VERSION "Generated from PQ35_46 ACAN KMatrix"

NS_ :

BS_:

BU_: XXX AFS Airbag Allrad AppGW_SK BAP_Tester BMS_Hybrid Bremse_ESP_AU714 Bremse_ESP_EPB_EBC460Vi Bremse_MK100_ESC Bremse_MK60EC Bremse_MK70MABS Bremse_TRW_EBC450M Bremse_TRW_ESP Daempfer EPB_TRW EPB_TRW_VW411CS ESP_AU316 FLA Gateway_PQ35 Getriebe_AG6 Getriebe_DL800_R8 Getriebe_DL800_ZSG_R8 Getriebe_DQ Getriebe_DQ_Hyb Getriebe_Sele Gurtmikro_PQ35 HCA LEH_Hybrid LH_EPS_APA LH_EPS_ZF_2G LH_EPS_ZF_3G LPG_Interface_Box LWR LWS Magne_Ride Motor_Diesel Motor_Hybrid Motor_Otto Motor_Slave PDC_PLA Quersperre_VAQ RKA_Plus SAK Waehlhebel Waehlhebel_Sele

BO_ 914 mGate_Komf_2: 8 XXX
 SG_ GK2_Sta_LSM : 0|1@1+ (1,0) [0|1] "" XXX
 SG_ GK2_Sta_Lichtsensor : 1|1@1+ (1,0) [0|1] "" AFS
 SG_ GK2_Sta_Licht1 : 2|1@1+ (1,0) [0|1] "" AFS,AppGW_SK,HCA
 SG_ GK2_Sta_VSG : 3|1@1+ (1,0) [0|1] "" Airbag,Motor_Otto,PDC_PLA
 SG_ GK2_Sta_Schluessel : 4|1@1+ (1,0) [0|1] "" Daempfer,PDC_PLA
 SG_ GK2_Sta_Profil : 5|1@1+ (1,0) [0|1] "" PDC_PLA
 SG_ GK2_Sta_Clima2 : 6|1@1+ (1,0) [0|1] "" Motor_Diesel,Motor_Otto
 SG_ GK2_Sta_BSG4 : 7|1@1+ (1,0) [0|1] "" Motor_Diesel,Motor_Otto
 SG_ GK2_Sta_Kessy_4 : 8|1@1+ (1,0) [0|1] "" Motor_Diesel,Motor_Otto
 SG_ BS4_Gleitende_Leuchtw_Anf : 9|1@1+ (1,0) [0|1] "" XXX
 SG_ BS4_GLW_Fernlicht_Anf : 10|1@1+ (1,0) [0|1] "" XXX
 SG_ GK2_Blk_L_Kontrolle : 11|1@1+ (1,0) [1|1] "" HCA
 SG_ GK2_Blk_R_Kontrolle : 12|1@1+ (1,0) [1|1] "" HCA
 SG_ LS1_Lichthupe : 13|1@1+ (1,0) [0|1] "" AFS,LWR
 SG_ GK2_LS_KomFehler : 14|1@1+ (1,0) [0|1] "" AFS
 SG_ GK2_LS_def : 15|1@1+ (1,0) [0|1] "" AFS
 SG_ GK2_Helligkeit : 16|3@1+ (714.286,0) [0|5000.002] "Unit_Lux" AFS
 SG_ GK2_VD_zu_ver : 19|1@1+ (1,0) [0|1] "" PDC_PLA
 SG_ GK2_VD_entriegelt : 20|1@1+ (1,0) [0|1] "" PDC_PLA
 SG_ GK2_VD_offen_ver : 21|1@1+ (1,0) [0|1] "" Airbag,Motor_Otto,PDC_PLA
 SG_ GK2_Verdeck_Anf : 22|1@1+ (1,0) [0|1] "" PDC_PLA
 SG_ GK2_VDKD_auf : 23|1@1+ (1,0) [0|1] "" PDC_PLA
 SG_ GK2_Schluessel : 24|4@1+ (1,0) [0|0] "" PDC_PLA
 SG_ GK2_Hardtop : 28|1@1+ (1,0) [0|1] "" PDC_PLA
 SG_ GK2_AFL_Schalter : 29|1@1+ (1,0) [0|1] "" AFS
 SG_ GK2_Nebelschluss : 30|1@1+ (1,0) [0|1] "" AFS,AppGW_SK
 SG_ GK2_EM_LIN_ungueltig : 31|1@1+ (1,0) [0|1] "" Motor_Diesel,Motor_Otto
 SG_ GK2_Profil : 32|4@1+ (1,0) [0|15] "" PDC_PLA
 SG_ GK2_Kl_StSt_Info : 36|2@1+ (1,0) [0|3] "" Motor_Diesel,Motor_Otto
 SG_ GK2_BSG_StSt_Info : 38|2@1+ (1,0) [0|3] "" Motor_Diesel,Motor_Otto
 SG_ GK2_BEM_P_Generator : 40|8@1+ (50,0) [0|12700] "Unit_Watt" Motor_Diesel,Motor_Otto
 SG_ GK2_BEM_Abschaltstufen : 48|3@1+ (1,0) [0|3] "" XXX
 SG_ GK2_BEM_DFM : 51|5@1+ (3.225,0.025) [0.025|100] "Unit_PerCent" Motor_Diesel,Motor_Otto
 SG_ GK2_Kessy_StSt_Info : 56|2@1+ (1,0) [0|3] "" Motor_Diesel,Motor_Otto
 SG_ GK2_BEM_StSt_Info : 58|2@1+ (1,0) [0|3] "" Motor_Diesel,Motor_Otto
 SG_ BEM_Segel_Info : 60|2@1+ (1,0) [0|3] "" Getriebe_AG6,Getriebe_DQ,Getriebe_DQ_Hyb,Motor_Diesel,Motor_Otto
 SG_ LS1_FAS_Taster : 62|1@1+ (1,0) [0|1] "" XXX
 SG_ LS1_Fehler_FAS_Taster : 63|1@1+ (1,0) [0|1] "" XXX

BO_ 915 mGate_Komf_3: 8 XXX
 SG_ GK3_Sta_Kessy_4 : 0|1@1+ (1,0) [0|1] "" XXX
 SG_ GK3_Sta_BCM_KY1 : 1|1@1+ (1,0) [0|1] "" XXX
 SG_ GK3_Sta_Clima_3 : 2|1@1+ (1,0) [0|1] "" Motor_Diesel,Motor_Otto
 SG_ GK3_Sta_TSG_FT_3 : 3|1@1+ (1,0) [0|1] "" XXX
 SG_ GK3_Sta_HD_1 : 4|1@1+ (1,0) [0|1] "" PDC_PLA
 SG_ GK3_Sta_Memory_1 : 5|1@1+ (1,0) [0|1] "" XXX
 SG_ GK3_Sta_BSG4 : 6|1@1+ (1,0) [0|1] "" Motor_Hybrid
 SG_ GK3_Sta_MFG1 : 7|1@1+ (1,0) [0|1] "" Bremse_MK100_ESC
 SG_ GK3_KY4_Meldungen : 8|4@1+ (1,0) [0|4] "" XXX
 SG_ GK3_KY4_Gong_600 : 12|1@1+ (1,0) [0|1] "" XXX
 SG_ MG1_ext_Last : 13|1@1+ (1,0) [0|1] "" Bremse_MK100_ESC
 SG_ GK3_KY4_PassAL_Menue : 14|1@1+ (1,0) [0|1] "" XXX
 SG_ GK3_KY4_PassAL_akt : 15|1@1+ (1,0) [0|1] "" XXX
 SG_ GK3_BK1_IDGeb_1_Sta : 16|3@1+ (1,0) [0|2] "" XXX
 SG_ GK3_BK1_IDGeb_2_Sta : 19|3@1+ (1,0) [0|2] "" XXX
 SG_ ME1_EasyEntry_Menu : 22|1@1+ (1,0) [0|1] "" XXX
 SG_ ME1_EasyEntry_aktiv : 23|1@1+ (1,0) [0|1] "" XXX
 SG_ GK3_BK1_IDGeb_3_Sta : 24|3@1+ (1,0) [0|2] "" XXX
 SG_ GK3_BK1_IDGeb_4_Sta : 27|3@1+ (1,0) [0|2] "" XXX
 SG_ GK3_BK1_Anlern_Info : 30|1@1+ (1,0) [0|1] "" XXX
 SG_ CL3_Defrost : 31|1@1+ (1,0) [0|1] "" XXX
 SG_ CL3_SH_Wasserpumpe : 32|1@1+ (1,0) [0|1] "" XXX
 SG_ FT3_Auto_eKiSi_Menu : 33|1@1+ (1,0) [0|1] "" XXX
 SG_ FT3_Auto_eKiSi_Aktiv : 34|1@1+ (1,0) [0|1] "" XXX
 SG_ MKE_Texte : 35|3@1+ (1,0) [0|2] "" XXX
 SG_ HSA_unplausibel : 38|1@1+ (1,0) [0|1] "" XXX
 SG_ FT_Kisi_Fehler : 39|1@1+ (1,0) [0|1] "" XXX
 SG_ BCM_Tankwunsch : 40|2@1+ (1,0) [0|3] "" Motor_Hybrid
 SG_ BCM_Hybrid_StartStopp_Taste : 42|1@1+ (1,0) [0|1] "" XXX
 SG_ KL_nachtr_Stopp_Anf : 43|1@1+ (1,0) [0|1] "" Motor_Diesel,Motor_Otto
 SG_ HD1_Endstellung_oben : 44|1@1+ (1,0) [0|1] "" PDC_PLA
 SG_ HD1_Endstellung_unten : 45|1@1+ (1,0) [0|1] "" PDC_PLA
 SG_ BCM_Bremslicht_defekt : 46|1@1+ (1,0) [0|1] "" XXX
 SG_ LIA_AFL_Schalter : 47|1@1+ (1,0) [0|1] "" XXX
 SG_ HD1_Position : 56|8@1+ (0.5,0) [0|100] "Unit_PerCent" PDC_PLA

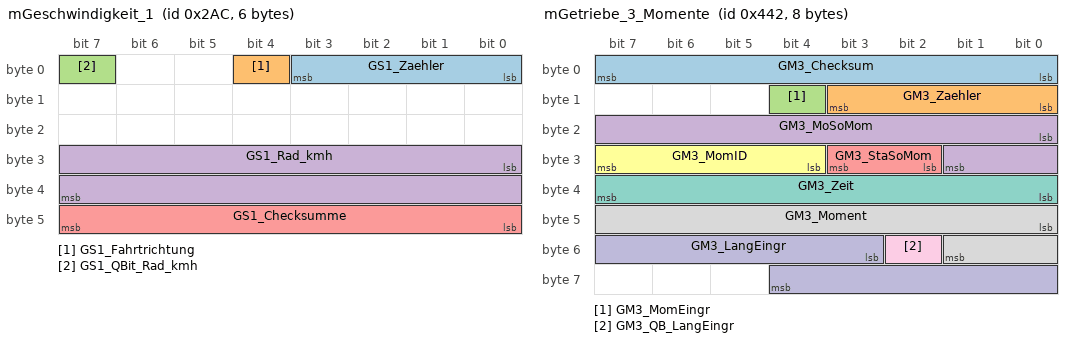
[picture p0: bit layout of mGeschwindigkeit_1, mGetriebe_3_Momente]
BO_ 684 mGeschwindigkeit_1: 6 XXX
 SG_ GS1_Zaehler : 0|4@1+ (1,0) [0|15] "" Magne_Ride
 SG_ GS1_Fahrtrichtung : 4|1@1+ (1,0) [0|1] "" XXX
 SG_ GS1_QBit_Rad_kmh : 7|1@1+ (1,0) [0|1] "" Magne_Ride
 SG_ GS1_Rad_kmh : 24|16@1+ (0.01,0) [0|654.15] "Unit_KiloMeterPerHour" Magne_Ride,SAK
 SG_ GS1_Checksumme : 40|8@1+ (1,0) [0|255] "" Magne_Ride

BO_ 1344 mGetriebe_2: 8 XXX
 SG_ GE2_LFR_Adap : 0|1@1+ (1,0) [0|1] "" Gateway_PQ35,Motor_Hybrid
 SG_ GE2_Sta_SAS : 1|1@1+ (1,0) [0|1] "" Gateway_PQ35
 SG_ GE2_LowSpeedMode_gueltig : 2|1@1+ (1,0) [0|1] "" Bremse_MK100_ESC,Bremse_MK60EC,Gateway_PQ35,Motor_Hybrid
 SG_ GE2_Sta_ZwGas : 3|1@1+ (1,0) [0|1] "" Gateway_PQ35,Motor_Hybrid
 SG_ GE2_Zaehler : 4|4@1+ (1,0) [0|15] "" Gateway_PQ35,Motor_Hybrid
 SG_ GE2_LL_Solldz : 8|8@1+ (10,0) [0|2540] "Unit_MinutInver" Gateway_PQ35,Motor_Hybrid
 SG_ GE2_Grad_begr : 16|8@1+ (10,0) [0|2540] "Unit_NewtoMeterPerSecon" Gateway_PQ35,Motor_Hybrid
 SG_ GE2_Sync_Dz : 24|8@1+ (25,0) [0|6375] "Unit_MinutInver" Gateway_PQ35,Motor_Hybrid
 SG_ GE2_invSync_Dz : 32|8@1+ (-25,6375) [0|6375] "Unit_MinutInver" Gateway_PQ35,Motor_Hybrid
 SG_ GE2_Sync_Zeit : 40|8@1+ (20,0) [0|5080] "Unit_MilliSecon" Gateway_PQ35,Motor_Hybrid
 SG_ GE2_DZM_Daempf : 48|1@1+ (1,0) [0|1] "" Gateway_PQ35
 SG_ GE2_invMSB_Sync : 49|1@1+ (1,0) [0|1] "" Gateway_PQ35
 SG_ GE2_Gong : 50|1@1+ (1,0) [0|1] "" Gateway_PQ35
 SG_ GE2_Segeln_aktiv : 51|1@1+ (1,0) [0|1] "" Gateway_PQ35,Motor_Hybrid
 SG_ GE2_Shift_Lock : 52|1@1+ (1,0) [0|1] "" Gateway_PQ35
 SG_ GE2_Senderkennung : 53|1@1+ (1,0) [0|1] "" Allrad,AppGW_SK,Gateway_PQ35
 SG_ GE2_MSB_Sync : 54|1@1+ (1,0) [0|1] "" Gateway_PQ35
 SG_ GE2_WBA_Blinken : 55|1@1+ (1,0) [0|1] "" Gateway_PQ35,Motor_Hybrid
 SG_ GE2_Variante : 56|4@1+ (1,0) [0|15] "" Allrad,AppGW_SK,Gateway_PQ35,Waehlhebel_Sele
 SG_ GE2_5Gang : 60|4@1+ (1,0) [0|8] "" Gateway_PQ35
 SG_ GE2_PRNDL : 60|4@1+ (1,0) [0|6] "" Gateway_PQ35
 SG_ GE2_4Gang : 60|4@1+ (1,0) [0|8] "" Gateway_PQ35
 SG_ GE2_ASG : 60|4@1+ (1,0) [0|12] "" Gateway_PQ35
 SG_ GE2_Selespeed : 60|4@1+ (1,0) [0|14] "" Gateway_PQ35,Waehlhebel_Sele
 SG_ GE2_res_MUX5 : 60|4@1+ (1,0) [0|15] "" Gateway_PQ35
 SG_ GE2_PRNDS : 60|4@1+ (1,0) [0|6] "" Gateway_PQ35
 SG_ GE2_PRNED : 60|4@1+ (1,0) [0|6] "" Gateway_PQ35
 SG_ GE2_Tip4Gang : 60|4@1+ (1,0) [0|5] "" Gateway_PQ35
 SG_ GE2_Tip5Gang : 60|4@1+ (1,0) [0|6] "" Gateway_PQ35
 SG_ GE2_Sollgang : 60|4@1+ (1,0) [0|10] "" AppGW_SK,Gateway_PQ35
 SG_ GE2_PRNDB : 60|4@1+ (1,0) [0|6] "" Gateway_PQ35
 SG_ GE2_Tip6Gang : 60|4@1+ (1,0) [0|7] "" Gateway_PQ35
 SG_ GE2_Tip7Gang : 60|4@1+ (1,0) [0|8] "" Gateway_PQ35
 SG_ GE2_Tip8Gang : 60|4@1+ (1,0) [0|9] "" Gateway_PQ35
 SG_ GE2_akt_Gang : 60|4@1+ (1,0) [0|14] "" AppGW_SK,Gateway_PQ35,Waehlhebel_Sele

BO_ 1090 mGetriebe_3_Momente: 8 XXX
 SG_ GM3_Checksum : 0|8@1+ (1,0) [0|255] "" Motor_Otto
 SG_ GM3_Zaehler : 8|4@1+ (1,0) [0|15] "" Motor_Otto
 SG_ GM3_MomEingr : 12|1@1+ (1,0) [0|1] "" Motor_Hybrid,Motor_Otto
 SG_ GM3_MoSoMom : 16|10@1+ (1,0) [0|1021] "Unit_NewtoMeter" Motor_Hybrid,Motor_Otto
 SG_ GM3_StaSoMom : 26|2@1+ (1,0) [0|3] "" Motor_Otto
 SG_ GM3_MomID : 28|4@1+ (1,0) [0|15] "" Motor_Otto
 SG_ GM3_Zeit : 32|8@1+ (10,0) [0|2550] "Unit_MilliSecon" Motor_Otto
 SG_ GM3_Moment : 40|10@1+ (1,0) [0|1022] "Unit_NewtoMeter" Motor_Otto
 SG_ GM3_QB_LangEingr : 50|1@1+ (1,0) [0|1] "" Motor_Otto
 SG_ GM3_LangEingr : 51|10@1+ (1,0) [0|1021] "Unit_NewtoMeter" Motor_Otto

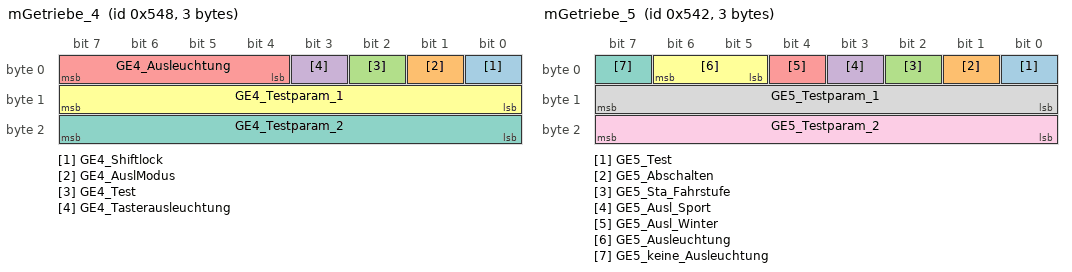
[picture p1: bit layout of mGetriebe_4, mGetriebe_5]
BO_ 1352 mGetriebe_4: 3 XXX
 SG_ GE4_Shiftlock : 0|1@1+ (1,0) [0|1] "" Waehlhebel
 SG_ GE4_AuslModus : 1|1@1+ (1,0) [0|1] "" Waehlhebel
 SG_ GE4_Test : 2|1@1+ (1,0) [0|1] "" Waehlhebel
 SG_ GE4_Tasterausleuchtung : 3|1@1+ (1,0) [0|1] "" XXX
 SG_ GE4_Ausleuchtung : 4|4@1+ (1,0) [0|15] "" Waehlhebel
 SG_ GE4_Testparam_1 : 8|8@1+ (1,0) [0|255] "" Waehlhebel
 SG_ GE4_Testparam_2 : 16|8@1+ (1,0) [0|255] "" Waehlhebel

BO_ 1346 mGetriebe_5: 3 XXX
 SG_ GE5_Test : 0|1@1+ (1,0) [0|1] "" Waehlhebel_Sele
 SG_ GE5_Abschalten : 1|1@1+ (1,0) [0|1] "" Waehlhebel_Sele
 SG_ GE5_Sta_Fahrstufe : 2|1@1+ (1,0) [0|1] "" Waehlhebel_Sele
 SG_ GE5_Ausl_Sport : 3|1@1+ (1,0) [0|1] "" Motor_Otto,Waehlhebel_Sele
 SG_ GE5_Ausl_Winter : 4|1@1+ (1,0) [0|1] "" Waehlhebel_Sele
 SG_ GE5_Ausleuchtung : 5|2@1+ (1,0) [0|3] "" Waehlhebel_Sele
 SG_ GE5_keine_Ausleuchtung : 7|1@1+ (1,0) [0|1] "" Waehlhebel_Sele
 SG_ GE5_Testparam_1 : 8|8@1+ (1,0) [0|255] "" Waehlhebel_Sele
 SG_ GE5_Testparam_2 : 16|8@1+ (1,0) [0|255] "" Waehlhebel_Sele

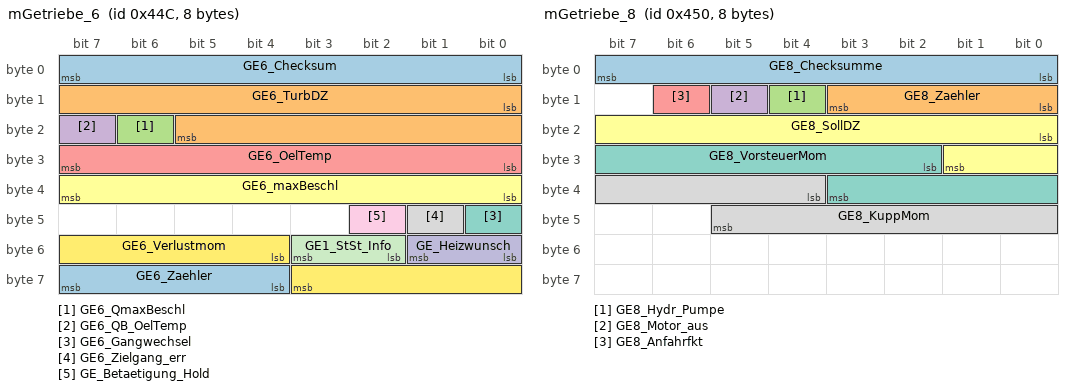
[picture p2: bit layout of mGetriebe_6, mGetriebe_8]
BO_ 1100 mGetriebe_6: 8 XXX
 SG_ GE6_Checksum : 0|8@1+ (1,0) [0|255] "" Motor_Diesel,Motor_Otto
 SG_ GE6_TurbDZ : 8|14@1+ (1,0) [0|16381] "Unit_MinutInver" Motor_Diesel,Motor_Otto
 SG_ GE6_QmaxBeschl : 22|1@1+ (1,0) [0|1] "" XXX
 SG_ GE6_QB_OelTemp : 23|1@1+ (1,0) [0|1] "" Motor_Diesel,Motor_Otto
 SG_ GE6_OelTemp : 24|8@1+ (1,-55) [-55|199] "Unit_DegreCelsi" Motor_Diesel,Motor_Otto
 SG_ GE6_maxBeschl : 32|8@1+ (0.024,-2.112) [-2.112|3.984] "Unit_MeterPerSeconSquar" XXX
 SG_ GE6_Gangwechsel : 40|1@1+ (1,0) [0|1] "" XXX
 SG_ GE6_Zielgang_err : 41|1@1+ (1,0) [0|1] "" XXX
 SG_ GE_Betaetigung_Hold : 42|1@1+ (1,0) [0|1] "" XXX
 SG_ GE_Heizwunsch : 48|2@1+ (1,0) [0|3] "" XXX
 SG_ GE1_StSt_Info : 50|2@1+ (1,0) [0|3] "" XXX
 SG_ GE6_Verlustmom : 52|8@1+ (0.39,0) [0|99.06] "Unit_PerCent" XXX
 SG_ GE6_Zaehler : 60|4@1+ (1,0) [0|15] "" Motor_Diesel,Motor_Otto

BO_ 1348 mGetriebe_7: 8 XXX
 SG_ GE7_Text_01 : 0|1@1+ (1,0) [0|1] "" Gateway_PQ35
 SG_ GE7_Text_02 : 1|1@1+ (1,0) [0|1] "" Gateway_PQ35
 SG_ GE7_Text_03 : 2|1@1+ (1,0) [0|1] "" Gateway_PQ35
 SG_ GE7_Gong : 3|1@1+ (1,0) [0|1] "" Gateway_PQ35
 SG_ GE7_Text_04 : 4|1@1+ (1,0) [0|1] "" Gateway_PQ35
 SG_ GE7_Text_05 : 5|1@1+ (1,0) [0|1] "" Gateway_PQ35
 SG_ GE7_Waehlh_ausgef : 6|1@1+ (1,0) [0|1] "" Gateway_PQ35
 SG_ GE7_Text_07 : 7|1@1+ (1,0) [0|1] "" Gateway_PQ35
 SG_ GE7_Feh_1Warn : 8|1@1+ (1,0) [0|1] "" Gateway_PQ35
 SG_ GE7_Feh_2Warn : 9|1@1+ (1,0) [0|1] "" Gateway_PQ35
 SG_ GE7_SyncWarn : 10|1@1+ (1,0) [0|1] "" Gateway_PQ35
 SG_ GE_Segeln_Menueanf : 11|1@1+ (1,0) [0|1] "" Gateway_PQ35
 SG_ GE_Segeln_Status : 12|1@1+ (1,0) [0|1] "" Gateway_PQ35
 SG_ GE7_Akustik : 13|1@1+ (1,0) [0|1] "" Gateway_PQ35
 SG_ GE7_Wegrollwarnung : 14|1@1+ (1,0) [0|1] "" Gateway_PQ35
 SG_ GE7_Temp_Warnstufe_I : 15|1@1+ (1,0) [0|1] "" Gateway_PQ35
 SG_ GE7_Text_08 : 16|1@1+ (1,0) [0|1] "" Gateway_PQ35
 SG_ GE7_Text_09 : 17|1@1+ (1,0) [0|1] "" Gateway_PQ35
 SG_ GE7_Text_10 : 18|1@1+ (1,0) [0|1] "" Gateway_PQ35
 SG_ GE7_Text_11 : 19|1@1+ (1,0) [0|1] "" Gateway_PQ35
 SG_ GE7_Text_12 : 20|1@1+ (1,0) [0|1] "" Gateway_PQ35
 SG_ GE7_Feh_3Warn : 21|1@1+ (1,0) [0|1] "" Gateway_PQ35
 SG_ GE7_Stop_Warn : 22|1@1+ (1,0) [0|1] "" Gateway_PQ35
 SG_ GE7_Feh_4Warn : 23|1@1+ (1,0) [0|1] "" Gateway_PQ35
 SG_ GE_Fahrprogramm : 24|4@1+ (1,0) [0|6] "" Gateway_PQ35
 SG_ GE_Anf_Zylinderabsch : 30|2@1+ (1,0) [0|3] "" Gateway_PQ35,Motor_Otto
 SG_ GE_Sumpftemperatur : 56|8@1+ (1,-58) [-58|196] "Unit_DegreCelsi" Gateway_PQ35,Motor_Diesel,Motor_Hybrid,Motor_Otto

BO_ 1104 mGetriebe_8: 8 XXX
 SG_ GE8_Checksumme : 0|8@1+ (1,0) [0|255] "" Motor_Otto
 SG_ GE8_Zaehler : 8|4@1+ (1,0) [0|15] "" Motor_Otto
 SG_ GE8_Hydr_Pumpe : 12|1@1+ (1,0) [0|1] "" Motor_Otto
 SG_ GE8_Motor_aus : 13|1@1+ (1,0) [0|1] "" Motor_Otto
 SG_ GE8_Anfahrfkt : 14|1@1+ (1,0) [0|1] "" Motor_Otto
 SG_ GE8_SollDZ : 16|10@1+ (10,0) [0|10230] "Unit_MinutInver" Motor_Otto
 SG_ GE8_VorsteuerMom : 26|10@1+ (1,0) [0|1023] "Unit_NewtoMeter" Motor_Otto
 SG_ GE8_KuppMom : 36|10@1+ (1,0) [0|1023] "Unit_NewtoMeter" Motor_Otto

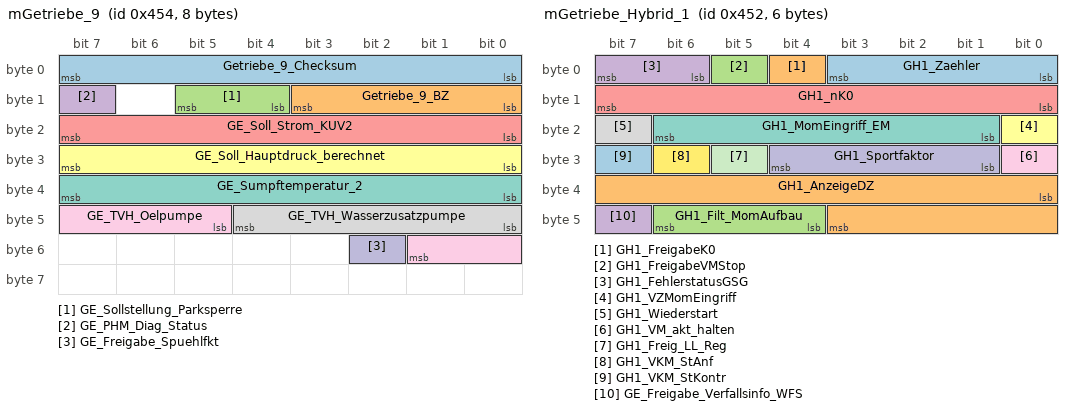
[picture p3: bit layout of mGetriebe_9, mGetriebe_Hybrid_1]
BO_ 1108 mGetriebe_9: 8 XXX
 SG_ Getriebe_9_Checksum : 0|8@1+ (1,0) [0|255] "" Getriebe_DL800_ZSG_R8
 SG_ Getriebe_9_BZ : 8|4@1+ (1,0) [0|15] "" Getriebe_DL800_ZSG_R8
 SG_ GE_Sollstellung_Parksperre : 12|2@1+ (1,0) [0|2] "" Getriebe_DL800_ZSG_R8
 SG_ GE_PHM_Diag_Status : 15|1@1+ (1,0) [0|1] "" Getriebe_DL800_ZSG_R8
 SG_ GE_Soll_Strom_KUV2 : 16|8@1+ (10,-10) [0|2530] "Unit_MilliAmper" Getriebe_DL800_ZSG_R8
 SG_ GE_Soll_Hauptdruck_berechnet : 24|8@1+ (0.1,-0.1) [0|25.3] "Unit_Bar" Getriebe_DL800_ZSG_R8
 SG_ GE_Sumpftemperatur_2 : 32|8@1+ (1,-59) [-58|195] "Unit_DegreCelsi" Getriebe_DL800_ZSG_R8
 SG_ GE_TVH_Wasserzusatzpumpe : 40|5@1+ (5,-5) [0|100] "Unit_PerCent" Getriebe_DL800_ZSG_R8
 SG_ GE_TVH_Oelpumpe : 45|5@1+ (5,-5) [0|100] "Unit_PerCent" Getriebe_DL800_ZSG_R8
 SG_ GE_Freigabe_Spuehlfkt : 50|1@1+ (1,0) [0|1] "" Getriebe_DL800_ZSG_R8

BO_ 1106 mGetriebe_Hybrid_1: 6 XXX
 SG_ GH1_Zaehler : 0|4@1+ (1,0) [0|15] "" Motor_Hybrid
 SG_ GH1_FreigabeK0 : 4|1@1+ (1,0) [0|1] "" Motor_Hybrid
 SG_ GH1_FreigabeVMStop : 5|1@1+ (1,0) [0|1] "" Motor_Hybrid
 SG_ GH1_FehlerstatusGSG : 6|2@1+ (1,0) [0|3] "" Motor_Hybrid
 SG_ GH1_nK0 : 8|8@1+ (25,0) [0|6350] "Unit_MinutInver" Motor_Hybrid
 SG_ GH1_VZMomEingriff : 16|1@1+ (1,0) [0|1] "" XXX
 SG_ GH1_MomEingriff_EM : 17|6@1+ (0.5,0) [0|31.5] "Unit_NewtoMeter" XXX
 SG_ GH1_Wiederstart : 23|1@1+ (1,0) [0|1] "" Motor_Hybrid
 SG_ GH1_VM_akt_halten : 24|1@1+ (1,0) [0|1] "" Motor_Hybrid
 SG_ GH1_Sportfaktor : 25|4@1+ (1,0) [0|0] "" Motor_Hybrid
 SG_ GH1_Freig_LL_Reg : 29|1@1+ (1,0) [0|1] "" Motor_Hybrid
 SG_ GH1_VKM_StAnf : 30|1@1+ (1,0) [0|1] "" Motor_Hybrid
 SG_ GH1_VKM_StKontr : 31|1@1+ (1,0) [0|1] "" Motor_Hybrid
 SG_ GH1_AnzeigeDZ : 32|12@1+ (3,0) [0|12282] "Unit_MinutInver" Motor_Hybrid
 SG_ GH1_Filt_MomAufbau : 44|3@1+ (1,0) [0|7] "" Motor_Hybrid
 SG_ GE_Freigabe_Verfallsinfo_WFS : 47|1@1+ (1,0) [0|1] "" XXX

BO_ 1110 mGetriebe_Zusatz_01: 8 XXX
 SG_ Getriebe_Zusatz_01_Checksum : 0|8@1+ (1,0) [0|255] "" Getriebe_DL800_R8,Motor_Otto
 SG_ Getriebe_Zusatz_01_BZ : 8|4@1+ (1,0) [0|15] "" Getriebe_DL800_R8,Motor_Otto
 SG_ GZ_OBD_Status : 12|1@1+ (1,0) [0|1] "" Motor_Otto
 SG_ GZ_PHM_Diagnose : 13|1@1+ (1,0) [0|1] "" Getriebe_DL800_R8
 SG_ GZ_Position_Parksperre : 14|2@1+ (1,0) [0|3] "" Getriebe_DL800_R8
 SG_ GZ_Kuehloeltemperatur : 16|8@1+ (1,-59) [-58|195] "Unit_DegreCelsi" Getriebe_DL800_R8
 SG_ GZ_IST_Strom_KUV2 : 24|8@1+ (10,-10) [0|2530] "Unit_MilliAmper" Getriebe_DL800_R8
 SG_ GZ_KuehlOel2_Status : 32|2@1+ (1,0) [0|2] "" Getriebe_DL800_R8
 SG_ GZ_PAV_Status : 34|2@1+ (1,0) [0|2] "" Getriebe_DL800_R8
 SG_ GZ_PEV_Status : 36|2@1+ (1,0) [0|2] "" Getriebe_DL800_R8
 SG_ GZ_PHM_Status : 38|2@1+ (1,0) [0|3] "" Getriebe_DL800_R8
 SG_ GZ_Schaltwippen_TipDown_02 : 40|2@1+ (1,0) [0|3] "" XXX
 SG_ GZ_Schaltwippen_TipUp_02 : 42|2@1+ (1,0) [0|3] "" XXX
 SG_ ZSG_Initialisierung : 55|1@1+ (1,0) [0|1] "" XXX
 SG_ GZ_Warnung : 56|3@1+ (1,0) [0|5] "" Getriebe_DL800_R8
 SG_ GZ_Oelpumpe_Status : 59|2@1+ (1,0) [0|2] "" Getriebe_DL800_R8
 SG_ GZ_Schaltwippen_TipDown : 61|1@1+ (1,0) [0|1] "" Getriebe_DL800_R8
 SG_ GZ_Schaltwippen_TipUp : 62|1@1+ (1,0) [0|1] "" Getriebe_DL800_R8
 SG_ GZ_KD_Fehler : 63|1@1+ (1,0) [0|1] "" Gateway_PQ35

BO_ 906 mGRA_Neu: 4 XXX
 SG_ GRA_Checksum : 0|8@1+ (1,0) [0|255] "" Getriebe_AG6,Motor_Diesel,Motor_Hybrid,Motor_Otto
 SG_ GRA_Hauptschalt : 8|1@1+ (1,0) [0|1] "" Getriebe_AG6,Motor_Diesel,Motor_Hybrid,Motor_Otto
 SG_ GRA_Abbrechen : 9|1@1+ (1,0) [0|1] "" Getriebe_AG6,Motor_Diesel,Motor_Hybrid,Motor_Otto
 SG_ GRA_Down_kurz : 10|1@1+ (1,0) [0|1] "" Getriebe_AG6,Getriebe_DL800_R8,Getriebe_DQ,Getriebe_DQ_Hyb,Motor_Diesel,Motor_Hybrid,Motor_Otto
 SG_ GRA_Up_kurz : 11|1@1+ (1,0) [0|1] "" Getriebe_AG6,Getriebe_DL800_R8,Getriebe_DQ,Getriebe_DQ_Hyb,Motor_Diesel,Motor_Hybrid,Motor_Otto
 SG_ GRA_Down_lang : 12|1@1+ (1,0) [0|1] "" Getriebe_AG6,Getriebe_DL800_R8
 SG_ GRA_Up_lang : 13|1@1+ (1,0) [0|1] "" Getriebe_AG6,Getriebe_DL800_R8
 SG_ GRA_Fehler_Bed : 14|1@1+ (1,0) [0|1] "" Getriebe_AG6,Motor_Diesel,Motor_Hybrid,Motor_Otto
 SG_ GRA_Kodierinfo : 15|1@1+ (1,0) [0|1] "" Getriebe_AG6,Motor_Diesel,Motor_Hybrid,Motor_Otto
 SG_ GRA_Neu_Setzen : 16|1@1+ (1,0) [0|1] "" Getriebe_AG6,Getriebe_DL800_R8,Getriebe_DQ,Getriebe_DQ_Hyb,Motor_Diesel,Motor_Hybrid,Motor_Otto
 SG_ GRA_Recall : 17|1@1+ (1,0) [0|1] "" Getriebe_AG6,Getriebe_DL800_R8,Getriebe_DQ,Getriebe_DQ_Hyb,Motor_Diesel,Motor_Hybrid,Motor_Otto
 SG_ GRA_Sender : 18|2@1+ (1,0) [0|3] "" Getriebe_AG6,Getriebe_DL800_R8,Getriebe_DQ,Getriebe_DQ_Hyb,Getriebe_Sele,Motor_Diesel,Motor_Hybrid,Motor_Otto
 SG_ GRA_Neu_Zaehler : 20|4@1+ (1,0) [0|15] "" Getriebe_AG6,Motor_Diesel,Motor_Hybrid,Motor_Otto
 SG_ GRA_Tip_Down : 24|1@1+ (1,0) [0|1] "" Getriebe_AG6,Getriebe_DL800_R8,Getriebe_DQ,Getriebe_DQ_Hyb,Getriebe_Sele,Motor_Diesel,Motor_Hybrid,Motor_Otto
 SG_ GRA_Tip_Up : 25|1@1+ (1,0) [0|1] "" Getriebe_AG6,Getriebe_DL800_R8,Getriebe_DQ,Getriebe_DQ_Hyb,Getriebe_Sele,Motor_Diesel,Motor_Hybrid,Motor_Otto
 SG_ GRA_Zeitluecke : 26|2@1+ (1,0) [0|3] "" XXX
 SG_ GRA_Limiter : 28|1@1+ (1,0) [0|1] "" Motor_Diesel,Motor_Otto
 SG_ GRA_Typ_Hauptschalt : 29|1@1+ (1,0) [0|1] "" Motor_Diesel,Motor_Hybrid,Motor_Otto
 SG_ GRA_LIM_Taste_verfuegbar : 30|1@1+ (1,0) [0|1] "" Motor_Diesel,Motor_Otto
 SG_ GRA_Fehler_Tip : 31|1@1+ (1,0) [0|1] "" Getriebe_AG6,Getriebe_DL800_R8,Getriebe_DQ,Getriebe_DQ_Hyb

BO_ 1529 mGurtmikro_1: 1 XXX
 SG_ GM_KD_Fehler : 0|1@1+ (1,0) [0|1] "" Gateway_PQ35

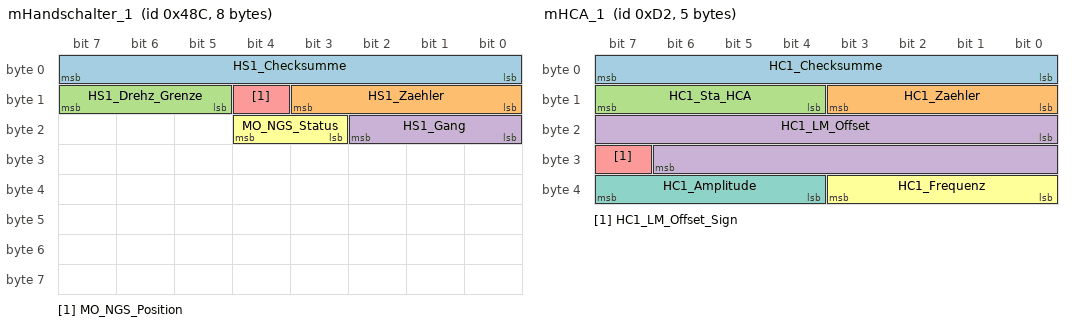
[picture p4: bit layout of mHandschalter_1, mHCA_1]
BO_ 1164 mHandschalter_1: 8 XXX
 SG_ HS1_Checksumme : 0|8@1+ (1,0) [0|255] "" Gateway_PQ35
 SG_ HS1_Zaehler : 8|4@1+ (1,0) [0|15] "" Gateway_PQ35
 SG_ HS1_Drehz_Grenze : 13|3@1+ (1,0) [0|4] "" Gateway_PQ35
 SG_ HS1_Gang : 16|3@1+ (1,0) [0|7] "" Gateway_PQ35
 SG_ MO_NGS_Position : 12|1@1+ (1,0) [0|1] "" Bremse_ESP_EPB_EBC460Vi,ESP_AU316,Gateway_PQ35
 SG_ MO_NGS_Status : 19|2@1+ (1,0) [0|3] "" Bremse_ESP_EPB_EBC460Vi,ESP_AU316,Gateway_PQ35

BO_ 210 mHCA_1: 5 XXX
 SG_ HC1_Checksumme : 0|8@1+ (1,0) [0|255] "" LH_EPS_APA,LH_EPS_ZF_2G,LH_EPS_ZF_3G
 SG_ HC1_Zaehler : 8|4@1+ (1,0) [0|15] "" LH_EPS_APA,LH_EPS_ZF_2G,LH_EPS_ZF_3G
 SG_ HC1_Sta_HCA : 12|4@1+ (1,0) [0|5] "" LH_EPS_APA,LH_EPS_ZF_2G,LH_EPS_ZF_3G
 SG_ HC1_LM_Offset : 16|15@1+ (0.0003052,0) [0|10.0004884] "Unit_NewtoMeter" LH_EPS_APA,LH_EPS_ZF_2G,LH_EPS_ZF_3G
 SG_ HC1_LM_Offset_Sign : 31|1@1+ (1,0) [0|1] "" LH_EPS_APA,LH_EPS_ZF_2G,LH_EPS_ZF_3G
 SG_ HC1_Frequenz : 32|4@1+ (4,0) [0|60] "Unit_Hertz" LH_EPS_APA,LH_EPS_ZF_2G,LH_EPS_ZF_3G
 SG_ HC1_Amplitude : 36|4@1+ (0.5,0) [0|7.5] "Unit_NewtoMeter" LH_EPS_APA,LH_EPS_ZF_2G,LH_EPS_ZF_3G

BO_ 1512 mKlima_EV_1: 8 XXX
 SG_ KL_HV_ein : 0|1@1+ (1,0) [0|1] "" XXX
 SG_ KL_Innengeblaese : 1|1@1+ (1,0) [0|1] "" XXX
 SG_ KL_PTC_Pumpe_Soll : 2|4@1+ (10,0) [0|100] "Unit_PerCent" XXX
 SG_ KL_Beschlagsgefahr : 6|1@1+ (1,0) [0|1] "" XXX
 SG_ KL_Standklima_RemoteModus : 7|3@1+ (1,0) [0|7] "" XXX
 SG_ KL_Wake_Up_ACAN : 12|1@1+ (1,0) [0|1] "" XXX
 SG_ KL_HV_Anf : 13|1@1+ (1,0) [0|1] "" XXX
 SG_ KL_Ventil_Batterie_Anf : 14|1@1+ (1,0) [0|1] "" XXX
 SG_ KL_Ventil_vor_Motor_Anf : 15|1@1+ (1,0) [0|1] "" XXX
 SG_ PTC_Strom : 16|8@1+ (0.25,0) [0|63.5] "Unit_Amper" XXX
 SG_ EKK_Strom : 24|8@1+ (0.25,0) [0|63.5] "Unit_Amper" Motor_Hybrid
 SG_ KL_Kompr_Drehzahl_Soll : 32|8@1+ (50,0) [0|8600] "Unit_MinutInver" XXX
 SG_ EKK_Status : 40|1@1+ (1,0) [0|1] "" XXX
 SG_ KL_Standklima_Status_02 : 41|3@1+ (1,0) [0|7] "" XXX
 SG_ PTC_Pumpe_Ist : 44|4@1+ (10,0) [0|100] "Unit_PerCent" XXX
 SG_ PTC_Pumpe_Status : 48|2@1+ (1,0) [0|3] "" XXX
 SG_ KL_Charisma_FahrPr : 50|3@1+ (1,0) [0|7] "" XXX
 SG_ KL_Charisma_Status : 53|2@1+ (1,0) [0|3] "" XXX
 SG_ EKK_Status_Vorstrg : 55|1@1+ (1,0) [0|1] "" XXX
 SG_ KL_Vorwarn_HVHeizer_Leistung : 56|4@1+ (1,0) [0|15] "" XXX

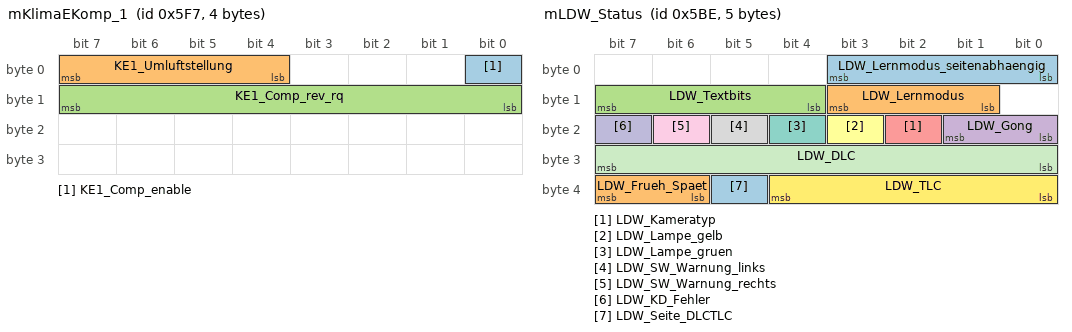
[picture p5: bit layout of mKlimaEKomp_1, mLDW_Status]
BO_ 1527 mKlimaEKomp_1: 4 XXX
 SG_ KE1_Comp_enable : 0|1@1+ (1,0) [0|1] "" XXX
 SG_ KE1_Umluftstellung : 4|4@1+ (10,0) [0|100] "Unit_PerCent" XXX
 SG_ KE1_Comp_rev_rq : 8|8@1+ (50,0) [0|8600] "Unit_MinutInver" XXX

BO_ 800 mKombi_1: 8 XXX
 SG_ KO1_SleepInd : 0|1@1+ (1,0) [0|1] "" XXX
 SG_ KO1_Sta_Tank : 1|1@1+ (1,0) [0|1] "" Motor_Diesel,Motor_Hybrid,Motor_Otto
 SG_ KO1_Oeldruck : 2|1@1+ (1,0) [0|1] "" Motor_Diesel,Motor_Hybrid,Motor_Otto
 SG_ KO1_Sta_Oeldr : 3|1@1+ (1,0) [0|1] "" AppGW_SK
 SG_ KO1_Kuehlmittel : 4|1@1+ (1,0) [0|1] "" AppGW_SK,Motor_Diesel,Motor_Otto
 SG_ KO1_Wakeup_Komfort : 5|1@1+ (1,0) [0|1] "" XXX
 SG_ KO1_Warn_Tank : 6|1@1+ (1,0) [0|1] "" AppGW_SK,Motor_Diesel,Motor_Otto
 SG_ KO1_Vorgluehen : 7|1@1+ (1,0) [0|1] "" Motor_Diesel
 SG_ KO1_Bremsinfo : 8|1@1+ (1,0) [0|1] "" XXX
 SG_ KO1_Handbremse : 9|1@1+ (1,0) [0|1] "" Airbag,Allrad,AppGW_SK,Bremse_ESP_AU714,Bremse_MK100_ESC,Bremse_MK60EC,Bremse_MK70MABS,Getriebe_AG6,Getriebe_DL800_R8,Getriebe_DQ,Getriebe_DQ_Hyb,Getriebe_Sele,LH_EPS_APA,LH_EPS_ZF_2G,LH_EPS_ZF_3G,Motor_Diesel,Motor_Hybrid,Motor_Otto,RKA_Plus
 SG_ KO1_La_Ladekon : 10|1@1+ (1,0) [0|1] "" XXX
 SG_ KO1_Stellglieder : 11|1@1+ (1,0) [0|1] "" Airbag,LH_EPS_ZF_2G,LH_EPS_ZF_3G,Motor_Diesel
 SG_ KO1_Zeitluecke : 12|3@1+ (1,0) [0|7] "" XXX
 SG_ KO1_Tankstop : 15|1@1+ (1,0) [1|1] "" XXX
 SG_ KO1_Tankinhalt : 16|7@1+ (1,0) [0|126] "Unit_Liter" AppGW_SK,Motor_Diesel,Motor_Hybrid,Motor_Otto
 SG_ KO1_OBD_Tank : 23|1@1+ (1,0) [0|1] "" Motor_Diesel,Motor_Hybrid,Motor_Otto
 SG_ KO1_Quelle_kmh : 24|1@1+ (1,0) [0|1] "" Motor_Otto
 SG_ KO1_kmh : 25|15@1+ (0.01,0) [0|326] "Unit_KiloMeterPerHour" Airbag,AppGW_SK,LH_EPS_ZF_2G,LH_EPS_ZF_3G,LWR
 SG_ KO1_Zaehler : 40|4@1+ (1,0) [0|15] "" Getriebe_AG6,HCA
 SG_ KO1_ACC_Inkons : 44|1@1+ (1,0) [0|1] "" XXX
 SG_ KO1_ACC_AnzFhl : 45|1@1+ (1,0) [0|1] "" XXX
 SG_ KO1_angez_kmh : 46|10@1+ (0.32,0) [0|325.76] "Unit_KiloMeterPerHour" Airbag,AppGW_SK,Getriebe_AG6,Getriebe_DL800_R8,Getriebe_DQ,Getriebe_DQ_Hyb,HCA,Motor_Diesel,Motor_Otto,RKA_Plus
 SG_ KO1_kmh_mph : 56|1@1+ (1,0) [0|1] "" Getriebe_AG6,Getriebe_DL800_R8,Getriebe_DQ,Getriebe_DQ_Hyb,Motor_Diesel,Motor_Otto
 SG_ KO1_ABS_Lampe : 57|1@1+ (1,0) [0|1] "" XXX
 SG_ KO1_ASRESP_Lampe : 58|1@1+ (1,0) [0|1] "" XXX
 SG_ KO1_Brems_Lampe : 59|1@1+ (1,0) [0|1] "" XXX
 SG_ KO1_Airbag_Lampe : 60|1@1+ (1,0) [0|1] "" Airbag
 SG_ KO1_Lenkh_Lampe : 61|1@1+ (1,0) [0|1] "" LH_EPS_APA,LH_EPS_ZF_2G,LH_EPS_ZF_3G
 SG_ KO1_LDW_AnzFeh : 62|1@1+ (1,0) [0|1] "" HCA
 SG_ KO1_SILA_gueltig : 63|1@1+ (1,0) [0|1] "" Airbag,LH_EPS_APA,LH_EPS_ZF_2G,LH_EPS_ZF_3G

BO_ 1470 mLDW_Status: 5 XXX
 SG_ LDW_Lernmodus_seitenabhaengig : 0|4@1+ (1,0) [0|15] "" Gateway_PQ35
 SG_ LDW_Lernmodus : 9|3@1+ (1,0) [0|4] "" Gateway_PQ35
 SG_ LDW_Textbits : 12|4@1+ (1,0) [0|5] "" Gateway_PQ35
 SG_ LDW_Gong : 16|2@1+ (1,0) [0|2] "" Gateway_PQ35
 SG_ LDW_Kameratyp : 18|1@1+ (1,0) [0|1] "" Gateway_PQ35
 SG_ LDW_Lampe_gelb : 19|1@1+ (1,0) [0|1] "" Gateway_PQ35
 SG_ LDW_Lampe_gruen : 20|1@1+ (1,0) [0|1] "" Gateway_PQ35
 SG_ LDW_SW_Warnung_links : 21|1@1+ (1,0) [0|1] "" Gateway_PQ35
 SG_ LDW_SW_Warnung_rechts : 22|1@1+ (1,0) [0|1] "" Gateway_PQ35
 SG_ LDW_KD_Fehler : 23|1@1+ (1,0) [0|1] "" Gateway_PQ35
 SG_ LDW_DLC : 24|8@1+ (0.01,-1.25) [-1.25|1.25] "Unit_Meter" Gateway_PQ35
 SG_ LDW_TLC : 32|5@1+ (0.1,0) [0|3] "Unit_Secon" Gateway_PQ35
 SG_ LDW_Seite_DLCTLC : 37|1@1+ (1,0) [0|1] "" Gateway_PQ35
 SG_ LDW_Frueh_Spaet : 38|2@1+ (1,0) [0|3] "" Gateway_PQ35

BO_ 976 mLenkhilfe_1: 6 XXX
 SG_ LH1_Lastinfo : 0|7@1+ (1,0) [0|127] "Unit_Amper" Gateway_PQ35,PDC_PLA
 SG_ LH1_Fehler_LI : 7|1@1+ (1,0) [0|1] "" Gateway_PQ35
 SG_ LH1_Sicherheitslamp : 8|1@1+ (1,0) [0|1] "" AppGW_SK,Gateway_PQ35
 SG_ LH1_Fehlerlampe : 9|1@1+ (1,0) [0|1] "" AppGW_SK,Gateway_PQ35
 SG_ LH1_Textbits : 10|3@1+ (1,0) [0|4] "" Gateway_PQ35
 SG_ LH1_Akustiksign : 13|1@1+ (1,0) [0|1] "" Gateway_PQ35
 SG_ LH1_SleepInd : 14|1@1+ (1,0) [0|1] "" Gateway_PQ35
 SG_ LH1_Fehlereintr : 15|1@1+ (1,0) [0|1] "" Gateway_PQ35
 SG_ LH1_EPS_Diagmode : 16|1@1+ (1,0) [0|1] "" Gateway_PQ35
 SG_ LH1_gue_ECU_Temp : 19|1@1+ (1,0) [0|1] "" Gateway_PQ35
 SG_ LH1_Kuehlung : 20|1@1+ (1,0) [0|1] "" Gateway_PQ35
 SG_ LH1_Mode_Hybrid : 21|1@1+ (1,0) [0|1] "" Gateway_PQ35
 SG_ LH1_NL_Untersp : 24|1@1+ (1,0) [1|1] "" Gateway_PQ35
 SG_ LH1_NL_Uebersp : 25|1@1+ (1,0) [1|1] "" Gateway_PQ35
 SG_ LH1_NL_Uebertemp : 26|1@1+ (1,0) [1|1] "" Gateway_PQ35
 SG_ LH1_NL_Sensor : 27|1@1+ (1,0) [1|1] "" Gateway_PQ35
 SG_ LH1_NL_CAN_SS : 28|1@1+ (1,0) [1|1] "" Gateway_PQ35
 SG_ LH1_NL_ECU : 29|1@1+ (1,0) [1|1] "" Gateway_PQ35
 SG_ LH1_NL_Motor : 30|1@1+ (1,0) [1|1] "" Gateway_PQ35
 SG_ LH1_NL_LeistDichte : 31|1@1+ (1,0) [1|1] "" Gateway_PQ35
 SG_ LH1_ULeistung : 32|8@1+ (0.5,0) [0|100] "Unit_PerCent" Gateway_PQ35,PDC_PLA
 SG_ LH1_ECU_Temp : 40|8@1+ (1,-70) [-70|185] "Unit_DegreCelsi" Gateway_PQ35

BO_ 398 mLPG_01: 8 XXX
 SG_ LPG_01_Reserve : 0|64@1+ (1,0) [0|0] "" Motor_Otto

BO_ 654 mLPG_02: 8 XXX
 SG_ LPG_02_Reserve : 0|64@1+ (1,0) [0|0] "" Motor_Otto

BO_ 655 mLPG_03: 8 XXX
 SG_ LPG_03_Reserve : 0|64@1+ (1,0) [0|0] "" Motor_Otto

BO_ 658 mLPG_04: 8 XXX
 SG_ LPG_04_Reserve : 0|64@1+ (1,0) [0|0] "" Motor_Otto

BO_ 916 mLWR_Zustand: 8 XXX
 SG_ LRZ_Parameter : 0|1@1+ (1,0) [0|1] "" Gateway_PQ35
 SG_ LRZ_Grundeinst : 1|1@1+ (1,0) [0|1] "" Gateway_PQ35
 SG_ LRZ_Modus : 2|1@1+ (1,0) [0|1] "" Gateway_PQ35
 SG_ LRZ_Initlauf : 3|1@1+ (1,0) [0|1] "" Gateway_PQ35
 SG_ LRZ_Sichere_Pos : 4|1@1+ (1,0) [0|1] "" Gateway_PQ35
 SG_ LRZ_LampeAFS : 5|1@1+ (1,0) [0|1] "" Gateway_PQ35
 SG_ LRZ_Fehlerlampe : 6|1@1+ (1,0) [0|1] "" Gateway_PQ35
 SG_ LRZ_Fehler : 7|1@1+ (1,0) [0|1] "" Gateway_PQ35
 SG_ LRZ_Einfedg_vo : 8|8@1+ (1,-127) [-127|126] "Unit_MilliMeter" Bremse_MK60EC,Gateway_PQ35,RKA_Plus
 SG_ LRZ_Einfedg_hi : 16|8@1+ (1,-127) [-127|126] "Unit_MilliMeter" Bremse_MK60EC,Gateway_PQ35,RKA_Plus
 SG_ LRZ_Stellung : 24|8@1+ (0.4,0) [0|100] "Unit_PerCent" Gateway_PQ35
 SG_ LRZ_LeistDim : 32|8@1+ (0.4,50) [50|150] "Unit_PerCent" Gateway_PQ35
 SG_ LRZ_ELF_links : 40|1@1+ (1,0) [0|1] "" Gateway_PQ35
 SG_ LRZ_ELF_rechts : 41|1@1+ (1,0) [0|1] "" Gateway_PQ35
 SG_ LRZ_AFSLED_Blink : 42|1@1+ (1,0) [0|1] "" Gateway_PQ35
 SG_ LRZ_AFSFehlertext : 43|1@1+ (1,0) [0|1] "" Gateway_PQ35
 SG_ LRZ_Tourist_Fkt : 44|1@1+ (1,0) [0|1] "" Gateway_PQ35
 SG_ LRZ_Tourist_aktiv : 45|1@1+ (1,0) [0|1] "" Gateway_PQ35
 SG_ LRZ_AFS_Absch : 46|1@1+ (1,0) [0|1] "" Gateway_PQ35
 SG_ LRZ_AFS_deaktiv : 47|1@1+ (1,0) [0|1] "" Gateway_PQ35
 SG_ LRZ_Abbiegelicht_Dimm_Anf : 48|1@1+ (1,0) [0|1] "" Gateway_PQ35
 SG_ LRZ_Abbiegelicht_li_Anf : 49|1@1+ (1,0) [0|1] "" Gateway_PQ35
 SG_ LRZ_Abbiegelicht_re_Anf : 50|1@1+ (1,0) [0|1] "" Gateway_PQ35
 SG_ LRZ_Fernlicht_li_defekt : 51|1@1+ (1,0) [0|1] "" Gateway_PQ35
 SG_ LRZ_Fernlicht_re_defekt : 52|1@1+ (1,0) [0|1] "" Gateway_PQ35
 SG_ LRZ_Fernlicht_Status : 53|1@1+ (1,0) [0|1] "" Gateway_PQ35
 SG_ LRZ_Verfuegbarkeit_GLW : 54|1@1+ (1,0) [0|1] "" Gateway_PQ35
 SG_ LRZ_Status_adaptive_LV : 55|1@1+ (1,0) [0|1] "" Gateway_PQ35
 SG_ GLW_Sensor_blockiert : 56|1@1+ (1,0) [0|1] "" Gateway_PQ35
 SG_ AFS_Abblendlicht_li_defekt : 58|1@1+ (1,0) [0|1] "" Gateway_PQ35
 SG_ AFS_Abblendlicht_re_defekt : 59|1@1+ (1,0) [0|1] "" Gateway_PQ35
 SG_ LRZ_Zaehler : 60|4@1+ (1,0) [0|15] "" Gateway_PQ35

BO_ 1423 mMotor_12: 8 XXX
 SG_ MO_ITM_Kuehlmittel_Temp : 0|8@1+ (0.75,-48) [-45.75|143.25] "Unit_DegreCelsi" Gateway_PQ35
 SG_ M12_E85_Sensor : 8|4@1+ (10,0) [0|100] "Unit_PerCent" Gateway_PQ35
 SG_ M12_SCR_Anz_Motorstarts : 12|4@1+ (1,0) [0|13] "" Gateway_PQ35
 SG_ M12_SCR_Reichweite : 16|15@1+ (1,0) [0|32766] "Unit_KiloMeter" Gateway_PQ35
 SG_ SCR_Tankdeckel : 31|1@1+ (1,0) [0|1] "" Gateway_PQ35
 SG_ M12_SCR_Warnstufe_1 : 32|1@1+ (1,0) [1|1] "" Gateway_PQ35
 SG_ M12_SCR_Warnstufe_2 : 33|1@1+ (1,0) [1|1] "" Gateway_PQ35
 SG_ M12_SCR_Text : 34|3@1+ (1,0) [0|7] "" Gateway_PQ35
 SG_ M12_Akustik : 37|2@1+ (1,0) [0|3] "" Gateway_PQ35
 SG_ M12_Luftfilter_Lampe : 39|1@1+ (1,0) [0|1] "" Gateway_PQ35
 SG_ M12_Kraftstofffilter_Wasser : 40|1@1+ (1,0) [0|1] "" Gateway_PQ35
 SG_ M12_SCR_Systemfehler : 41|1@1+ (1,0) [1|1] "" Gateway_PQ35
 SG_ M12_SCR_Inducement : 42|2@1+ (1,0) [0|1] "" Gateway_PQ35
 SG_ M12_CO2_Faktor : 44|12@1+ (1,0) [1|4094] "Unit_GramPerLiter" Gateway_PQ35
 SG_ M12_MKB_MUX : 56|2@1+ (1,0) [0|3] "" Gateway_PQ35,SAK
 SG_ MO_EDK_Luefter_defekt : 58|1@1+ (1,0) [0|1] "" Gateway_PQ35
 SG_ M12_MKB_01 : 59|5@1+ (1,0) [0|31] "" Gateway_PQ35
 SG_ M12_MKB_02 : 59|5@1+ (1,0) [0|31] "" Gateway_PQ35
 SG_ M12_MKB_03 : 59|5@1+ (1,0) [0|31] "" Gateway_PQ35
 SG_ M12_MKB_04 : 59|5@1+ (1,0) [0|31] "" Gateway_PQ35,SAK

BO_ 1450 mMotor_13: 8 XXX
 SG_ MO_NMAX_Schaltanzeige : 0|9@1+ (25,0) [0|12775] "Unit_MinutInver" Gateway_PQ35
 SG_ MO_Ethanol_BS_Texte : 9|3@1+ (1,0) [0|6] "" Gateway_PQ35
 SG_ MO_Heizungspumpenansteuerung : 12|4@1+ (10,0) [0|100] "Unit_PerCent" Gateway_PQ35
 SG_ MO_Nachlaufzeit_Heizungspumpe : 16|6@1+ (15,0) [0|945] "Unit_Secon" Gateway_PQ35
 SG_ MO_Absperrventil_oeffnen : 22|2@1+ (1,0) [0|3] "" Gateway_PQ35
 SG_ MO_aktives_Getriebeheizen : 24|1@1+ (1,0) [0|1] "" Gateway_PQ35
 SG_ MO_Getriebe_kuehlen : 25|1@1+ (1,0) [0|1] "" Gateway_PQ35
 SG_ MO_Zustand_HWP : 26|2@1+ (1,0) [0|3] "" Gateway_PQ35
 SG_ MO_BKV_Unterdruckwarnung : 28|1@1+ (1,0) [0|1] "" Gateway_PQ35
 SG_ MO_Zylinderabschaltung : 30|2@1+ (1,0) [0|3] "" ESP_AU316,Gateway_PQ35,Getriebe_DQ
 SG_ MO_Heizstrom_SCR : 32|6@1+ (1,0) [0|62] "Unit_Amper" Gateway_PQ35
 SG_ MO_Heizstrom_EKAT : 38|7@1+ (1,0) [0|126] "Unit_Amper" Gateway_PQ35
 SG_ MO_Tankklappenstatus : 45|3@1+ (1,0) [0|7] "" Gateway_PQ35
 SG_ MO_Tankklappensteuerung : 48|2@1+ (1,0) [0|3] "" Gateway_PQ35
 SG_ MO_Zylabsch_Texte_02 : 50|4@1+ (1,0) [0|15] "" Gateway_PQ35
 SG_ MO_EFLEX_Lampe : 54|2@1+ (1,0) [0|3] "" Gateway_PQ35
 SG_ MO_Testmode_AG : 56|1@1+ (1,0) [0|1] "" Gateway_PQ35
 SG_ MO_Ext_E_Fahrt_aktiv : 57|1@1+ (1,0) [0|1] "" Gateway_PQ35
 SG_ MO_E85_WU_Lampe : 58|1@1+ (1,0) [0|1] "" Gateway_PQ35
 SG_ MO_E85_WU_Texte : 59|1@1+ (1,0) [0|1] "" Gateway_PQ35
 SG_ MO_Zylabsch_Texte : 60|2@1+ (1,0) [0|3] "" Gateway_PQ35
 SG_ MO_E85_BS_Texte : 62|2@1+ (1,0) [0|3] "" Gateway_PQ35
 SG_ MO_StartStopp_Codiert : 29|1@1+ (1,0) [0|1] "" Bremse_ESP_EPB_EBC460Vi,ESP_AU316,Gateway_PQ35

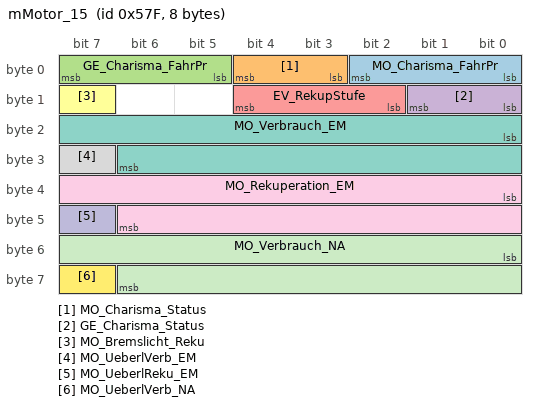
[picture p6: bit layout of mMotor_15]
BO_ 1407 mMotor_15: 8 XXX
 SG_ MO_Charisma_FahrPr : 0|3@1+ (1,0) [0|7] "" XXX
 SG_ MO_Charisma_Status : 3|2@1+ (1,0) [0|3] "" XXX
 SG_ GE_Charisma_FahrPr : 5|3@1+ (1,0) [0|7] "" XXX
 SG_ GE_Charisma_Status : 8|2@1+ (1,0) [0|3] "" XXX
 SG_ EV_RekupStufe : 10|3@1+ (1,0) [0|5] "" XXX
 SG_ MO_Bremslicht_Reku : 15|1@1+ (1,0) [0|1] "" Gateway_PQ35
 SG_ MO_Verbrauch_EM : 16|15@1+ (1,0) [0|32767] "Unit_MilliWattHour" XXX
 SG_ MO_UeberlVerb_EM : 31|1@1+ (1,0) [0|1] "" XXX
 SG_ MO_Rekuperation_EM : 32|15@1+ (1,0) [0|32767] "Unit_MilliWattHour" XXX
 SG_ MO_UeberlReku_EM : 47|1@1+ (1,0) [0|1] "" XXX
 SG_ MO_Verbrauch_NA : 48|15@1+ (1,0) [0|32767] "Unit_MilliWattHour" XXX
 SG_ MO_UeberlVerb_NA : 63|1@1+ (1,0) [0|1] "" XXX

CM_ SG_ 914 GK2_Sta_LSM "LSM-Botschaft wird nicht empfangen (200 ms) | Das integrierte Gateway (BCM) sendet dauerhaft \"0\", da es ggf. fuer die genannten Signale Originalsender ist! | | Zykluszeit der Quellbotschaft [ms]: 100 | | Veraltet Bit fuer die Signale: | | Botschaft mGate_Komf_1: | Byte 5, Bit 2 GK1_Blinker_li | Byte 5, Bit 3 GK1_Blinker_re | Byte 5, Bit 4 GK1_def_P_verr | Byte 5, Bit 5 GK1_LS1_Fernlicht | | Botschaft mGate_Komf_2: | Byte 2, Bit 5 LS1_Lichthupe | Byte 8, Bit 6 LS1_FAS_Taster | Byte 8, Bit 7 LS1_Fehler_FAS_Taster";
CM_ SG_ 914 GK2_Sta_Lichtsensor "mLichtsensor_1 - Botschaft nicht empfangen (100 msec) oder mRegen_Licht_Sensor-Botschaft nicht empfangen (200 msec) | Das integrierte Gateway (BCM) sendet dauerhaft \"0\", da es ggf. fuer die genannten Signale Originalsender ist! | | Zykluszeit der Quellbotschaft [ms]: 100 | | Veraltet Bit fuer die Signale: | | Botschaft mGate_Komf_2: | Byte 2, Bit 6 GK2_LS_KomFehler | Byte 2, Bit 7 GK2_LS_def | Byte 3, Bit 0..2 GK2_Helligkeit";
CM_ SG_ 914 GK2_Sta_Licht1 "Licht-Botschaft nicht empfangen (100 ms) | Das integrierte Gateway (BCM) sendet dauerhaft \"0\", da es ggf. fuer die genannten Signale Originalsender ist! | | Zykluszeit der Quellbotschaft [ms]: 50 | | Veraltet Bit fuer die Signale: | | Botschaft mGate_Komf_1: | Byte 1, Bit 6 LIA_Standlicht | Byte 4, Bit 4 GK1_Rueckfahr | Byte 7, Bit 0 GK1_Abblendlicht | Byte 7, Bit 1 GK1_Fernlicht | Byte 7, Bit 7 GK1_Warnblk_Status | Byte 8, Bit 2 GK1_Nebel_ein | Byte 8, Bit 3 GK1_Bremslicht | | Botschaft mGate_Komf_2: | Byte 2, Bit 3 GK2_Blk_L_Kontrolle | Byte 2, Bit 4 GK2_Blk_R_Kontrolle | Byte 4, Bit 5 GK2_AFL_Schalter | Byte 4, Bit 6 GK2_Nebelschluss";
CM_ SG_ 914 GK2_Sta_VSG "VSG - Botschaft nicht empfangen (200 msec) | Das integrierte Gateway (BCM) sendet bei manuellem Verdeck dauerhaft \"0\", da es ggf. fuer die genannten Signale Originalsender ist! | | Zykluszeit der Quellbotschaft [ms]: 100 | | Veraltet Bit fuer die Signale: | | Botschaft mGate_Komf_2: | Byte 3, Bit 3 GK2_VD_zu_ver | Byte 3, Bit 4 GK2_VD_entriegelt | Byte 3, Bit 5 GK2_VD_offen_ver | Byte 3, Bit 6 GK2_Verdeck_Anf | Byte 3, Bit 7 GK2_VDKD_auf | Byte 4, Bit 4 GK2_Hardtop";
CM_ SG_ 914 GK2_Sta_Schluessel "Botschaft fuer Fahrberechtigungsschluessel (Verweis auf Wegfahrsperre) nicht empfangen (200 msec)";
CM_ SG_ 914 GK2_Sta_Profil "Botschaft fuer Profilnummer nicht empfangen (mEinheiten, 2000 msec) | | Zykluszeit der Quellbotschaft [ms]: 1000 | | Veraltet Bit fuer die Signale: | | Botschaft mGate_Komf_2: | Byte 5, Bit 0..3 GK2_Profil";
CM_ SG_ 914 GK2_Sta_Clima2 "mClima2-Botschaft nicht empfangen (1600 ms) | | Zykluszeit der Quellbotschaft [ms]: 800 | | Veraltet Bit fuer die Signale: | | Botschaft mGate_Komf_2: | Byte 5, Bit 4..5 GK2_Kl_StSt_Info";
CM_ SG_ 914 GK2_Sta_BSG4 "mBSG4-Botschaft nicht empfangen (1000ms) | Das integrierte Gateway (BCM) sendet dauerhaft \"0\", da es ggf. fuer die genannten Signale Originalsender ist! | | Zykluszeit der Quellbotschaft [ms]: 500 | | Veraltet Bit fuer die Signale: | | Botschaft mGate_Komf_2: | Byte 2, Bit 1 BS4_Gleitende_Leuchtw_Anf | Byte 2, Bit 2 BS4_GLW_Fernlicht_Anf | Byte 5, Bit 6..7 GK2_BSG_StSt_Info";
CM_ SG_ 914 GK2_Sta_Kessy_4 "mKessy_4-Botschaft nicht empfangen (400 msec) (PQ35, PQ25) | mELV_Kessy_WFS-Botschaft nicht empfangen (200msec) (VW47x)";
CM_ SG_ 914 BS4_Gleitende_Leuchtw_Anf "Funktion \"Gleitende Leuchtweite\" im AFS-SG freischalten";
CM_ SG_ 914 BS4_GLW_Fernlicht_Anf "Harte Fernlichtanforderung von BCM an die Funktion \"gleitende Leuchtweite\" im AFS-SG";
CM_ SG_ 914 GK2_Blk_L_Kontrolle "1 = Kontrollampe Blinker links ein | 0 = Kontrollampe Blinker links aus | Ansteuerung Blinkerkontrollampe links";
CM_ SG_ 914 GK2_Blk_R_Kontrolle "1 = Kontrollampe Blinker rechts ein | 0 = Kontrollampe Blinker rechts aus | Ansteuerung Blinkerkontrollampe rechts";
CM_ SG_ 914 LS1_Lichthupe "Lichthupe ein";
CM_ SG_ 914 GK2_LS_KomFehler "Veraltetinformation. Der LIN Master setzt dieses Bit, wenn er aktuell keine Daten vom Slave erhalten hat. (z.B. Hochlauf, Nachlauf, Kommunikationsfehler) | Lin Information veraltet";
CM_ SG_ 914 GK2_LS_def "Lichtsensor ist defekt. Signal wird vom Master gesetzt, wenn keine Daten vom Lichtsensor bei aktiver Kommunikation vorliegen";
CM_ SG_ 914 GK2_Helligkeit "Signale bilden die Helligkeit, die der Lichtsensor empfaengt | Helligkeitsinformation in LUX";
CM_ SG_ 914 GK2_VD_zu_ver "1 = Zustand des Verdecks verriegelt und geschlossen";
CM_ SG_ 914 GK2_VD_entriegelt "Verrriegeltzustand des Verdeck bzw. des Verdeckkastendeckel (VDKD)";
CM_ SG_ 914 GK2_VD_offen_ver "1 = Zustand des Verdecks geoeffnet und abgelegt (In Ablage verriegelt)";
CM_ SG_ 914 GK2_Verdeck_Anf "1 = Verdeck nicht in den Zustaenden 'geschlossen verriegelt' oder 'offen verriegelt'";
CM_ SG_ 914 GK2_VDKD_auf "Signal wird gesetzt, wenn der Verdeckkastendeckel vollstaendig geoeffnet ist";
CM_ SG_ 914 GK2_Schluessel "0 = ungueltig, xxxx = Schluessel-Nr. | Schluesselinformation (s. Kombi_3)";
CM_ SG_ 914 GK2_Hardtop "1 = Hardtop ist montiert";
CM_ SG_ 914 GK2_AFL_Schalter "1 = Schalter in Stellung Assistenzfahrlicht";
CM_ SG_ 914 GK2_Nebelschluss "1 = Nebelschlusslicht eingeschaltet | Kl83b Nebelschlussleuchte ein | PQ25: Das Signal wird nur bei verbautem BCM-Licht aktiv bedient";
CM_ SG_ 914 GK2_EM_LIN_ungueltig "Energie-Lin-Signale sind ungueltig vom Slave Batteriedatenmodul oder Generator | 0 = Signale gueltig | 1 = Signale ungueltig";
CM_ SG_ 914 GK2_Profil "aktuelle Profilnummer";
CM_ SG_ 914 GK2_Kl_StSt_Info "Stopp-Freigabe/Start-Anforderung fuer den Start-Stopp-Koordinator";
CM_ SG_ 914 GK2_BSG_StSt_Info "Stopp-Freigabe/Start-Anforderung fuer den Start-Stopp-Koordinator";
CM_ SG_ 914 GK2_BEM_P_Generator "Mechanische Generatorleistung dient dem Motorsteuergeraet zur Berechnung der Motorlast; Genauigkeit ca. +/- (500W + 20% vom Messwert)";
CM_ SG_ 914 GK2_BEM_Abschaltstufen "Abschaltstufen des Ruhestrommanagements (Initialisierungswert aus EEprom) | 0 = Stufe 0 (keine Einschraenkungen) | 1 = Stufe 1 | 2 = Stufe 2 | 3 = Stufe 3";
CM_ SG_ 914 GK2_BEM_DFM "Generatorauslastungsgrad, vom Generator ueber LIN an das Gateway gesandt. Das Motorsteuergeraet regelt auf dieses Signal die PTC, das Energiemanagement im BSG/BCM kalkuliert die Bordnetzauslastung";
CM_ SG_ 914 GK2_Kessy_StSt_Info "Stopp-Freigabe/Start-Anforderung fuer den Start-Stopp-Koordinator | Wert 1: | - Schluessel nicht gefunden bei KL15=EIN | - Transponderstart | - Antennenfehler (Kessy defekt)";
CM_ SG_ 914 GK2_BEM_StSt_Info "Stopp-Freigabe/Start-Anforderung fuer den Start-Stopp-Koordinator";
CM_ SG_ 914 BEM_Segel_Info "0: keine Anforderung | (Segeln ist ohne Einschaenkung erlaubt) | 1: Mindestdrehzahl 1 | (Segeln ist mit Einschaenkung erlaubt) | 2: Mindestdrehzahl 2 | (Segeln ist mit Einschaenkung erlaubt) | 3: Segelveto | (Segeln ist nicht erlaubt)";
CM_ SG_ 914 LS1_FAS_Taster "1 = Bedientaster fuer Fahrerassistenzsysteme betaetigt";
CM_ SG_ 914 LS1_Fehler_FAS_Taster "Fehler in Bedientaster fuer Fahrerassistenzsysteme";
CM_ SG_ 915 GK3_Sta_Kessy_4 "mKessy_4-Botschaft nicht empfangen (400 msec) | | Zykluszeit der Quellbotschaft [ms]: 200 | | Veraltet Bit fuer die Signale: | | Botschaft mGate_Komf_3: | Byte 2, Bit 0..3 GK3_KY4_Meldungen | Byte 2, Bit 4 GK3_KY4_Gong_600 | Byte 2, Bit 6 GK3_KY4_PassAL_Menue | Byte 2, Bit 7 GK3_KY4_PassAL_akt";
CM_ SG_ 915 GK3_Sta_BCM_KY1 "Das integrierte Gateway (BCM) sendet dauerhaft \"0\", da es ggf. fuer die genannten Signale Originalsender ist! | | Veraltet Bit fuer die Signale: | | Botschaft mGate_Komf_3: | Byte 3, Bit 0..2 GK3_BK1_IDGeb_1_Sta | Byte 3, Bit 3..5 GK3_BK1_IDGeb_2_Sta | Byte 4, Bit 0..2 GK3_BK1_IDGeb_3_Sta | Byte 4, Bit 3..5 GK3_BK1_IDGeb_4_Sta | Byte 4, Bit 6 GK3_BK1_Anlern_Info";
CM_ SG_ 915 GK3_Sta_Clima_3 "Zykluszeit der Quellbotschaft [ms]: 200 | | Veraltet Bit fuer die Signale: | | Botschaft mGate_Komf_3: | Byte 5, Bit 0 CL3_SH_Wasserpumpe | Byte 6, Bit 3 KL_nachtr_Stopp_Anf";
CM_ SG_ 915 GK3_Sta_TSG_FT_3 "Das integrierte Gateway (BCM) sendet dauerhaft \"0\", da es ggf. fuer die genannten Signale Originalsender ist! | | Zykluszeit der Quellbotschaft [ms]: 100 | | Veraltet Bit fuer die Signale: | | Botschaft mGate_Komf_3: | Byte 5, Bit 1 FT3_Auto_eKiSi_Menu | Byte 5, Bit 2 FT3_Auto_eKiSi_Aktiv | Byte 5, Bit 7 FT_Kisi_Fehler";
CM_ SG_ 915 GK3_Sta_HD_1 "Veraltet-Bit fuer Botschaft mHeckdeckel_1 (400ms nicht empfangen) | | Zykluszeit der Quellbotschaft [ms]: 200 | | Veraltet Bit fuer die Signale: | | Botschaft mGate_Komf_3: | Byte 6, Bit 4 HD1_Endstellung_oben | Byte 6, Bit 5 HD1_Endstellung_unten | Byte 8, Bit 0..7 HD1_Position";
CM_ SG_ 915 GK3_Sta_Memory_1 "mMemory_1-Botschaft nicht empfangen (1000ms) | | Zykluszeit der Quellbotschaft [ms]: 500 | | Veraltet Bit fuer die Signale: | | Botschaft mGate_Komf_3: | Byte 3, Bit 6 ME1_EasyEntry_Menu | Byte 3, Bit 7 ME1_EasyEntry_aktiv";
CM_ SG_ 915 GK3_Sta_BSG4 "mBSG4-Botschaft nicht empfangen (1000ms) | Das integrierte Gateway (BCM) sendet dauerhaft \"0\", da es ggf. fuer die genannten Signale Originalsender ist! | | Zykluszeit der Quellbotschaft [ms]: 500 | | Veraltet Bit fuer die Signale: | | Botschaft mGate_Komf_3: | Byte 6, Bit 0..1 BCM_Tankwunsch | Byte 6, Bit 2 BCM_Hybrid_StartStopp_Taste";
CM_ SG_ 915 GK3_Sta_MFG1 "1 = Botschaft mMFG_1 nicht empfangen (>200 ms)";
CM_ SG_ 915 GK3_KY4_Meldungen "Kessy-Meldungen: | 0 = keine Meldung | 1 = Meldung: \"Schluessel nicht gefunden!\" bei Kl.15 ein | 2= Meldung: \"Schluessel im Kofferraum!\" | 3 = Meldung: \"Schluessel im Fahrzeug\" | 4 = Meldung: \"KESSY defekt\" | 5-15: tbd";
CM_ SG_ 915 GK3_KY4_Gong_600 "Gong zum Meldungstext (1=aktiv)";
CM_ SG_ 915 MG1_ext_Last "Das MFG bietet fuer Sonderfahrzeuge einen elektischen Ausgang. Wird an diesem Ausgang eine elektrische Last erkannt, so wird dieser Zustand erkannt und ausgegeben.";
CM_ SG_ 915 GK3_KY4_PassAL_Menue "1 = Menue-Eintrag \"Passiv Autolock / Autounlock\" aktivieren";
CM_ SG_ 915 GK3_KY4_PassAL_akt "1 = Funktionszustand im Kessy-SG: \"Passiv Autolock / Autounlock\"";
CM_ SG_ 915 GK3_BK1_IDGeb_1_Sta "ID Geber 1 Status Authentifizierung (0 = keine Antwort, 1 = authentifiziert, 2 = UHF Antwort, aber nicht authentifiziert, 3 - 7 tbd.)";
CM_ SG_ 915 GK3_BK1_IDGeb_2_Sta "ID Geber 2 wurde authentifiziert (0 = keine Antwort, 1 = authentifiziert, 2 = UHF Antwort, aber nicht authentifiziert, 3 - 7 tbd.)";
CM_ SG_ 915 ME1_EasyEntry_Menu "Easy-Entry-Funktion im Memorysitz verfuegbar/nicht verfuegbar";
CM_ SG_ 915 ME1_EasyEntry_aktiv "Rueckmeldung vom Sitz-Memory-SG an das Kombi-SG (MFA), dass die Easy-Entry-Funktion fuer den Memorysitz aktiviert wurde.";
CM_ SG_ 915 GK3_BK1_IDGeb_3_Sta "ID Geber 3 wurde authentifiziert (0 = keine Antwort, 1 = authentifiziert, 2 = UHF Antwort, aber nicht authentifiziert, 3 - 7 tbd.)";
CM_ SG_ 915 GK3_BK1_IDGeb_4_Sta "ID Geber 4 wurde authentifiziert (0 = keine Antwort, 1 = authentifiziert, 2 = UHF Antwort, aber nicht authentifiziert, 3 - 7 tbd.)";
CM_ SG_ 915 GK3_BK1_Anlern_Info "1 = Anlernfunkschuss empfangen, Ergebnis in Byte 1+2 der mBCM_Kessy_1-Botschaft.";
CM_ SG_ 915 CL3_Defrost "1 = ein | Status Defrost";
CM_ SG_ 915 CL3_SH_Wasserpumpe "Anforderung zur Ansteuerung der SH- Wasserpunmpe im Restwaermebetrieb; 1 = Wasserpumpe ein; 0 = aus";
CM_ SG_ 915 MKE_Texte "Systemhinweis und Sicherheitshinweis fuer Anzeige im Kombi";
CM_ SG_ 915 HSA_unplausibel "Ueberblendung der Schaltanzeige im Kombi: vom Motorsteuergeraet gesendete Informationen zur Darstellung der Schaltanzeige unplausibel";
CM_ SG_ 915 BCM_Tankwunsch "VW361/7: Tankwunsch (Fahrer betaetigt Tankdeckeltaster)";
CM_ SG_ 915 BCM_Hybrid_StartStopp_Taste "Betaetigung Taster \"Hybrid\" oder alternativ Taster \"Start/Stopp Deaktivierung\", je nach Verbau";
CM_ SG_ 915 KL_nachtr_Stopp_Anf "Dieses Signal dient dem Motor als Trigger, dass ein nachtraeglicher Motorstopp eingeleitet werden kann, wenn es die Bedingungen des StSt Koordinators dies zulassen.";
CM_ SG_ 915 HD1_Endstellung_oben "Botschaft wird nur bei verbautem Heckdeckel-SG gesendet. Der Heckdeckel befindet sich in der Endstellung bei offener Heckklappe.";
CM_ SG_ 915 HD1_Endstellung_unten "Der Heckdeckel befindet sich in der Endstellung bei geschlossener Heckklappe.";
CM_ SG_ 915 BCM_Bremslicht_defekt "Das BCM PQ25 kann ein defektes Bremslicht nicht eindeutig zuordnen. | Daher wird hier eine allgemeine Defekterkennung uebermittelt.";
CM_ SG_ 915 LIA_AFL_Schalter "1 = Schalter in Stellung Assistenzfahrlicht";
CM_ SG_ 915 HD1_Position "Dieses Byte zeigt die Oeffnung des Heckdeckels in Prozent | VW428: Sonderwert 0xC8 kennzeichnet die obere Endlage oder eine nicht normierte Heckklappe.";
CM_ SG_ 684 GS1_Zaehler "Definition nach CAN-Lastenheft | ACHTUNG: Bedienung der gesamten CAN-Botschaft nur in den Audi-Varianten der entsprechenden Bremse (TTNF, AB2, R8)";
CM_ SG_ 684 GS1_Fahrtrichtung "Fahrtrichtung";
CM_ SG_ 684 GS1_QBit_Rad_kmh "Definition nach CAN-Lastenheft | Qualifizierungsbit Geschwindigkeit";
CM_ SG_ 684 GS1_Rad_kmh "Low Byte 4, High Byte 5 | Bremse holt sich den Radumfang aus der Botschaft 'Kombi_3' | ESP 5.7: Ausgegeben wird die Geschwindigkeit des linken Vorderrades | ESP 8 Quattro: 4 Raeder | ESP 8 Front: 2 Raeder VA | Bei MSR oder ASR-Eingriffen wird fuer >=200ms die ABS-Referenzgeschwindigkeit eingespiegelt. | Konstanten: | V_INIT = FF88h entspricht 654,16 km/h | V_Uspg = FFAAh entspricht 654,50 km/h | V_Fehler = FFCCh entspricht 654,84 km/h | V_Ref_na = FF99h entspricht 654,33 km/h";
CM_ SG_ 684 GS1_Checksumme "Pruefsumme mit Endwert 0x0, Definition im CAN Lastenheft (HS-CAN V4.2a, LS-CAN V1.42)";
CM_ SG_ 1344 GE2_LFR_Adap "Da das VL30-Getriebe im Stillstand unter gewissen Randbedingungen wechselnde Kupplungsmomente einstellt (z.B. Hillholder), sollte die Leerlauffuellungsadaption im Motorsteuergeraet fuer diese Zustaende gesperrt werden | | Falls Senderkennung = 1 (MSG): Bedienung mit Initwert | LFR-Adaption Freigabeflag";
CM_ SG_ 1344 GE2_Sta_SAS "Wenn die SAS-Unterstuetzung aktiv ist, wird vom VL30-Steuergeraet sichergestellt, dass die Kupplung nicht schlagartig geoeffnet wird. | | Falls Senderkennung = 1 (MSG): Bedienung mit Initwert | Schubabschaltunterstuetzung";
CM_ SG_ 1344 GE2_LowSpeedMode_gueltig "(war 'Ecomatic') | alter Signalname: GE2_SlipStDZEingr | | Hybrid: | PQ35H/VW019: Verwendung fuer DZ-Eingriff Low-Speed-Mode (LSM)";
CM_ SG_ 1344 GE2_Sta_ZwGas "Byte 4,5 und 6 sollen ausgefuehrt werden | | Hybrid: | Falls Bit 3 aktiv, dann sollen Byte 4, 5 und 6 ausgefuehrt werden. | - falls Bit 3 und Bit 2 aktiv: DZ-Vorgabe von Getriebe im Low-Speed-Modus (s. Byte 7 Bit 3 (Motor_Hybrid_1)). | - Falls Bit 3 aktiv und Bit 2 nicht aktiv: ZG-Eingriff. | | Falls Senderkennung = 1 (MSG): Bedienung mit Initwert | Zwischengasflag";
CM_ SG_ 1344 GE2_Zaehler "Ueberwachung von Byte 4 und 5 | Zaehler laeuft synchron mit Zaehler in Getriebe 1 | Bedienung unabhaengig von Senderkennung | Botschaftszaehler (Getriebe 2)";
CM_ SG_ 1344 GE2_LL_Solldz "Wunschvorgabewert vom CVT Getriebe, 5HP19, 5HP24 und ASG an Motor | | Hybrid: | Getriebe kann auch im Low-Speed-Modus Verbrenner-LLSoll-DZ anfordern (Spiegelung Byte 6 aus Motor 2) | | Falls Senderkennung = 1 (MSG): Bedienung mit Initwert | Leerlaufsolldrehzahl (Getriebe 2)";
CM_ SG_ 1344 GE2_Grad_begr "Drehmomenten-Gradientenbegrenzung fuer Teillastanfahrten mit dem VL30-Getriebe und Standabkopplung beim 5HP19 | | Hybrid (Signal 'Gradientenbegrenzung Summenmoment'): | Soll fuer Summenmoment VM + EM gelten. Soll auch negative Gradienten (Rekuperation) gelten! | | Falls Senderkennung = 1 (MSG): Bedienung mit Initwert | Gradientenbegrenzung";
CM_ SG_ 1344 GE2_Sync_Dz "Drehzahlverhalten zu Schaltvorgang | (Bei Selespeed-Getriebe im AU714 groesserer Wertebereich 0-8128 mit Aufloesung 32/min) | | Hybrid: | ASG-Drehschnittstelle soll bei Hybrid implementiert sein. | Neu: Soll auch tauglich sein fuer DZ-reduzierende Eingriffe! | | Falls Senderkennung = 1 (MSG): Bedienung mit Initwert | Synchronisations-Wunschdrehzahl";
CM_ SG_ 1344 GE2_invSync_Dz "bitinvertiertes Byte 4 | (Bei Selespeed-Getriebe im AU714 groesserer Wertebereich 0-8128 mit Aufloesung 32/min) | | Hybrid: | ASG-Drehschnittstelle soll bei Hybrid implementiert sein. | Neu: Soll auch tauglich sein fuer DZ-reduzierende Eingriffe! | Falls Senderkennung = 1 (MSG): Bedienung mit Initwert | invertierte Synchronisations Wunschdrehz.";
CM_ SG_ 1344 GE2_Sync_Zeit "Falls Senderkennung = 1 (MSG): Bedienung mit Initwert | Synchronisationszeit";
CM_ SG_ 1344 GE2_DZM_Daempf "Beim Getriebe kann die Anzeigedaempfung des Drehzahlmessers beim Schalten geaendert werden | Falls Senderkennung = 1 (MSG): Bedienung mit Initwert | Drehzahlmesserdaempfung";
CM_ SG_ 1344 GE2_invMSB_Sync "(war: 'Starter wird angesteuert') | bitinvertiertes Byte 7, Bit 6 | Falls Senderkennung = 1 (MSG): Bedienung mit 0 | Invertiertes MSB Synchronisations Wunschdrehzahl";
CM_ SG_ 1344 GE2_Gong "Wichtiger Warnhinweis vom Getriebe: | Textanzeige Kupplungstemperaturwarnung fuer DQ-Getriebe: \"Getriebe ueberhitzt Stopp Bordbuch\" | (VW Text-ID: ID_TXT_2029.0) | Falls Senderkennung = 1 (MSG): Bedienung mit Initwert | Gong / Kupplungstemperaturwarnung";
CM_ SG_ 1344 GE2_Segeln_aktiv "(war 'Unterdrueckung von Warnungen') | Getriebe geht in den Segelbetrieb, Antriebsstrang offen | Falls Senderkennung = 1 (MSG): Bedienung mit Initwert";
CM_ SG_ 1344 GE2_Shift_Lock "Waehlhebel ist durch Shift-Lock Funktion blockiert | Falls Senderkennung = 1 (MSG): Bedienung mit Initwert | Shift-Lock-Lampe";
CM_ SG_ 1344 GE2_Senderkennung "(war 'ECO-Anzeige') | Die Botschaft Getriebe 2 wird vom Automatgetriebe gesendet, bei Handschaltern alternativ vom Motor. Das Getriebe stellt damit die Waehlbereichsanzeige dar, der Motor beim Handschalter die Hochschaltaufforderung fuer den Fahrer im Kombi. Zur Unterscheidung der Anzeigestrategie des Senders fuer das Kombi wird deswegen eine Information benoetigt, die den jeweiligen Sender kennzeichnet. | Anhand des Senders aendert sich die Bedeutung der Inhalte der Botschaft, weil funktional verschieden. | 0x0 = Getriebe, MSG im E-Fahrzeug | 0x1 = Motor bei Handschalter-Fzg. mit Hochschaltempfehlung";
CM_ SG_ 1344 GE2_MSB_Sync "(war: 'Anforderung Kriechadaptionsmodus');Bei gesetztem Bit sind zu der Synchronisationswunschdrehzahl in Byte 4 6400 /min (Selespeed 8192) zu addieren. Inverses Bit in Byte 7, Bit 1 beachten | Falls Senderkennung = 1 (MSG): Bedienung mit Initwert | MSB Synchronisations Wunschdrehzahl";
CM_ SG_ 1344 GE2_WBA_Blinken "Dieses Bit steuert die Fehlerlampe an oder wird zum Blinken der WBA-Anzeige genutzt (5HP, 6HP, PNG, ASG, VL30) | Falls Senderkennung = 1 (MSG): Bedienung mit Initwert | Fehlerlampe fuer Kupplung / WBA Blinken";
CM_ SG_ 1344 GE2_Variante "Falls Senderkennung = 0 (GSG): Ganganzeige Kombi Getriebe Variante und eingelegter Gang: | vgl. Multiplex-Information. Uebertragung 4x Getriebe-Variante (0x0 bis 0xE moeglich, 0xA Sollgang bei Tipschaltempf.), danach 4x der aktuell eingelegte Gang (0xF) | | Falls Senderkennung = 1 (MSG): Istgang | Wenn Motor die Botschaft sendet wird in diesem Signal der aktuelle Gang ausgegeben (= Istgang des Schaltgetriebes): | 0x0: kein Gang eingelegt | 0x1: 1. Gang | 0x2: 2. Gang | 0x3: 3. Gang | 0x4: 4. Gang | 0x5: 5. Gang | 0x6: 6. Gang";
CM_ SG_ 1344 GE2_5Gang "5-Gang Automat (PRND432)";
CM_ SG_ 1344 GE2_PRNDL "Automat (PRNDL) ohne Tipgasse";
CM_ SG_ 1344 GE2_4Gang "4-Gang Automat (PRND321)";
CM_ SG_ 1344 GE2_ASG "ASG-Getriebe";
CM_ SG_ 1344 GE2_Selespeed "Selespeed-Getriebe | Besonderheit Selespeed: | 0000: Es wird nur ein M angezeigt. Diese Anzeige erfolgt, wenn das Getriebe keine Gangposition bestimmen kann. Selespeed besitzt keine Normaldarstellung wie ein echter Automat. Die Fahrstufen M/S/A sind zueinander kombinierbar, im Defaultzustand steht nur ein 'M' in der Anzeige zum Kombi. | 0001: Es wird nur ein M angezeigt. Die Anzeige ist komplett invertiert. Anzeige fuer Getriebefehler und Notlauf | **: N bei eingelegter Gang ist bei Selespeed erforderlich, weil 'N' gleichzeitig zu 'M', 'A' angezeigt wird | Time Out CAN (500 msec): Display aus (keine Darstellung von Ziffern) | kein Eintrag in Tabelle gefunden oder im Display nicht darstellbar: siehe Kombi-Lastenheft (z.B. Anzeige hell) | Time Out CAN (500 msec): Display aus (keine Darstellung von Ziffern) | kein Eintrag in Tabelle gefunden oder im Display nicht darstellbar: siehe Kombi-Lastenheft (z.B. Anzeige hell)";
CM_ SG_ 1344 GE2_res_MUX5 "reserviert fuer Multiplexer Signal 5";
CM_ SG_ 1344 GE2_PRNDS "Automat (PRNDS) (4/5/6-Gang)";
CM_ SG_ 1344 GE2_PRNED "Automat (PRNED) (4/5/6-Gang)";
CM_ SG_ 1344 GE2_Tip4Gang "4 Gang Automat Tiptronic";
CM_ SG_ 1344 GE2_Tip5Gang "5 Gang Automat Tiptronic (auch im 3l Auto)";
CM_ SG_ 1344 GE2_Sollgang "Signalisiert den Sollgang, in den getippt werden soll. Abhaengig vom Signal \"GE2_akt_Gang\" und dem Sollgang kann dann das Kombi die Hochschaltempfehlung in Tip darstellen.";
CM_ SG_ 1344 GE2_PRNDB "fuer EGolf (Sender Motor)";
CM_ SG_ 1344 GE2_Tip6Gang "6 Gang Automat Tiptronic";
CM_ SG_ 1344 GE2_Tip7Gang "7 Gang Automat Tiptronic";
CM_ SG_ 1344 GE2_Tip8Gang "8 Gang Automat Tiptronic";
CM_ SG_ 1344 GE2_akt_Gang "Falls Senderkennung = 0 (GSG): aktuell eingelegter Gang/Fahrstufe bei Automatik-Getrieben | vgl. Wertetabelle | | nur Selespeed und DL800 im Audi R8: | 0xD: N ist eingelegt | nur DL800 im Audi R8: | 0xE: P ist eingelegt | | Falls Senderkennung = 1 (MSG): Motor sendet bei Handschaltern den Sollgang (Signal wird hierbei nicht von GE2_Variante gemuxt), in den der Fahrer schalten soll. Wird im Kombi als Hochschaltempfehlung hervorgehoben: | 0x0: keine Anzeige (bzw. keine Schaltempfehlung) | 0x1: 1. Gang (empfohlen) | 0x2: 2. Gang (empfohlen) | 0x3: 3. Gang (empfohlen) | 0x4: 4. Gang (empfohlen) | 0x5: 5. Gang (empfohlen) | 0x6: 6. Gang (empfohlen)";
CM_ SG_ 1090 GM3_Checksum "Pruefsumme mit Endwert 0x0, Definition im CAN Lastenheft (HS-CAN V4.2a, LS-CAN V1.42)";
CM_ SG_ 1090 GM3_Zaehler "Freilaufender Botschaftszaehler | Zaehler (Getriebe_3_Momente)";
CM_ SG_ 1090 GM3_MomEingr "Freigabe-Bit z. Zt. nur fuer Luftpfad-Eingriff gueltig: \"Eine moeglichr Anforderung Momentenreduktion fuer Hochschaltungen kann umgesetzt werden\", Naeheres im Lastenheft Luftpfad | | Hybrid: | PQ35H: parallel zu Byte 1 Bit 7 aus Getriebe 1. | Freigabe Momenteneingriffsanforderung";
CM_ SG_ 1090 GM3_MoSoMom "Hybrid: | Getriebeeingriff auf indiziertes Moment (Absolutwert). | - Reduzierendes Moment kann auch von EM erzeugt werden => Eingriff beinhaltet auch EMAnteile. | - Erhoehendes Moment kann auch von EM erzeugt werden => Eingriff beinhaltet auch EM-Anteile. | Motorsollmoment, Getriebeeingriff";
CM_ SG_ 1090 GM3_StaSoMom "Status Sollmoment";
CM_ SG_ 1090 GM3_MomID "Zur Identifizierung der Moment-Zeit-Paare";
CM_ SG_ 1090 GM3_Zeit "Zeit des Moment-Zeit-Paares";
CM_ SG_ 1090 GM3_Moment "Moment des Moment-Zeit-Paares;Anmerkung: Der Faktor zur Normierung der Momente (0,25, 0,5, 1, 2) wird zukuenftig aus der \"Motor_Momente\"-Botschaft entnommen (vorruebergehend 1)";
CM_ SG_ 1090 GM3_QB_LangEingr "Definition nach CAN Lastenheft | Qualifizierungsbit Langfristiger Eingriff";
CM_ SG_ 1090 GM3_LangEingr "Getriebeschutzmoment | Langfristiger Eingriff";
CM_ SG_ 1352 GE4_Shiftlock "Shiftlockaktivierung";
CM_ SG_ 1352 GE4_AuslModus "Bei RDW ist die Ausleuchtungsdauer begrenzt (Waehlhebel nicht in P) | Ausleuchtungsmodus fuer Waehlhebel";
CM_ SG_ 1352 GE4_Test "Controllertest mit den Testparametern 1 + 2 durchfuehren | Testfreigabeflag";
CM_ SG_ 1352 GE4_Tasterausleuchtung "Ansteuerung der Ausleuchtung des WH Tasters z.B. S-Taste";
CM_ SG_ 1352 GE4_Ausleuchtung "Mit dieser Botschaft wird die aktive Istgangausleuchtung des Waehlhebels gesteuert. | Waehlhebelausleuchtung";
CM_ SG_ 1352 GE4_Testparam_1 "Testparameter 1 zum Funktionstest des Waehlhebel-Controllers";
CM_ SG_ 1352 GE4_Testparam_2 "Testparameter 2 zum Funktionstest des Waehlhebel-Controllers";
CM_ SG_ 1346 GE5_Test "Controllertest mit den Testparametern 1+2 durchfuehren | Testfreigabeflag";
CM_ SG_ 1346 GE5_Abschalten "Mit diesem Bit kann das Getriebe den Waehlhebel im Fehlerfall deaktivieren. Der Waehlhebel geht dann in einen Standby-Modus. Alle Waehlhebelanzeigen blinken. | Waehlhebelmodul abschalten";
CM_ SG_ 1346 GE5_Sta_Fahrstufe "Kann das Getriebe keine Information ueber die aktuell eingelegte Fahrstufe an den Waehlhebel uebergeben, so wird dieses Bit gesetzt. Am Waehlhebel wird keine Fahrstufe angezeigt, solange das Bit gesetzt ist. | Fahrstufeninformation ungueltig";
CM_ SG_ 1346 GE5_Ausl_Sport "Mit dieser Bit wird Ausleuchtung der Sportfunktion am Waehlhebel gesteuert | Waehlhebelausleuchtung Sport";
CM_ SG_ 1346 GE5_Ausl_Winter "Mit dieser Botschaft wird Ausleuchtung der Winterfunktion am Waehlhebel gesteuert | Waehlhebelausleuchtung Winter";
CM_ SG_ 1346 GE5_Ausleuchtung "Mit dieser Botschaft wird die aktive Istgangausleuchtung des Waehlhebels gesteuert. | Waehlhebelausleuchtung Istgang";
CM_ SG_ 1346 GE5_keine_Ausleuchtung "Mit diesem Signal kann die Istgang-Ausleuchtung des WH abgeschaltet werden.";
CM_ SG_ 1346 GE5_Testparam_1 "Testparameter 1 zum Funktionstest des Waehlhebel-Controllers";
CM_ SG_ 1346 GE5_Testparam_2 "Testparameter 2 zum Funktionstest des Waehlhebel-Controllers";
CM_ SG_ 1100 GE6_Checksum "Pruefsumme mit Endwert 0x0, Definition im CAN Lastenheft (HS-CAN V4.2a, LS-CAN V1.42)";
CM_ SG_ 1100 GE6_TurbDZ "Zur Verbesserung des Lastschlagverhaltens beim Schaltvorgang | Turbinendrehzahl";
CM_ SG_ 1100 GE6_QmaxBeschl "Definition im CAN Lastenheft | Qualifizierungsbit max. Beschleunigung";
CM_ SG_ 1100 GE6_QB_OelTemp "Definition im CAN Lastenheft | Qualifizierungsbit Getriebeoeltemperatur";
CM_ SG_ 1100 GE6_OelTemp "Getriebeoeltemperatur";
CM_ SG_ 1100 GE6_maxBeschl "max. Beschleunigung Getriebe fuer Audi ACC-Projekte";
CM_ SG_ 1100 GE6_Gangwechsel "Das Bit wird gesetzt, wenn das Bit \"Schaltung aktiv\" gesetzt ist und der Betrag der Differenz zwischen dem Produkt aus Getriebeausgangsdrehzahl und Uebersetzung des Istgangs und der Getriebeeingangsdrehzahl einen getriebeseitig applizierbaren Schwellwert ueberschreitet. Das Bit wird zurueckgesetzt mit der positiven Flanke von \"Zielgang erreicht\", wenn keine Weiterschaltung erfolgt, sonst mit der positiven Flanke von \"Zielgang erreicht\" des letzten Gangwechsels. Sonderfall Schaltung im Stand: Das Bit \"Gangwechsel\" ist fuer diesen Fall nicht relevant. | (nicht PQ35/46)";
CM_ SG_ 1100 GE6_Zielgang_err "Das Bit wird gesetzt, wenn der Betrag der Differenz zwischen Getriebeeingangsdrehzahl und Produkt aus Getriebeausgangsdrehzahl und Uebersetzung des Zielgangs einen getriebeseitig applizierbaren Schwellwert unterschreitet. Das Bit wird zurueckgesetzt, wenn das Bit \"Schaltung aktiv\" gesetzt wird (Beginn der naechsten Schaltung). Sonderfall Mehrfachschaltung: Im Falle einer Mehrfachschaltung erfolgt das Ruecksetzen des Bits \"Zielgang erreicht\" entweder zeitgesteuert oder ueber die Bedingung fuer die positive Flanke des Bits Gangwechsel\". Sonderfall Schaltung im Stand: Das Bit \"Zielgang erreicht\" muss in diesem Fall spaetestens mit dem Zuruecksetzen des Bits \"Schaltung aktiv\" gesetzt sein. | (nicht PQ35/46)";
CM_ SG_ 1100 GE_Betaetigung_Hold "Anforderung des Getriebes zum Aktivieren der Holdfunktion, bei aktiver Anfahrunterstuetzung";
CM_ SG_ 1100 GE_Heizwunsch "(nur AU716)";
CM_ SG_ 1100 GE1_StSt_Info "Stopp-Freigabe/Start-Anforderung fuer den Start-Stopp-Koordinator | (Verriegelt ueber Systemstatus Start/Stopp wegen ESP8 bei AUDI und ggf. alter Motoren: Getriebe darf nur einen Wert ungleich 0 senden, wenn mMotor_10 empfangen wurde und der \"Systemstatus Start Stopp\" ungleich 0 ist.) | [falls Position in mGetriebe_1: | Bit 5 war: \"Leerlaufsolldrehzahl-Anhebung\" (z.B. Erhoehung des Pumpendrucks beim CVT-Getriebe) | Bit 6 war: \"Kodierung im MSG\" (Getriebe-Kodierung im Motor-Steuergeraet ist in Ordnung)] | [falls Position in mGetriebe_6: nur im AU716!]";
CM_ SG_ 1100 GE6_Verlustmom "gesamtes Verlustmoment von Zentralgetriebe incl. Vorderachsdifferential (und Zentraldifferential / Verteilergetriebe bei quattro) Nutzung im ACC, GRA und Triebstrangkoordinator im Motor (nur AU716 und D3, nicht fuer andere Projekte verwenden!) | Getriebeverlustmoment ACC/GRA";
CM_ SG_ 1100 GE6_Zaehler "Freilaufender Botschaftszaehler | Zaehler (Getriebe_6)";
CM_ SG_ 1348 GE7_Text_01 "Bit schaltet Textmeldung im Kombi als Fahrerhinweis: | | Selespeed: Wenn die Kupplungsschutzfunktion des Getriebes aktiv ist, wird ueber diesen Text der Fahrer informiert. | | SQ100: \"Zum Aussteigen bitte Motor abstellen oder N waehlen und Handbremse anziehen\"";
CM_ SG_ 1348 GE7_Text_02 "Bit schaltet Textmeldung im Kombi als Fahrerhinweis: | \"Handbremse nicht betaetigt\" | Wenn sich das Getriebe nach KL15-Aus nicht im wegrollsicheren Zustand befindet, wird der Fahrer aufgefordert die Handbremse zu ziehen";
CM_ SG_ 1348 GE7_Text_03 "Bit schaltet Textmeldung im Kombi als Fahrerhinweis: | \"Gang nicht eingelegt\" | Wenn sich das Getriebe nach KL15-Aus nicht im wegrollsicheren Zustand befindet, wird der Fahrer aufgefordert durch Tippen des Waehlhebels einen Gang einzulegen";
CM_ SG_ 1348 GE7_Gong "Getriebe kann den Fahrer in bestimmten Situationen durch einen Gong zusaetzlich warnen";
CM_ SG_ 1348 GE7_Text_04 "Bit schaltet Textmeldung im Kombi als Fahrerhinweis: | | Selespeed: \"Zum Starten des Motors Bremse betaetigen\" | Das Bit wird gesetzt, wenn der Fahrer den Motor zu starten versucht ohne die Bremse zu betaetigen, wird vom Getriebe ueber eine diskrete Leitung der Motorstart verhindert. Der Text fordert den Fahrer auf die Bremse zu betaetigen.";
CM_ SG_ 1348 GE7_Text_05 "Bit schaltet Textmeldung im Kombi als Fahrerhinweis: | \"Zum Einlegen einer Fahrstufe im Stand Fussbremse betaetigen\"";
CM_ SG_ 1348 GE7_Waehlh_ausgef "Ist der Waehlhebel nicht mehr in der Lage eine gueltige Position an das Getriebesteuergeraet zu ermitteln, so wird dieses Bit gesetzt und im Kombiinstrument erscheint die Prioritaet 2 Warnmeldung \"Waehlhebel defekt, kein R-Gang\".";
CM_ SG_ 1348 GE7_Text_07 "Bit schaltet Prio 2 Warnung im Display des Kombis: | \"Rueckwaertsgang nicht schaltbar\"";
CM_ SG_ 1348 GE7_Feh_1Warn "Text Prio2-Meldung \"Getriebefehler: Weiterfahrt moeglich\" + gelbes Getriebefehlersymbol";
CM_ SG_ 1348 GE7_Feh_2Warn "Selespeed: Text Prio2-Meldung \"Getriebefehler: Weiterfahrt nur eingeschraenkt moeglich\" + gelbes Getriebefehlersymbol | SQ100: Getriebewarnlampe \"rot\"";
CM_ SG_ 1348 GE7_SyncWarn "tbd | Synchronisation Meldungen bei Kl.-15 aus";
CM_ SG_ 1348 GE_Segeln_Menueanf "Aktivierung/Deaktivierung Kombi-Menue Segeln Personalisierung";
CM_ SG_ 1348 GE_Segeln_Status "Bestaetigung Personalisierung Segeln";
CM_ SG_ 1348 GE7_Akustik "SQ100: 3 x Summer 2000 (Getriebe ueberhitzt Vorwarnstufe)";
CM_ SG_ 1348 GE7_Wegrollwarnung "DL800: Text Prio 2 - Meldung: | \"Wegrollgefahr P nicht moeglich.\" | Warnung, dass die Parksperre.";
CM_ SG_ 1348 GE7_Temp_Warnstufe_I "DL800: Text Prio 2 - Meldung: | \"Getriebe zu heiss! Bitte Fahrweise anpassen.\"";
CM_ SG_ 1348 GE7_Text_08 "DL800: Hinweistext: | \"Fahrzeug rollfaehig. Getriebe nicht in P.\" | Hinweis, dass die Parksprerre nicht eingelegt ist.";
CM_ SG_ 1348 GE7_Text_09 "DL800: Hinweistext: | \"Zum Verbleib in N, bitte Bremse betaetigen und Motor starten\" | Hinweis auf Zeitueberschreituung und dass die Parksprerre automatisch eingelegt wird.";
CM_ SG_ 1348 GE7_Text_10 "DL800: Hinweistext: | \"Zum Einlegen von R, N, A bitte Fussbremse betaetigen und Motor starten.\"";
CM_ SG_ 1348 GE7_Text_11 "DL800: Hinweistext: | \"Zum Einlegen eine Fahrstufe bitte Fussbremse betaetigen.\" | Shift-Lock Information";
CM_ SG_ 1348 GE7_Text_12 "DL800: Hinweistext: | \"Wiederanmeldeprozedur. Bitte Bremse betaetigen und Fahrstufe erneut einlegen\"";
CM_ SG_ 1348 GE7_Feh_3Warn "DL 800: Text Prio 2 - Meldung: | \"Weiterfahrt nur eingeschraenkt moeglich. Kein Rueckwaertsgang.\"";
CM_ SG_ 1348 GE7_Stop_Warn "DL800: Text Prio 1 - Meldung: | \"Systemstoerung. Fahrzeug anhalten.\"";
CM_ SG_ 1348 GE7_Feh_4Warn "Text Prio 2 - Meldung: | \"Getriebefehler, Weiterfahrt nur in D moeglich, P bei Motor aus.\"";
CM_ SG_ 1348 GE_Fahrprogramm "Signalisiert das Fahrprogramm im Bezug auf die Fahrstufe des Getriebes.";
CM_ SG_ 1348 GE_Anf_Zylinderabsch "GE_Anforderung_Zylinderabschaltung | Getriebe-Koordination Zylinderumschaltung TMB / VMB (Teilmotorbetrieb / Vollmotorbetrieb)";
CM_ SG_ 1348 GE_Sumpftemperatur "Getriebesumpftemperatur wird ueber den Temperatursensor auf der Getriebeplatine ermittelt. Die absolute Sumpftemperatur wird vom Motor empfangen, um entsprechende Kuehlleistung fuer das Getriebe einzustellen.";
CM_ SG_ 1104 GE8_Checksumme "Pruefsumme mit Endwert 0x0, Definition im CAN Lastenheft (HS-CAN V4.2a, LS-CAN V1.42)";
CM_ SG_ 1104 GE8_Zaehler "Freilaufender Botschaftszaehler";
CM_ SG_ 1104 GE8_Hydr_Pumpe "Momentenvorsteuerung der Leerlaufregelung muss erhoehtes Verlustmoment aussteuern | Hydraulikpumpe angesteuert";
CM_ SG_ 1104 GE8_Motor_aus "Motor soll beim Umschalten des Bits ausgeschaltet werden (Getriebeschutz)";
CM_ SG_ 1104 GE8_Anfahrfkt "Zwischen Motor und Getriebe gibt es fuer die Phase des Anfahrens eine besondere Funktion, bei der das Getriebe dem Motor eine Solldrehzahl und ein dazu passendes Vorsteuermoment vorgibt. Das Bit \"Anfahrfunktion aktiv\" aktiviert die Funktion im Motor.";
CM_ SG_ 1104 GE8_SollDZ "Zwischen Motor und Getriebe gibt es fuer die Phase des Anfahrens eine besondere Funktion, bei der das Getriebe dem Motor eine Solldrehzahl (Solldrehzahl fuer Anfahrfunktion) und ein dazu passendes Vorsteuermoment vorgibt.";
CM_ SG_ 1104 GE8_VorsteuerMom "Zwischen Motor und Getriebe gibt es fuer die Phase des Anfahrens eine besondere Funktion, bei der das Getriebe dem Motor eine Solldrehzahl (Solldrehzahl fuer Anfahrfunktion) und ein dazu passendes Vorsteuermoment (Vorsteuermoment fuer Anfahrfunktion) vorgibt.";
CM_ SG_ 1104 GE8_KuppMom "Zwischen Motor und Getriebe gibt es fuer die Phase des Anfahrens eine besondere Funktion, bei der das Getriebe dem Motor eine Solldrehzahl (Solldrehzahl fuer Anfahrfunktion) und ein dazu passendes Vorsteuermoment vorgibt. Im Fall, dass der Fahrer bei aktiver Anfahrfunktion ploetzlich vom Gas geht, wird ein Ueberschwingen der Motordrehzahl wegen der sich ploetzlich oeffnenden Kupplung (Lastsprung) durch die Beruecksichtigung des uebertragenen Kupplungsmomentes verhindert.";
CM_ SG_ 1108 Getriebe_9_Checksum "Pruefsumme mit Endwert 0x0, Definition im CAN Lastenheft (HS-CAN V4.2a, LS-CAN V1.42)";
CM_ SG_ 1108 Getriebe_9_BZ "4bit-Botschaftszaehler, wird in jeder Sendebotschaft inkrementiert";
CM_ SG_ 1108 GE_Sollstellung_Parksperre "Ueber dieses Signal fordert das GSG die Sollstellung der Parksperre an";
CM_ SG_ 1108 GE_PHM_Diag_Status "Mit diesem Signal kann das GSG die Diagnose des PHM im Zusatzsteuergeraet freigeben oder verhindern/abbrechen.";
CM_ SG_ 1108 GE_Soll_Strom_KUV2 "Mit diesem Signal fordert das Getriebesteuergeraet einen Kuehloelstrom fuer die zweite Kupplung vom Zusatzsteuergeraet an.";
CM_ SG_ 1108 GE_Soll_Hauptdruck_berechnet "Mit diesem Signal uebertraegt das Getriebesteuergeraet den berechneten theoretischen Sollwert fuer den Hauptdruck im Hydrauliksystem";
CM_ SG_ 1108 GE_Sumpftemperatur_2 "Ueber dieses Signal uebertraegt das GSG die aktuelle Temperatur des Hydraulikoels im Getriebesumpf";
CM_ SG_ 1108 GE_TVH_Wasserzusatzpumpe "Dieses Signal zeigt das prozentuale Tastverhaeltnis fuer die Ansteuerung der Kuehlwasserzusatzpumpe fuer die Getriebekuehlung mit einem PWM-Signal.";
CM_ SG_ 1108 GE_Freigabe_Spuehlfkt "HSG signalisiert die Freigabe der Spuehlfunktionalitaet an das ZSG.";
CM_ SG_ 1106 GH1_Zaehler "Freilaufender Botschaftszaehler";
CM_ SG_ 1106 GH1_FreigabeK0 "Uebergang von 0 nach 1 (bzw. 1 nach 0) ist Teil des Wiederstart- (Stop-) Handshakes";
CM_ SG_ 1106 GH1_FreigabeVMStop "Signalisiert Bereitschaft GSG, dass VM gestoppt werden darf (Soft Stop) oder dass EM gestoppt werden darf (Uebergang EM-Fahren => EM-Fahrbereitschaft)";
CM_ SG_ 1106 GH1_FehlerstatusGSG "Hybrid-spezifische Fehlerstati | PQ35: Fehlerstatus 1 signalisiert, dass der Druck zum Oeffnen der K0 nicht ausreicht (nach Kl15 ein) | PL71: Fehlerstatus 1 signalisiert eine unzureichende Druckversorgung durch die EOP. | Fehlerstatus 2: Verhinderung ungewollten Vortriebs";
CM_ SG_ 1106 GH1_nK0 "Nur PQ35 Hybrid: | GSG teilt MSG mit, auf welcher DZ die EM nach schnellem Schliessen der K0 und nach DZAngleichung durch das GSG landen wird. | Wenn Bit7 Byte3 nicht aktiv: EM-Drehzahl wird gespiegelt | Wenn Bit7 Byte3 aktiv: DZ, auf der Motor nach Schliessen K0 und nach DZAngleichung drehen wird | Nicht benutzt fuer PL71 Hybrid";
CM_ SG_ 1106 GH1_VZMomEingriff "PQ35 Hybrid: Vorzeichen fuer Getriebeeingriff auf EM (Byte 3, Bit 6..1)";
CM_ SG_ 1106 GH1_MomEingriff_EM "Nur PQ35 Hybrid: Direkter Eingriff des GSG auf EM. | Ist der Betrag des Absolutwertes des Eingriffsmomentes in Nm. Verwendet zur Daempfung des Triebstranges nach Impulsstart, wenn VM-Momente noch ungenau sind. | E-Gas-Sicherheit: begrenzt auf 30Nm, zusaetzlich muss Zeitintegral Null sein | (nicht benutzt fuer PL71 Hybrid)";
CM_ SG_ 1106 GH1_Wiederstart "Getriebe zeigt an, ob Wiederstart aktiv ist";
CM_ SG_ 1106 GH1_VM_akt_halten "Im elektrischen Fahren/Tip: Uebergang von 0 auf 1 zeigt VM-Startanforderung des GSG an. | Ansonsten: Empfehlung GSG an MSG, dass VM aktiv gehalten werden soll. Verwendbar zB bei den Funktionen 'fast off (Gang halten)' oder bei 'Rueckschaltung bei Bremsen'";
CM_ SG_ 1106 GH1_Sportfaktor "Sportlichkeitsfaktor Getriebe, zur Verwendung in der Hybrid-Fahrstrategie | 0 = nicht sportlich | 1..15 = sportlich";
CM_ SG_ 1106 GH1_Freig_LL_Reg "GSG gibt hier die Aktivierung einer DZ-Regelung von VM und/oder EM frei. | (Verhinderung Selbstbeschleuniger)";
CM_ SG_ 1106 GH1_VKM_StAnf "Ausloesen des VM-Wiederstart im elektromot. Betrieb | Nur zur abgestimmten Verwendung zwischen Hybridcontroller (MSG) und Getriebe (GSG)";
CM_ SG_ 1106 GH1_VKM_StKontr "Freigabe der Wiederstartkontrolle | Nur zur abgestimmten Verwendung zwischen Hybridcontroller (MSG) und Getriebe (GSG)";
CM_ SG_ 1106 GH1_AnzeigeDZ "Anzeigedrehzahl in Hybridprojekten vom Getriebe zum Motor";
CM_ SG_ 1106 GH1_Filt_MomAufbau "Faktor, der im MSG zur Berechnung der Filterkonstanten fuer den Fahrerwunschmomentenaufbau im Impulsstart verwendet wird.";
CM_ SG_ 1106 GE_Freigabe_Verfallsinfo_WFS "WFS";
CM_ SG_ 1110 Getriebe_Zusatz_01_Checksum "Pruefsumme mit Endwert 0x0, Definition im CAN Lastenheft (HS-CAN V4.2a, LS-CAN V1.42)";
CM_ SG_ 1110 Getriebe_Zusatz_01_BZ "4bit-Botschaftszaehler, wird in jeder Sendebotschaft inkrementiert";
CM_ SG_ 1110 GZ_OBD_Status "Dieses Bit steuert die MIL-Lampe an (Motorsteuergeraet reicht diese Info an Kombi weiter).";
CM_ SG_ 1110 GZ_PHM_Diagnose "Anzeige einer aktiven PHM Diagnose, um Fehldiagnosen im Hauptsteuergeraet zu vermeiden.";
CM_ SG_ 1110 GZ_Position_Parksperre "Ueber dieses Signal uebertraegt das Zusatzsteuergeraet die aktuelle Position der Parksperre";
CM_ SG_ 1110 GZ_Kuehloeltemperatur "Ueber dieses Signal uebertraegt das Zusatzsteuergeraet die aktuelle Kuehloeltemperatur der zweiten Kupplung an das Getriebesteuergeraet";
CM_ SG_ 1110 GZ_IST_Strom_KUV2 "Ueber dieses Signal uebertraegt das Zusatzsteuergeraet den gemessenen el. Ventilstrom des Kuehloelventils der 2. Kupplung (KUV2) an das GSG";
CM_ SG_ 1110 GZ_KuehlOel2_Status "Ueber dieses Signal signalisiert das Zusatzsteuergeraet den Fehlerstatus Kuehloelventils2";
CM_ SG_ 1110 GZ_PAV_Status "Ueber dieses Signal signalisiert das Zusatzsteuergeraet einen Fehlerzustand des Parksperreauslegeventils (PAV)";
CM_ SG_ 1110 GZ_PEV_Status "Ueber dieses Signal signalisiert das Zusatzsteuergeraet einen Fehlerstatus des Parksperreneinlegeventils (PEV)";
CM_ SG_ 1110 GZ_PHM_Status "Signalisierung eines Fehlerzustand der Parksperre inkl. Parksperrenhaltemagneten, sowie der Bestromung des Parksperrenhaltemagneten";
CM_ SG_ 1110 GZ_Schaltwippen_TipDown_02 "Ueber dieses Signal signalisiert das Zusatzsteuergeraet den Zustand Schaltwippe TipDown \"betaetigt\"";
CM_ SG_ 1110 GZ_Schaltwippen_TipUp_02 "Ueber dieses Signal signalisiert das Zusatzsteuergeraet den Zustand Schaltwippe TipUP \"betaetigt\"";
CM_ SG_ 1110 ZSG_Initialisierung "Das Bit zeigt dem Empfaenger an, dass das Zusatzsteuergeraet in der Initialisierung ist (z.B. Reset). Das Signal steht fuer maximal 500ms ab Sendebeginn auf 1, danach dauerhaft auf 0.";
CM_ SG_ 1110 GZ_Warnung "Prioritaetswarnungen vom DL800ZSG zum DL800HSG | Nach einer entsprechenden Priorisierung der Textmeldungen werden, die Texte vom HSG zum Kombi gesendet | 0=keine Anzeige | 1=Weiterfahrt moeglich (+ gelbes Getriebefehlersymbol) | 2=Weiterfahrt nur eingeschraenkt moeglich (+ gelbes Getriebefehlersymbol) | 3=nur DL-Getriebe: Weiterfahrt nur eingeschraenkt moeglich. Kein R-Gang | 4=Getriebefehler (gelbes Getriebesymbol) Weiterfahrt nur in D moeglich P bei Motor AUS | 5=Wegrollgefahr! (gelbes Getriebesymbol) P nicht moeglich Bitte Parkbremse betaetigen";
CM_ SG_ 1110 GZ_Oelpumpe_Status "Ueber dieses Signal signalisiert das Zusatzsteuergeraet einen Fehlerzustand der Getriebeoelpumpe\"";
CM_ SG_ 1110 GZ_Schaltwippen_TipDown "Ueber dieses Signal signalisiert das Zusatzsteuergeraet den Zustand Schaltwippe TipDown \"betaetigt\"";
CM_ SG_ 1110 GZ_Schaltwippen_TipUp "Ueber dieses Signal signalisiert das Zusatzsteuergeraet den Zustand Schaltwippe TipUP \"betaetigt\"";
CM_ SG_ 1110 GZ_KD_Fehler "Bei gesetztem Bit ist mindestens ein Kundendienstfehler eingetragen";
CM_ SG_ 906 GRA_Checksum "Pruefsumme mit Endwert 0x0, Definition im CAN Lastenheft (HS-CAN V4.2a, LS-CAN V1.42)";
CM_ SG_ 906 GRA_Hauptschalt "1 = GRA-Hauptschaslter eingeschaltet, gerastetes Aus/Ein, 1 Tastsignal ein | Bei Sender Codierung '01 u. 10' sind Tipsignale entprellt' | 4 Positionen LSM (Sender-Codierung 11) uebertraegt Tastsignal (Byte 4 Bit 5 gesetzt)";
CM_ SG_ 906 GRA_Abbrechen "1 = GRA/ADR-Tipschalter betaetigt (Aus mit Speichern), Bei Sender Codierung '01 u. 10' sind Tipsignale entprellt' | GRA_ADR_Tippschalter _aus betaetigt, Abbrechen";
CM_ SG_ 906 GRA_Down_kurz "1 = Tippschalter betaetigt, Bei Sendercodierung '00' und '11' wird hier 'Setzen/Verzoegern' uebertragen | Bei Sender Codierung '01 u. 10' sind Tipsignale entprellt. | GRA_ADR_Tipschalter_Verzoegern betaetigt, KurzTip-down";
CM_ SG_ 906 GRA_Up_kurz "1 = Tippschalter betaetigt, Bei Sendercodierung '00' und '11' wird hier 'Wiederaufnahme/Beschleunigen' uebertragen | Bei Sender Codierung '01 u. 10' sind Tipsignale entprellt. | GRA_ADR_Tipschalter_Beschleunigen betaetigt, KurzTip-up";
CM_ SG_ 906 GRA_Down_lang "1 = Verzoegern | Betaetigung des Tipschalters 'Verzoegern' fuer t> 0.5 sec. Bedeutet 'Verzoegern' | GRA_ADR_verzoegern, LangTip-down";
CM_ SG_ 906 GRA_Up_lang "1 = Beschleunigen | Betaetigung des Tipschalters 'Beschleunigen' fuer t> 0.5 sec. Bedeutet 'Beschleunigen' | GRA_ADR_beschleunigen, LangTip-up";
CM_ SG_ 906 GRA_Fehler_Bed "1 = Fehler im Bedienteil";
CM_ SG_ 906 GRA_Kodierinfo "0 = GRA, 1 = ACC | Kodierinfo SMLS";
CM_ SG_ 906 GRA_Neu_Setzen "1 = Tipschalter betaetigt; Bei Sendercodierung '00' und '11' wird hier immer '0' uebertragen | Bei Sender Codierung '01' und '10' sind Tipsignale entprellt. | GRA_ADR_Tipschalter_Setzen";
CM_ SG_ 906 GRA_Recall "1 = Tipschalter betaetigt | Bei Sendercodierung '00' und '11' wird hier immer '0' uebertragen, Bei Sender Codierung '01' und '10' sind Tipsignale entprellt. | GRA_ADR_Tipschalter _Wiederaufnahme";
CM_ SG_ 906 GRA_Sender "00: Sender = Bordnetz-SG/BCM (4 Tasten / Rohwerte) | 01: Sender = Lenksaeulenmodul mit 6 GRA Bedienelementen | 10: Sender = Multifunktionslenkrad Generation 2 | 11: Sender = Lenksaeulenmodul mit 4 GRA Bedienelementen | GRA_ADR_Sendercodierung";
CM_ SG_ 906 GRA_Neu_Zaehler "Botschaftszaehler zur Erkennung fehlender GRA-Botschaften";
CM_ SG_ 906 GRA_Tip_Down "0 = Taste Down unbetaetigt, 1 = Taste Down betaetigt | Tiptronic Bedienung Down, Tiptronik-Tip-Down";
CM_ SG_ 906 GRA_Tip_Up "0 = Taste Up unbetaetigt, 1 = Taste Up betaetigt | Tiptronic Bedienung Up, Tiptronik-Tip-Up";
CM_ SG_ 906 GRA_Zeitluecke "Wird nur gesendet bei Sendercodierung '01' | 00: Taste nicht betaetigt | 01: Distanzwunsch kleiner | 10: Distanzwunsch groesser | 11: nicht definiert. | ADR Distanzwunsch, Zeitlueckenverstellung";
CM_ SG_ 906 GRA_Limiter "1 = Limitertaste wird betaetigt";
CM_ SG_ 906 GRA_Typ_Hauptschalt "0 = Hauptschalter gerastet ein | 1 = Hauptschalter getastet, d.h. nur Flankenuebermittlung, Zustandserkennung im Motor-SG | Typ GRA Haupt-schalter/-taster";
CM_ SG_ 906 GRA_LIM_Taste_verfuegbar "Das Signal zeigt an, ob eine Limiter-Umschalttaste am jeweiligen GRA/ACC-Bedienelement vorhanden ist.";
CM_ SG_ 906 GRA_Fehler_Tip "1 = Fehler im Tiptronic Bedienteil";
CM_ SG_ 1529 GM_KD_Fehler "Mind. ein Kundendienstfehler ist eingetragen";
CM_ SG_ 1164 HS1_Checksumme "Pruefsumme mit Endwert 0x0, Definition im CAN Lastenheft (HS-CAN V4.2a, LS-CAN V1.42)";
CM_ SG_ 1164 HS1_Zaehler "Freilaufender Botschaftszaehler gem. CAN Lastenheft";
CM_ SG_ 1164 HS1_Drehz_Grenze "Erkennung der Motordrehzahlgrenzen im ACC fuer die ACC-Funktion in Kombination mit Handschaltgetrieben fuer die Schaltaufforderung beim Erreichen der Komfortgrenzen bzw. die ACC-Abschaltung beim Erreichen der Abschaltgrenzen | ACC Motordrehzahlgrenze";
CM_ SG_ 1164 HS1_Gang "Erkennung der Ganginformation im ACC fuer die ACC-Funktion in Kombination mit Handschaltgetrieben | Ganginformation";
CM_ SG_ 1164 MO_NGS_Position "Messwert des Neutralgangsensors | (nur Handschalter)";
CM_ SG_ 1164 MO_NGS_Status "Status des Signals MO_NGS_Position. Das MSG prueft die Plausibilitaet nur hinsichtlich sicher geoeffnetem Triebstrang.";
CM_ SG_ 210 HC1_Checksumme "Pruefsumme mit Endwert 0x0, Definition im CAN Lastenheft (HS-CAN V4.2a, LS-CAN V1.42)";
CM_ SG_ 210 HC1_Zaehler "Definition im CAN-Lastenheft | Freilaufender Botschaftszaehler";
CM_ SG_ 210 HC1_Sta_HCA "0: HCA deaktiviert | 1: HCA Anforderung nicht ausfuehrbar (Lenkung Fehlerstatus) | 2: Kommunikation zum Lenkhilfe-SG gestoert | 3: HCA funktionsbereit | 4: reserviert | 5: externer Momenteneingriff angefordert";
CM_ SG_ 210 HC1_LM_Offset "Reale Aufloesung 0,01 Nm | Anforderung Lenkmomenten-Offset";
CM_ SG_ 210 HC1_LM_Offset_Sign "Vorzeichen Anforderung Lenkmomenten-Offset";
CM_ SG_ 210 HC1_Frequenz "Frequenz der Lenkradvibration";
CM_ SG_ 210 HC1_Amplitude "Amplitude der Lenkradvibration";
CM_ SG_ 1512 KL_HV_ein "Gibt an, ob eine Hochvolt-Klimakomponente (HV-PTC, EKK) eingeschaltet ist.";
CM_ SG_ 1512 KL_Innengeblaese "Gibt an, ob das Innengeblaese eingeschaltet ist.";
CM_ SG_ 1512 KL_PTC_Pumpe_Soll "Drehzahlvorgabe PTC Pumpe";
CM_ SG_ 1512 KL_Beschlagsgefahr "volle Leistungsfreigabe HV Heizer und HV EKK bei Scheibenbeschlag";
CM_ SG_ 1512 KL_Standklima_RemoteModus "Modus (Lueften, Kuehlen, Heizen) der Standklimatisierung (Innenraum) zur Remote Anzeige";
CM_ SG_ 1512 KL_Wake_Up_ACAN "0 = kein Wake-Up (z.B. KL15-Normalbetrieb) | 1 = Anforderung zum Wecken des Antriebs-CAN | Die RCP_Klima lernt anhand von MO7_Mot_weckfaehig, ob es das Bit setzen muss.";
CM_ SG_ 1512 KL_HV_Anf "Klimaanlage fordert die Aktivierung des Hochvoltbordnetz fuer Standklimatiserung an.";
CM_ SG_ 1512 KL_Ventil_Batterie_Anf "Das Klima-SG sendet eine Anforderung fuer den Soll-Schaltzustand des 3/2 Wegeventils fuer die HV-Batterie an die MED";
CM_ SG_ 1512 KL_Ventil_vor_Motor_Anf "Das Klima-SG sendet eine Anforderung fuer den Soll-Schaltzustand des 3/2 Wegeventils vor dem Motor an die MED";
CM_ SG_ 1512 PTC_Strom "Strom HV-PTC fuer Reichweitenberechnung";
CM_ SG_ 1512 EKK_Strom "EKK Stromaufnahme | (Nur VW360/7 ohne LIN-EKK: 0 - 25,4 A mit Faktor 0,1)";
CM_ SG_ 1512 KL_Kompr_Drehzahl_Soll "Kompressordrehzahl";
CM_ SG_ 1512 EKK_Status "Signalisiert, ob der EKK zur Batteriekuehlung oder (Stand-)klimatisierung aktiviert wurde.";
CM_ SG_ 1512 KL_Standklima_Status_02 "Status der Standklimatisierung (Innenraum).";
CM_ SG_ 1512 PTC_Pumpe_Ist "VW360/7: Info an das MSG ueber Ansteuerung PTC Wasserpumpe | VW120/7: Info an das Klimabedeinteil ueber Ansteuerung PTC Wasserpumpe (CWA50).";
CM_ SG_ 1512 PTC_Pumpe_Status "Zustandsrueckmeldung PTC Wasserpumpe";
CM_ SG_ 1512 KL_Charisma_FahrPr "Aktuelles Fahrprogramm des Charisma-Teilnehmers";
CM_ SG_ 1512 KL_Charisma_Status "Charisma Systemstatus des Charisma-Teilnehmers";
CM_ SG_ 1512 EKK_Status_Vorstrg "VW360/7: 1 = Kompressor ein, Zustand incl. 140ms Vorsteuerung, Info an das MSG: Kompressor EIN";
CM_ SG_ 1527 KE1_Comp_enable "Enable to start for compressor | After 1 second when High-voltage becomes available, turn on '1'";
CM_ SG_ 1527 KE1_Umluftstellung "Reserviert fuer Umluftstellung 0-100%";
CM_ SG_ 1527 KE1_Comp_rev_rq "Requested compressor revolution | 0, 800-8600 rpm | below 800 rpm = compressor stop | 800 - 8600 rpm = operation | over 8600 rpm = compressor stop";
CM_ SG_ 800 KO1_SleepInd "SIB zwischen Kombi und Gateway (nur auf dem Kombi-CAN, wird aber auch auf A-CAN gespiegelt) | (z.Zt. nur Audi D3/C6, Audi AB2 und PQ46): Bit haelt im PQ35/46 den CAN-Infotainment wach. Anmerkung: Bit wird bei 'Klemme 15 aus' auf 1 gesetzt, ausser es liegt eine spezielle Funktionsanforderung vor (z.B: WFS-Anlernen oder Warnblinken) | NMHigh-Teilnehmer der PQ35/46 muessen das Signal nach Kl.-15 aus weiterhin bedienen oder dauerhaft auf 1 = 'Sleep bereit' setzen! | Sleep-Indication-Bit Kombi-CAN";
CM_ SG_ 800 KO1_Sta_Tank "nach 2 Sekunden liegt spaetestens die Tankinfo vor | Fehlerstatus Tank";
CM_ SG_ 800 KO1_Oeldruck "Oeldruckschalter";
CM_ SG_ 800 KO1_Sta_Oeldr "Oeldruckwarnung koennte auch vom Empfaenger des Oeldruckschalters generiert werden | Dynamische Oeldruckwarnung";
CM_ SG_ 800 KO1_Kuehlmittel "Kuehlmittelmangel";
CM_ SG_ 800 KO1_Wakeup_Komfort "Das Audi PQ35-/ VW PQ46 Kombi kann durch Setzen dieses Bits bei aktivem Kombi-CAN den Komfort-CAN aufwecken oder wachhalten | Anmerkung: alle Funktionen, die einen aktiven Komfort-CAN benoetigen (z.B. Warnblinken) muessen dieses Bit auf 1 setzen.";
CM_ SG_ 800 KO1_Warn_Tank "Fahrer wird gewarnt (z. Zt. 7 Liter)";
CM_ SG_ 800 KO1_Vorgluehen "Rueckmeldeinformation fuer das Motorsteuergeraet | Vorgluehlampe (Kombi 1)";
CM_ SG_ 800 KO1_Bremsinfo "Bit 0 Bremsfluessigkeitswarnung | Bit 1 Handbremsschalter (nicht bei Audi) | A0-Klasse hat z. Zt. einen gemeinsamen Eingang fuer Bremsfluessigkeitsstand und Handbremse, d.h. es ist keine Unterscheidung moeglich";
CM_ SG_ 800 KO1_Handbremse "Umgesetzt bei VW, Audi B6, B7 | Nicht bei Audi-Fahrzeugen mit EPB (Audi D3, C6) | Sonderfall PQ46: Hardware-Eingang von EPB zur Ansteuerung der BKL-Lampe, auch im Betriebsfall BKL-Blinken! | Sonderfall BY61x: Gespiegelt aus EPB-Botschaft CAN-Antrieb.";
CM_ SG_ 800 KO1_La_Ladekon "Kombi hat seine Ladekontroll-Lampe eingeschaltet (Empfaenger: z.Zt. Batman), nicht PQ35/46, nicht Audi D3/C6";
CM_ SG_ 800 KO1_Stellglieder "Im Stellgliedtest werden auch Lampen angesteuert (Achtung: Rueckmeldebits koennen gesetzt sein)";
CM_ SG_ 800 KO1_Zeitluecke "nur in ADR/ACC-Fahrzeugen: | ACC Zusatzanzeige: 0 = aus / ungleich 0 = ein | angezeigte ADR-Zeitluecke wird auf 3 Bits begrenzt | ACC Zusatzanzeige / Angezeigte Zeitluecke";
CM_ SG_ 800 KO1_Tankstop "Kombi hat Tankstop erkannt (Vorsicht: Wartezeit nach Klemme 15 ein beruecksichtigen) | Flag wird nach 5 Sekunden bei fahrendem Fahrzeug geloescht";
CM_ SG_ 800 KO1_Tankinhalt "Restmenge 2 bzw. 2,5l nicht aufloesbar | 7FH ist Fehler. Bei Klemme 15 aus werden hier die zuletzt bei Kl. 15 ein ermittelten Werte gesendet.";
CM_ SG_ 800 KO1_OBD_Tank "OBD-Schwelle (z. Zt. 15 %, applizierbar) | Tankwarnung";
CM_ SG_ 800 KO1_Quelle_kmh "Die Fahrzeuggeschwindigkeit wird aus einem Tachogeber (eigener Hallgeber, eigener Reed-Kontakt, Fahrtenschreiber) oder aus der Referenzgeschwindigkeit vom ABS berechnet (nicht Audi D3/C6) | Signalquelle Geschwindigkeit";
CM_ SG_ 800 KO1_kmh "Fahrzeuggeschwindigkeit als Rohsignal vom Tachogeber (ab ca. 25 km/h eine Geberradumdrehung, d.h. z. Zt. Mittelwert aus 4 Perioden der wahren Geschwindigkeit) oder vom ABS-Steuergeraet (Raddrehzahl x Radumfang) | die Aufloesung entspricht der ABS-Geschwindigkeit in Bremse 1, (nicht Audi D3/C6) | bei Geschwindigkeiten > 326 wird 0xFF im High-Byte ausgegeben (mind. die 8 hoechstwertigen Bits sind auf \"1\" gesetzt) | Geschwindigkeit (Kombi 1)";
CM_ SG_ 800 KO1_Zaehler "Plausibilisierung erfolgt im ACC-/ADR- System: im PQ46 nur bei ACC unterstuetzt | Botschaftszaehler";
CM_ SG_ 800 KO1_ACC_Inkons "Rueckmeldung zum ACC-/ADR- System bzgl. CAN- Lastenheft | ACC Botschaft(en) nicht konsistent";
CM_ SG_ 800 KO1_ACC_AnzFhl "Bit wird bei einem ACC/ADR relevanten Fehler (Anzeige/Gong) gesetzt. | ACC Anzeige Fehler";
CM_ SG_ 800 KO1_angez_kmh "Am Tacho angezeigte Geschwindigkeit (incl. Voreilung) | (0xFF im High-Byte (Byte 7 von mKombi_1) = Fehler)";
CM_ SG_ 800 KO1_kmh_mph "Dem Fahrer wird die Geschwindigkeit in km/h oder in Miles/hour angezeigt (ueber Personalisierung verstellbar) (bei Audi konstanter Wert) | Einheit der angezeigten Geschwindigkeit";
CM_ SG_ 800 KO1_ABS_Lampe "ABS-Sicherheits-Lampe wurde eingeschaltet";
CM_ SG_ 800 KO1_ASRESP_Lampe "ASR-/ESP-Sicherheits-Lampe wurde eingeschaltet";
CM_ SG_ 800 KO1_Brems_Lampe "Sicherheits-Lampe Bremskontrolle wurde eingeschaltet | Besonderheit (VW PQ35/46): Lampe wird auch zur Handbremskontrolle (Audi: auch von EPB) und Bremsfluessigkeitswarnung (auch bei Audi) verwendet und vom Kombi aufgeprueft";
CM_ SG_ 800 KO1_Airbag_Lampe "Airbag Sicherheits-Lampe wurde eingeschaltet";
CM_ SG_ 800 KO1_Lenkh_Lampe "Lenkhilfe-Sicherheits-Lampe wurde eingeschaltet";
CM_ SG_ 800 KO1_LDW_AnzFeh "Kombiinstrument hat Fehler erkannt | LDW-Anzeigefehler";
CM_ SG_ 800 KO1_SILA_gueltig "Rueckmeldeinformation (Bit 1-5) ist gueltig | Anmerkung: Rueckmeldeinformationen werden bedient; Lampen sind bei 'Klemme 15 aus' ausgeschaltet";
CM_ SG_ 1470 LDW_Lernmodus_seitenabhaengig "Signal dient zur Ansteuerung von Funktionsanzeigen im Mitteldisplay des Kombiinstruments fuer die seitenabhaengige Liniendetektion";
CM_ SG_ 1470 LDW_Lernmodus "Ansteuerung von LDW-Funktionsanzeigen im Mitteldisplay Kombiinstrument analog B8/Q5 (im AU716, C6)";
CM_ SG_ 1470 LDW_Gong "Gong";
CM_ SG_ 1470 LDW_Kameratyp "Signal zur Unterscheidung der Kameratypen und damit Moeglichkeit der Anzeige der integrierten Assistenzansicht im Kombi bei Hella-MFK ab 22/11.";
CM_ SG_ 1470 LDW_Lampe_gelb "Lampenansteuerung gelb im Kombiinstrument";
CM_ SG_ 1470 LDW_Lampe_gruen "Lampenansteuerung gruen im Kombiinstrument";
CM_ SG_ 1470 LDW_SW_Warnung_links "Die Kamera erkennt einen kurz bevorstehenden moeglichen Spurwechsel auf der linken Seite. Das Signal dient dazu, Side Assist in den Warnmodus umzuschalten, obwohl der Fahrer nicht blinkt.";
CM_ SG_ 1470 LDW_SW_Warnung_rechts "Die Kamera erkennt einen kurz bevorstehenden moeglichen Spurwechsel auf der rechten Seite. Das Signal dient dazu, Side Assist in den Warnmodus umzuschalten, obwohl der Fahrer nicht blinkt.";
CM_ SG_ 1470 LDW_KD_Fehler "Bei gesetztem Bit ist mindestens ein Kundendienstfehler eingetragen";
CM_ SG_ 1470 LDW_DLC "distance to line, Abstand vom Fahrzeug zur Fahrbahnmarkierung | Der Wert gibt die Breite der Restspur zur Linie wieder (Abstand vom Fahrzeugaeusserem zur Linie) (Wert POSITIV wenn Fahrzeug in der Spur - Wert NEGATIV wenn Fahrzeug ueber der Linie)";
CM_ SG_ 1470 LDW_TLC "time to line, Zeit bis das Fahrzeug die Fahrbahnmarkierung ueberquert";
CM_ SG_ 1470 LDW_Seite_DLCTLC "Zuordnung auf welche Seite sich LDW_DLC bzw. LDW_TLC beziehen";
CM_ SG_ 1470 LDW_Frueh_Spaet "Im MMI eingestellter, aktiver Lenkeingriffszeitpunkt: | 0: frueh, frueh aktiv | 1: frueh, spaet aktiv | 2: spaet, spaet aktiv | 3: Fehler";
CM_ SG_ 976 LH1_Lastinfo "reale Aufloesung z. Zt. 5 Ampere | Lastinformation";
CM_ SG_ 976 LH1_Fehler_LI "n.i.O. steht fuer Fehlerwert oder Lastinformation noch nicht verfuegbar | Fehlerstatus Lastinformation";
CM_ SG_ 976 LH1_Sicherheitslamp "steuert direkt die Sicherheitswarnlampe Lenkhilfe (rot) an (bei EHPS VW25x gelbe LED)";
CM_ SG_ 976 LH1_Fehlerlampe "steuert direkt die Fehlerlampe Lenkhilfe (gelb); kein Aufpruefen bei Neustart, keine Rueckleseinformation in Kombi-Botschaft";
CM_ SG_ 976 LH1_Textbits "Diese Textbits werden verwendet, um im Kombi Texte oder Bilder fuer die Lenkhilfe darzustellen | | Hybrid: | Text 1 (ID_TXT_1026.1): Ausfall Lenkunterstuetzung | Text 2 (ID_TXT_1026.2): Fehler Lenkunterstuetzung | Text 3 (ID_TXT_1026.3): Kurzzeitige Stoerung Lenkunterstuetzung";
CM_ SG_ 976 LH1_Akustiksign "Ansteuerung eines Akustiksignals (Summer) im Kombi (optional vorgehalten)";
CM_ SG_ 976 LH1_SleepInd "Die Sleep-Bereitschaft wird nach Klemme 15 aus durch Setzen dieses Bits signalisiert | NMHigh-Teilnehmer der PQ35/46 muessen das Signal nach Kl.-15 aus weiterhin bedienen oder dauerhaft auf 1 = 'Sleep bereit' setzen! | Sleep-Indication (Lenkhilfe 1)";
CM_ SG_ 976 LH1_Fehlereintr "Bei gesetztem Bit ist mindestens ein Kundendienstfehler eingetragen | Fehlerspeichereintrag (Lenkhilfe 1)";
CM_ SG_ 976 LH1_EPS_Diagmode "Anzeige, ob sich die Lenkhilfe in einem Diagnose Mode befindet. | EPS Diagnosemode";
CM_ SG_ 976 LH1_gue_ECU_Temp "(war: 'Bordnetzwelligkeit gueltig') | Gueltigkeit der Signale ECU-Temperatur";
CM_ SG_ 976 LH1_Kuehlung "nach Ueberschreiten einer oberen Grenztemperatur fordert die EPS die Zuschaltung einer externen Kuehlung, z. B. durch den Kuehlerluefter | Anforderung Kuehlung";
CM_ SG_ 976 LH1_Mode_Hybrid "Reserviert fuer Hybrid-Modus (kodierbar) | Mode Hybrid-Antrieb";
CM_ SG_ 976 LH1_NL_Untersp "Bit-Feld zeigt an, dass sich die Lenkhilfe in einem Notlaufprogramm befindet und durch welche Ursache dieses aktiviert wurde: | 0: ist nicht Ausloeser eines Notlaufes | 1: ist Ausloeser eines Notlaufes | Das Betriebsverhalten der Lenkhilfe wird an das bestehende Defizit angepasst. | 1 -> Versorgungsspannung Lenkhilfe hat Schwelle Unterspannung unterschritten | Notlauf Unterspannung";
CM_ SG_ 976 LH1_NL_Uebersp "Bit-Feld zeigt an, dass sich die Lenkhilfe in einem Notlaufprogramm befindet und durch welche Ursache dieses aktiviert wurde: | 0: ist nicht Ausloeser eines Notlaufes | 1: ist Ausloeser eines Notlaufes | Das Betriebsverhalten der Lenkhilfe wird an das bestehende Defizit angepasst. | 1 -> Versorgungsspannung Lenkhilfe hat Schwelle Ueberspannung ueberschritten | Notlauf Ueberspannung";
CM_ SG_ 976 LH1_NL_Uebertemp "Bit-Feld zeigt an, dass sich die Lenkhilfe in einem Notlaufprogramm befindet und durch welche Ursache dieses aktiviert wurde: | 0: ist nicht Ausloeser eines Notlaufes | 1: ist Ausloeser eines Notlaufes | Das Betriebsverhalten der Lenkhilfe wird an das bestehende Defizit angepasst. | 1 -> Interner Temperatursensor hat Ueberschreitung der zulaessigen Hoechsttemperatur erkannt | Notlauf Uebertemperatur";
CM_ SG_ 976 LH1_NL_Sensor "Bit-Feld zeigt an, dass sich die Lenkhilfe in einem Notlaufprogramm befindet und durch welche Ursache dieses aktiviert wurde: | 0: ist nicht Ausloeser eines Notlaufes | 1: ist Ausloeser eines Notlaufes | Das Betriebsverhalten der Lenkhilfe wird an das bestehende Defizit angepasst. | 1 -> Interne Sensorik (z.B. Momentensensor) liefert keine gueltigen oder eingeschraenkt gueltige Signale | Notlauf Sensorik";
CM_ SG_ 976 LH1_NL_CAN_SS "Bit-Feld zeigt an, dass sich die Lenkhilfe in einem Notlaufprogramm befindet und durch welche Ursache dieses aktiviert wurde: | 0: ist nicht Ausloeser eines Notlaufes | 1: ist Ausloeser eines Notlaufes | Das Betriebsverhalten der Lenkhilfe wird an das bestehende Defizit angepasst. | 1 -> Die notwendigen Daten aus der CAN-Schnittstelle werden nicht empfangen oder sind fehlerhaft/ungueltig. | Notlauf CAN-Schnittstelle";
CM_ SG_ 976 LH1_NL_ECU "Bit-Feld zeigt an, dass sich die Lenkhilfe in einem Notlaufprogramm befindet und durch welche Ursache dieses aktiviert wurde: | 0: ist nicht Ausloeser eines Notlaufes | 1: ist Ausloeser eines Notlaufes | Das Betriebsverhalten der Lenkhilfe wird an das bestehende Defizit angepasst. | 1 -> Steuergeraeteinterner Defekt | Notlauf ECU intern";
CM_ SG_ 976 LH1_NL_Motor "Bit-Feld zeigt an, dass sich die Lenkhilfe in einem Notlaufprogramm befindet und durch welche Ursache dieses aktiviert wurde: | 0: ist nicht Ausloeser eines Notlaufes | 1: ist Ausloeser eines Notlaufes | Das Betriebsverhalten der Lenkhilfe wird an das bestehende Defizit angepasst. | 1 -> Defekt am Lenkhilfe-Servo-Motor | Notlauf Motor";
CM_ SG_ 976 LH1_NL_LeistDichte "Bit-Feld zeigt an, dass sich die Lenkhilfe in einem Notlaufprogramm befindet und durch welche Ursache dieses aktiviert wurde: | 0: ist nicht Ausloeser eines Notlaufes | 1: ist Ausloeser eines Notlaufes | Das Betriebsverhalten der Lenkhilfe wird an das bestehende Defizit angepasst. | 1 -> Leistungsdichtebegrenzung bei Missbrauch | Notlauf Leistungsdichte";
CM_ SG_ 976 LH1_ULeistung "Die Unterstuetzungsleistung gibt prozentual an, in welchem Verhaeltnis die tatsaechlich abgegebene Leistung zur Nominalleistung steht, d.h.: | 0% : keine Servounterstuetzung | 100%: maximale Servounterstuetzung (Nominalleistung) | 0% < Unterstuetzungsleistung < 100%: Leistungsreduzierung | aufgrund eines Notlaufprogrammes;Hier muss mindestens ein Bit im Bit-Feld Notlauf gesetzt sein";
CM_ SG_ 976 LH1_ECU_Temp "(war: 'Bordnetzwelligkeit') | Temperatur innerhalb der ECU";
CM_ SG_ 916 LRZ_Parameter "Parametrisierung waehlt die Fahrzeugvariante und die AFS-Variante aus | LWR und AFS Parametrisierung";
CM_ SG_ 916 LRZ_Grundeinst "Grundeinstellung des Abblendlichtes am Lichteinstellkasten im Service oder Bandende mit Tester erfolgt! (auch fuer das dynamische Kurvenlicht) | LWR und AFS Grundeinstellung";
CM_ SG_ 916 LRZ_Modus "schnelle oder langsame Regelart der LWR | LWR-Modus";
CM_ SG_ 916 LRZ_Initlauf "Initialisierungslauf der Schrittmotoren, erfolgt defaultmaessig beim Motorstart | LWR Initialisierungslauf";
CM_ SG_ 916 LRZ_Sichere_Pos "LWR Sicherheitsposition beider Scheinwerfers";
CM_ SG_ 916 LRZ_LampeAFS "Status der AFS Fehlerlampe: aktuell anliegender Fehlerzustand des dynamischen oder statischen Kurvenlichts";
CM_ SG_ 916 LRZ_Fehlerlampe "Status der Fehlerlampe: aktuell anliegender Fehlerzustand";
CM_ SG_ 916 LRZ_Fehler "Bei gesetztem Bit ist mindestens ein Kundendienstfehler eingetragen (auch sporadische bzw. passive Fehler). | LWR und AFS Fehlerspeichereintrag";
CM_ SG_ 916 LRZ_Einfedg_vo "aktueller Hoehensensorwert vorne (bei PQ35/46 links) | (oder bei Luftfederung aus der Niveau 2-Botschaft gespiegelt) | Einfederung Karosse vorn";
CM_ SG_ 916 LRZ_Einfedg_hi "aktueller Hoehensensorwert hinten (bei PQ35/46 links) | (oder bei Luftfederung aus der Niveau 2-Botschaft gespiegelt) | Einfederung Karosse hinten";
CM_ SG_ 916 LRZ_Stellung "Position des Aktuators in Prozent des maximalen Stellweges; vor dem Initialisierungslauf (z.Zt. Motorstart) wird der Initwert ausgegeben: | 0% : tiefste Stellung (auf Block) des Schrittmotors | 100% : maximaler Verstellweg des Schrittmotors (nicht die Grenze des Scheinwerfers) | Stellung der Schrittmotoren";
CM_ SG_ 916 LRZ_LeistDim "100% entsprechen 35 Watt | Die Last schaltet nur das ILM | Sollwert Leistungsdimmung EVG (links und rechts)";
CM_ SG_ 916 LRZ_ELF_links "Bei aktivierter Ersatzlichtfunktion wird das Abblendlicht ausgeschaltet und eine Ersatzlichtquelle eingeschaltet | Ersatzlichtfunktion links";
CM_ SG_ 916 LRZ_ELF_rechts "Bei aktivierter Ersatzlichtfunktion wird das Abblendlicht ausgeschaltet und eine Ersatzlichtquelle eingeschaltet | Ersatzlichtfunktion rechts";
CM_ SG_ 916 LRZ_AFSLED_Blink "Lampe soll im Warnfall mit 1Hz blinken, wenn das Bit gesetzt ist (z. Zt. nur bei VW) | AFS-LED Blinkmode";
CM_ SG_ 916 LRZ_AFSFehlertext "Fehlertext wird im Kombi angezeigt (z. Zt. nur bei VW) | AFS-Fehlertext";
CM_ SG_ 916 LRZ_Tourist_Fkt "Touristenfunktion wird vom AFS Steuergeraet unterstuetzt. | 0: Touristenfkt. nicht unterstuetzt | 1: Touristenfunktion unterstuetzt";
CM_ SG_ 916 LRZ_Tourist_aktiv "Touristenfunktion \"ein\" heisst Absenken der HGD und Schwenken deaktivieren wurde von AFS- Steuergeraet umgesetzt. | 0: Touristenfunktion deaktiviert | 1: Touristenfunktion aktiviert | Touristenfunktion ein /aus";
CM_ SG_ 916 LRZ_AFS_Absch "AFS Deaktivierung wird vom AFS Steuergeraet unterstuetzt. | Funktion auch waehrend der Fahrt bedienbar. | 0: keine AFS Deaktivierung ueber Kombi moeglich | 1: AFS unterstuetzt Deaktivierung ueber Kombi";
CM_ SG_ 916 LRZ_AFS_deaktiv "AFS deaktiviert heisst kein Schwenken und Standard-LWR also Anhebung in besonderen Geschwindigkeitsbereichen. | 0: AFS aktiviert | 1: AFS deaktiviert | AFS ein / aus";
CM_ SG_ 916 LRZ_Abbiegelicht_Dimm_Anf "Beschreibt ob das Abbiegelicht gedimmt oder hart einschalten werden soll. Dimmkurve ist im Empfaenger hinterlegt.";
CM_ SG_ 916 LRZ_Abbiegelicht_li_Anf "Anforderung das Abbiegelicht links einzuschalten";
CM_ SG_ 916 LRZ_Abbiegelicht_re_Anf "Anforderung das Abbiegelicht rechts einzuschalten";
CM_ SG_ 916 LRZ_Fernlicht_li_defekt "Beschreibt ob das Fernlicht des linken Scheinwerfers defekt ist";
CM_ SG_ 916 LRZ_Fernlicht_re_defekt "Beschreibt ob das Fernlicht des rechten Scheinwerfers defekt ist";
CM_ SG_ 916 LRZ_Fernlicht_Status "Beschreibt ob das Fernlicht aktiv oder inaktiv ist";
CM_ SG_ 916 LRZ_Verfuegbarkeit_GLW "Beschreibt die Verfuegbarkeit der Gleitenden Leuchtweite / Fernlichtassistenz - Verfuegbarkeit bedeutet, dass die Funktion Gleitende Leuchtweite moeglich ist";
CM_ SG_ 916 LRZ_Status_adaptive_LV "Gibt den Status der adaptiven Lichtverteilung an";
CM_ SG_ 916 GLW_Sensor_blockiert "Das Signal zeigt an, dass die Kamera zur Zeit keine Sicht hat. | Verhalten wie Fernlichtassistent. | Weiterleitung des Signals vom BCM an das KOMBI";
CM_ SG_ 916 AFS_Abblendlicht_li_defekt "Anzeige Abblendlicht links defekt";
CM_ SG_ 916 AFS_Abblendlicht_re_defekt "Anzeige Abblendlicht rechts defekt";
CM_ SG_ 916 LRZ_Zaehler "Botschaftszaehler der LWR-Zustandsbotschaft wird zyklisch beim Absenden jeder Botschaft um 1 inkrementiert";
CM_ SG_ 1423 MO_ITM_Kuehlmittel_Temp "Kuehlmitteltemperatur: Ersatzkuehlmitteltemperatur fuer Motoren mit ITM (Thermomanagement)";
CM_ SG_ 1423 M12_E85_Sensor "Information ueber den E85 Gehalt (%-mass.) im Ottokraftstoff";
CM_ SG_ 1423 M12_SCR_Anz_Motorstarts "Anzahl noch moeglicher Motorstarts, wenn Reichweite = 0 ist | 0..13 = Anzeige \"x moegliche Restarts\" | 14 = Eingeschraenkte Fahrfunktion (z. Zt. Audi) | 15 = keine Einschraenkung (Anzeige Reichweite)";
CM_ SG_ 1423 M12_SCR_Reichweite "Gesamtreichweite in km der aktuellen SCR-Tankfuellung";
CM_ SG_ 1423 SCR_Tankdeckel "Anzeige im Kombi: Tankdeckel offen";
CM_ SG_ 1423 M12_SCR_Warnstufe_1 "Ansteuerung der SCR Fuellstandswarnlampe (Stufe 1) (gelbe Lampe) | SCR_Warnstufe_1 (Prio 2)";
CM_ SG_ 1423 M12_SCR_Warnstufe_2 "Ansteuerung der SCR Fuellstandswarnlampe (Stufe 2) (Blinkbit fuer gelbe Lampe oder rote Lampe) | SCR_Warnstufe_2 (Prio 1)";
CM_ SG_ 1423 M12_SCR_Text "Warntext (z. B. in Kombination mit SCR Warnstufe und SCR-Systemfehler) | 0 = kein Text | 1 = Warntext 1 (Prio 2) | 2 = Warntext 2 (Prio 1) | 3 = Hinweistext bzgl. Fuellstand | 4 = reserviert | 5 = Warntext \"SCR-Systemfehler Stufe 1\" | 6 = Warntext \"SCR-Systemfehler Stufe 2\" | 7 = Hinweistext \"SCR-Systemfehler\"";
CM_ SG_ 1423 M12_Akustik "0 = keine Akustik | 1 = Akustik 1 (1xSummer 2000 bei VW) | 2 = Akustik 2 (3xSummer2000 bei VW) | 3 = Akustik bei Hinweis (Gong 1000 bei VW)";
CM_ SG_ 1423 M12_Luftfilter_Lampe "Lampe Luftfilter verschmutzt";
CM_ SG_ 1423 M12_Kraftstofffilter_Wasser "Fuer Schlechtkraftstofflaender wird das Wasserabscheidevolumen im Dieselkraftstofffilter mit einem Wassersensor ueberwacht. Ist das Volumen erschoepft, erfolgt im Kombi eine entsprechende Anzeige.";
CM_ SG_ 1423 M12_SCR_Systemfehler "Ansteuerung Anzeige fuer SCR-Systemfehler";
CM_ SG_ 1423 M12_SCR_Inducement "Reserviert fuer Information an das Kombi, welches Anzeigekonzept das Kombiinstrument passend zur Auslegung des Motor-Inducement-Konzeptes bedienen soll.";
CM_ SG_ 1423 M12_CO2_Faktor "dynamischer Umrechnungsfaktor von l in CO2";
CM_ SG_ 1423 M12_MKB_MUX "Die vier Motorkennbuchstaben werden gemultiplext in MO_MKB uebertragen. Das Signal MO_MKB_MUX stellt das Steuersignal fuer diesen Multiplexer dar.";
CM_ SG_ 1423 MO_EDK_Luefter_defekt "Warnung im Kombi, dass der EDK-Luefter (Engine-Dust-Kit) defekt ist. (Wird nur im Amarok verwendet.)";
CM_ SG_ 1423 M12_MKB_01 "Motorkennbuchstabe 1";
CM_ SG_ 1423 M12_MKB_02 "Motorkennbuchstabe 2";
CM_ SG_ 1423 M12_MKB_03 "Motorkennbuchstabe 3";
CM_ SG_ 1423 M12_MKB_04 "Motorkennbuchstabe 4";
CM_ SG_ 1450 MO_NMAX_Schaltanzeige "Maximaldrehzahl fuer Schaltanzeige (nur AU714 PA)";
CM_ SG_ 1450 MO_Ethanol_BS_Texte "Ethanol Brennstoff-Texte im Kombi | | 0 = kein Text | 1 = E85 Warm_Up | 2 = FlexFuel Warnung 3.Stufe (Too cold for ethanol) | 3 = Warmfahrempfehlung MQB / FlexFuel Warnung 1.Stufe (Refuel with gasoline) | 4 = FlexFuel Warnung 2. Stufe (Refuel with gasoline) | 5 = FlexFuel Warnung 4. Stufe (additional) (Next refuel use gasoline) | 6 = E25 Warm_Up | 7 = free";
CM_ SG_ 1450 MO_Heizungspumpenansteuerung "Anforderung Heizungspumpenansteuerung";
CM_ SG_ 1450 MO_Nachlaufzeit_Heizungspumpe "Nachlaufzeit fuer Heizungspumpe fuer Turboladerschutz";
CM_ SG_ 1450 MO_Absperrventil_oeffnen "Signal an Klima-SG das Absperrrventil anzusteuern.";
CM_ SG_ 1450 MO_aktives_Getriebeheizen "Information fuer Getriebe, ob ein Ventil fuer Getriebheizen angesteuert werden muss";
CM_ SG_ 1450 MO_Getriebe_kuehlen "Anforderung Getriebekuehlventilansteuerung";
CM_ SG_ 1450 MO_Zustand_HWP "Rueckmeldung des Ansteuerzustand der Hauptwasserpumpe an das Klima-SG . | Der Zustand \"HWP foerdert\" wird uebermittelt, wenn die Schaufeln der Hauptwasserpumpe frei drehen koennen und die Motordrehzahl und damit die Wasserpumpendrehzahl groesser als Null ist. Bei einer Wasserpumpe mit Magnetkupplung ist die Kupplung im Eingriff. Bei einer Wasserpumpe mit Topf ist der Topf zurueckgezogen und gibt die Schaufeln frei. | Der Zustand \"HWP foerdert nicht\" wird gesendet, wenn die Motordrehzahl und damit die Wasserpumpendrehzahl gleich Null ist (Verbrennungsmotor steht) oder wenn die Wasserpumpe nicht aktiv ist. Bei einer Pumpe mit Magnetkupplung ist in die Kupplung geoeffnet, bei einer getopften Wasserpumpe befindet sich der Topf ueber den Schaufeln.";
CM_ SG_ 1450 MO_BKV_Unterdruckwarnung "Ueber die Unterdruckwarnung signalisiert das MSG dem ESP, dass kein ausreichender Unterdruck fuer den BKV zur Verfuegung gestellt werden kann.";
CM_ SG_ 1450 MO_Zylinderabschaltung "Status Zylinderabschaltung Motor";
CM_ SG_ 1450 MO_Heizstrom_SCR "Aktuelle Gesamtstromaufnahme der Tank-, Foerdermodul- und Leitungsheizung des SCR-Systems";
CM_ SG_ 1450 MO_Heizstrom_EKAT "Aktuelle Gesamtstromaufnahme des E-Katalysators";
CM_ SG_ 1450 MO_Tankklappenstatus "Statusmeldung der Tankentriegelung";
CM_ SG_ 1450 MO_Tankklappensteuerung "Ansteuerung der Tankklappenentriegelung durch das BCM";
CM_ SG_ 1450 MO_Zylabsch_Texte_02 "ZAS-Anzeige fuer den Fahrer im Kombi | 0: kein ZAS (generell keinerlei ZAS-Anzeigen) (Init fuer nicht ZAS-Motor) | 1: ZAS im Vollmotorbetrieb (Init fuer ZAS-Motor) | 2: ZAS im Abschaltbetrieb: 1 Zyl aktiv | 3: ZAS im Abschaltbetrieb: 2 Zyl aktiv | 4: ZAS im Abschaltbetrieb: 3 Zyl aktiv | 5: ZAS im Abschaltbetrieb: 4 Zyl aktiv | 6: ZAS im Abschaltbetrieb: 5 Zyl aktiv | 7: ZAS im Abschaltbetrieb: 6 Zyl aktiv | 8: ZAS im Abschaltbetrieb: 8 Zyl aktiv | 9: ZAS im Abschaltbetrieb: 12 Zyl aktiv | 13: Uebergangsbetrieb | 14: keine ZAS Anzeige (ggf. im Stopp/Schub-Betrieb) | 15: ZAS Stoerungs-Anzeige";
CM_ SG_ 1450 MO_EFLEX_Lampe "Um ein Starten mit E100 zu ermoeglichen, wird Kraftstoff ggf. vorgeheizt. Das Signal dient der Anzeige des Heizungsstatus. | | Heizung aus -> Lampe aus | Heizung ein -> Lampe ein | Heizung ein und Startversuch -> Lampe blinkend | Heizung nicht moeglich -> Lampe blinkend & Akustik | | Nur VW120/2 (Lateinamerika)";
CM_ SG_ 1450 MO_Testmode_AG "Status Pruefstandbetrieb des MSGs";
CM_ SG_ 1450 MO_Ext_E_Fahrt_aktiv "AU716 und VW361/7: Funktionsrueckmeldung zum erw. E-Fahr-Betrieb ueber Lampe/LED im E-Mode-Taster";
CM_ SG_ 1450 MO_E85_WU_Lampe "E85 Warm Up Lampe im Kombi, nur Flexfuel (nur BY62x)";
CM_ SG_ 1450 MO_E85_WU_Texte "E85 Warm UP Text im Kombi, nur Flexfuel (nur BY62x und VW-FlexFuel-Konzepte)";
CM_ SG_ 1450 MO_Zylabsch_Texte "Texte Zylinderabschaltung (im BY62x)";
CM_ SG_ 1450 MO_E85_BS_Texte "E85 Brennstoff Texte im Kombi, nur Flexfuel (nur BY62x)";
CM_ SG_ 1450 MO_StartStopp_Codiert "Funktion StartStopp im aktuellen Klemmenzyklus verbaut | Nur Audi Q7 MP! | Wird in Fahrzeugprojekten der PQ25/35/46 zunaechst nicht unterstuetzt und ist ggf. gesondert einzufordern!";
CM_ SG_ 1407 MO_Charisma_FahrPr "Aktuelles Fahrprogramm des Charisma-Teilnehmers";
CM_ SG_ 1407 MO_Charisma_Status "Charisma Systemstatus des Charisma-Teilnehmers";
CM_ SG_ 1407 GE_Charisma_FahrPr "Aktuelles Fahrprogramm des Charisma-Teilnehmers";
CM_ SG_ 1407 GE_Charisma_Status "Charisma Systemstatus des Charisma-Teilnehmers";
CM_ SG_ 1407 EV_RekupStufe "Im Kombi anzuzeigende Rekuperationsstufe | (im VW120/7 werden die Werte 4 und 5 vom Kombi nicht ausgewertet)";
CM_ SG_ 1407 MO_Bremslicht_Reku "Bremslicht (ggf. bei Rekuperation durch E-Motor) wird angesteuert";
CM_ SG_ 1407 MO_Verbrauch_EM "Energieverbrauch E-Antrieb | | Interner Verbrauchszaehler, der vom Kombi zyklisch ausgelesen wird, um die Energiemenge zur Verbrauchsberechnung aufzusummieren; aus diesem Zaehlerstand werden Momentan-, Durchschnittsverbrauch und Reichweite berechnet; das Ueberlauf-Bit ist zu beruecksichtigen";
CM_ SG_ 1407 MO_UeberlVerb_EM "Der interne Verbrauchszaehler E-Antrieb ist mindestens einmal uebergelaufen.";
CM_ SG_ 1407 MO_Rekuperation_EM "Rekuperation E-Antrieb | | Interner Rekuperationsszaehler, der vom Kombi zyklisch ausgelesen wird, um die Energiemenge zur Rekuperationsberechnung aufzusummieren; aus diesem Zaehlerstand werden Momentan-, Durchschnittsverbrauch und Reichweite berechnet; das Ueberlauf-Bit ist zu beruecksichtigen";
CM_ SG_ 1407 MO_UeberlReku_EM "Der interne Rekuperationszaehler E-Antrieb ist mindestens einmal uebergelaufen.";
CM_ SG_ 1407 MO_Verbrauch_NA "Energieverbrauch Nebenaggregate (DCDC, EKK, Hochvolt-PTC) | | Interner Verbrauchszaehler, der vom Kombi zyklisch ausgelesen wird, um die Energiemenge zur Verbrauchsberechnung aufzusummieren; aus diesem Zaehlerstand werden Momentan-, Durchschnittsverbrauch und Reichweite berechnet; das Ueberlauf-Bit ist zu beruecksichtigen";
CM_ SG_ 1407 MO_UeberlVerb_NA "Der interne Verbrauchszaehler Nebenaggregate ist mindestens einmal uebergelaufen.";
BA_DEF_ BO_ "GenMsgCycleTime" INT 0 65535;
BA_DEF_ BO_ "GenMsgSendType" STRING ;
BA_DEF_ SG_ "GenSigSendType" STRING ;
BA_DEF_DEF_ "GenMsgCycleTime" 0;
BA_DEF_DEF_ "GenMsgSendType" "";
BA_DEF_DEF_ "GenSigSendType" "";
BA_ "GenMsgCycleTime" BO_ 914 100;
BA_ "GenMsgSendType" BO_ 914 "Cyclic";
BA_ "GenSigSendType" SG_ 914 GK2_Sta_LSM "Cyclic";
BA_ "GenSigSendType" SG_ 914 GK2_Sta_Lichtsensor "Cyclic";
BA_ "GenSigSendType" SG_ 914 GK2_Sta_Licht1 "Cyclic";
BA_ "GenSigSendType" SG_ 914 GK2_Sta_VSG "Cyclic";
BA_ "GenSigSendType" SG_ 914 GK2_Sta_Schluessel "Cyclic";
BA_ "GenSigSendType" SG_ 914 GK2_Sta_Profil "Cyclic";
BA_ "GenSigSendType" SG_ 914 GK2_Sta_Clima2 "Cyclic";
BA_ "GenSigSendType" SG_ 914 GK2_Sta_BSG4 "Cyclic";
BA_ "GenSigSendType" SG_ 914 GK2_Sta_Kessy_4 "Cyclic";
BA_ "GenSigSendType" SG_ 914 BS4_Gleitende_Leuchtw_Anf "OnChange";
BA_ "GenSigSendType" SG_ 914 BS4_GLW_Fernlicht_Anf "OnChange";
BA_ "GenSigSendType" SG_ 914 GK2_Blk_L_Kontrolle "Cyclic";
BA_ "GenSigSendType" SG_ 914 GK2_Blk_R_Kontrolle "Cyclic";
BA_ "GenSigSendType" SG_ 914 LS1_Lichthupe "OnChange";
BA_ "GenSigSendType" SG_ 914 GK2_LS_KomFehler "Cyclic";
BA_ "GenSigSendType" SG_ 914 GK2_LS_def "Cyclic";
BA_ "GenSigSendType" SG_ 914 GK2_Helligkeit "Cyclic";
BA_ "GenSigSendType" SG_ 914 GK2_VD_zu_ver "Cyclic";
BA_ "GenSigSendType" SG_ 914 GK2_VD_entriegelt "Cyclic";
BA_ "GenSigSendType" SG_ 914 GK2_VD_offen_ver "Cyclic";
BA_ "GenSigSendType" SG_ 914 GK2_Verdeck_Anf "Cyclic";
BA_ "GenSigSendType" SG_ 914 GK2_VDKD_auf "Cyclic";
BA_ "GenSigSendType" SG_ 914 GK2_Schluessel "OnChange";
BA_ "GenSigSendType" SG_ 914 GK2_Hardtop "Cyclic";
BA_ "GenSigSendType" SG_ 914 GK2_AFL_Schalter "Cyclic";
BA_ "GenSigSendType" SG_ 914 GK2_Nebelschluss "Cyclic";
BA_ "GenSigSendType" SG_ 914 GK2_EM_LIN_ungueltig "Cyclic";
BA_ "GenSigSendType" SG_ 914 GK2_Profil "Cyclic";
BA_ "GenSigSendType" SG_ 914 GK2_Kl_StSt_Info "Cyclic";
BA_ "GenSigSendType" SG_ 914 GK2_BSG_StSt_Info "Cyclic";
BA_ "GenSigSendType" SG_ 914 GK2_BEM_P_Generator "Cyclic";
BA_ "GenSigSendType" SG_ 914 GK2_BEM_Abschaltstufen "Cyclic";
BA_ "GenSigSendType" SG_ 914 GK2_BEM_DFM "Cyclic";
BA_ "GenSigSendType" SG_ 914 GK2_Kessy_StSt_Info "Cyclic";
BA_ "GenSigSendType" SG_ 914 GK2_BEM_StSt_Info "Cyclic";
BA_ "GenSigSendType" SG_ 914 BEM_Segel_Info "Cyclic";
BA_ "GenSigSendType" SG_ 914 LS1_FAS_Taster "OnChange";
BA_ "GenSigSendType" SG_ 914 LS1_Fehler_FAS_Taster "OnChange";
BA_ "GenMsgCycleTime" BO_ 915 200;
BA_ "GenMsgSendType" BO_ 915 "Cyclic";
BA_ "GenSigSendType" SG_ 915 GK3_Sta_Kessy_4 "Cyclic";
BA_ "GenSigSendType" SG_ 915 GK3_Sta_BCM_KY1 "Cyclic";
BA_ "GenSigSendType" SG_ 915 GK3_Sta_Clima_3 "Cyclic";
BA_ "GenSigSendType" SG_ 915 GK3_Sta_TSG_FT_3 "Cyclic";
BA_ "GenSigSendType" SG_ 915 GK3_Sta_HD_1 "Cyclic";
BA_ "GenSigSendType" SG_ 915 GK3_Sta_Memory_1 "Cyclic";
BA_ "GenSigSendType" SG_ 915 GK3_Sta_BSG4 "Cyclic";
BA_ "GenSigSendType" SG_ 915 GK3_Sta_MFG1 "Cyclic";
BA_ "GenSigSendType" SG_ 915 GK3_KY4_Meldungen "OnChange";
BA_ "GenSigSendType" SG_ 915 GK3_KY4_Gong_600 "OnChange";
BA_ "GenSigSendType" SG_ 915 MG1_ext_Last "OnChange";
BA_ "GenSigSendType" SG_ 915 GK3_KY4_PassAL_Menue "OnChange";
BA_ "GenSigSendType" SG_ 915 GK3_KY4_PassAL_akt "OnChange";
BA_ "GenSigSendType" SG_ 915 GK3_BK1_IDGeb_1_Sta "OnChange";
BA_ "GenSigSendType" SG_ 915 GK3_BK1_IDGeb_2_Sta "OnChange";
BA_ "GenSigSendType" SG_ 915 ME1_EasyEntry_Menu "Cyclic";
BA_ "GenSigSendType" SG_ 915 ME1_EasyEntry_aktiv "OnChange";
BA_ "GenSigSendType" SG_ 915 GK3_BK1_IDGeb_3_Sta "OnChange";
BA_ "GenSigSendType" SG_ 915 GK3_BK1_IDGeb_4_Sta "OnChange";
BA_ "GenSigSendType" SG_ 915 GK3_BK1_Anlern_Info "OnChange";
BA_ "GenSigSendType" SG_ 915 CL3_Defrost "OnChange";
BA_ "GenSigSendType" SG_ 915 CL3_SH_Wasserpumpe "OnChange";
BA_ "GenSigSendType" SG_ 915 FT3_Auto_eKiSi_Menu "Cyclic";
BA_ "GenSigSendType" SG_ 915 FT3_Auto_eKiSi_Aktiv "OnChange";
BA_ "GenSigSendType" SG_ 915 MKE_Texte "Cyclic";
BA_ "GenSigSendType" SG_ 915 HSA_unplausibel "OnChange";
BA_ "GenSigSendType" SG_ 915 FT_Kisi_Fehler "Cyclic";
BA_ "GenSigSendType" SG_ 915 BCM_Tankwunsch "Cyclic";
BA_ "GenSigSendType" SG_ 915 BCM_Hybrid_StartStopp_Taste "OnChange";
BA_ "GenSigSendType" SG_ 915 KL_nachtr_Stopp_Anf "OnChange";
BA_ "GenSigSendType" SG_ 915 HD1_Endstellung_oben "OnChange";
BA_ "GenSigSendType" SG_ 915 HD1_Endstellung_unten "OnChange";
BA_ "GenSigSendType" SG_ 915 BCM_Bremslicht_defekt "Cyclic";
BA_ "GenSigSendType" SG_ 915 LIA_AFL_Schalter "OnChange";
BA_ "GenSigSendType" SG_ 915 HD1_Position "OnChange";
BA_ "GenMsgCycleTime" BO_ 684 20;
BA_ "GenMsgSendType" BO_ 684 "Cyclic";
BA_ "GenSigSendType" SG_ 684 GS1_Zaehler "Cyclic";
BA_ "GenSigSendType" SG_ 684 GS1_Fahrtrichtung "Cyclic";
BA_ "GenSigSendType" SG_ 684 GS1_QBit_Rad_kmh "Cyclic";
BA_ "GenSigSendType" SG_ 684 GS1_Rad_kmh "Cyclic";
BA_ "GenSigSendType" SG_ 684 GS1_Checksumme "Cyclic";
BA_ "GenMsgCycleTime" BO_ 1344 10;
BA_ "GenMsgSendType" BO_ 1344 "Cyclic";
BA_ "GenSigSendType" SG_ 1344 GE2_LFR_Adap "Cyclic";
BA_ "GenSigSendType" SG_ 1344 GE2_Sta_SAS "Cyclic";
BA_ "GenSigSendType" SG_ 1344 GE2_LowSpeedMode_gueltig "Cyclic";
BA_ "GenSigSendType" SG_ 1344 GE2_Sta_ZwGas "Cyclic";
BA_ "GenSigSendType" SG_ 1344 GE2_Zaehler "Cyclic";
BA_ "GenSigSendType" SG_ 1344 GE2_LL_Solldz "Cyclic";
BA_ "GenSigSendType" SG_ 1344 GE2_Grad_begr "Cyclic";
BA_ "GenSigSendType" SG_ 1344 GE2_Sync_Dz "Cyclic";
BA_ "GenSigSendType" SG_ 1344 GE2_invSync_Dz "Cyclic";
BA_ "GenSigSendType" SG_ 1344 GE2_Sync_Zeit "Cyclic";
BA_ "GenSigSendType" SG_ 1344 GE2_DZM_Daempf "Cyclic";
BA_ "GenSigSendType" SG_ 1344 GE2_invMSB_Sync "Cyclic";
BA_ "GenSigSendType" SG_ 1344 GE2_Gong "Cyclic";
BA_ "GenSigSendType" SG_ 1344 GE2_Segeln_aktiv "Cyclic";
BA_ "GenSigSendType" SG_ 1344 GE2_Shift_Lock "Cyclic";
BA_ "GenSigSendType" SG_ 1344 GE2_Senderkennung "Cyclic";
BA_ "GenSigSendType" SG_ 1344 GE2_MSB_Sync "Cyclic";
BA_ "GenSigSendType" SG_ 1344 GE2_WBA_Blinken "Cyclic";
BA_ "GenSigSendType" SG_ 1344 GE2_Variante "Cyclic";
BA_ "GenSigSendType" SG_ 1344 GE2_5Gang "NoSigSendType";
BA_ "GenSigSendType" SG_ 1344 GE2_PRNDL "NoSigSendType";
BA_ "GenSigSendType" SG_ 1344 GE2_4Gang "NoSigSendType";
BA_ "GenSigSendType" SG_ 1344 GE2_ASG "NoSigSendType";
BA_ "GenSigSendType" SG_ 1344 GE2_Selespeed "NoSigSendType";
BA_ "GenSigSendType" SG_ 1344 GE2_res_MUX5 "NoSigSendType";
BA_ "GenSigSendType" SG_ 1344 GE2_PRNDS "NoSigSendType";
BA_ "GenSigSendType" SG_ 1344 GE2_PRNED "NoSigSendType";
BA_ "GenSigSendType" SG_ 1344 GE2_Tip4Gang "NoSigSendType";
BA_ "GenSigSendType" SG_ 1344 GE2_Tip5Gang "NoSigSendType";
BA_ "GenSigSendType" SG_ 1344 GE2_Sollgang "NoSigSendType";
BA_ "GenSigSendType" SG_ 1344 GE2_PRNDB "NoSigSendType";
BA_ "GenSigSendType" SG_ 1344 GE2_Tip6Gang "NoSigSendType";
BA_ "GenSigSendType" SG_ 1344 GE2_Tip7Gang "NoSigSendType";
BA_ "GenSigSendType" SG_ 1344 GE2_Tip8Gang "NoSigSendType";
BA_ "GenSigSendType" SG_ 1344 GE2_akt_Gang "NoSigSendType";
BA_ "GenMsgCycleTime" BO_ 1090 10;
BA_ "GenMsgSendType" BO_ 1090 "Cyclic";
BA_ "GenSigSendType" SG_ 1090 GM3_Checksum "Cyclic";
BA_ "GenSigSendType" SG_ 1090 GM3_Zaehler "Cyclic";
BA_ "GenSigSendType" SG_ 1090 GM3_MomEingr "Cyclic";
BA_ "GenSigSendType" SG_ 1090 GM3_MoSoMom "Cyclic";
BA_ "GenSigSendType" SG_ 1090 GM3_StaSoMom "Cyclic";
BA_ "GenSigSendType" SG_ 1090 GM3_MomID "Cyclic";
BA_ "GenSigSendType" SG_ 1090 GM3_Zeit "Cyclic";
BA_ "GenSigSendType" SG_ 1090 GM3_Moment "Cyclic";
BA_ "GenSigSendType" SG_ 1090 GM3_QB_LangEingr "Cyclic";
BA_ "GenSigSendType" SG_ 1090 GM3_LangEingr "Cyclic";
BA_ "GenMsgCycleTime" BO_ 1352 20;
BA_ "GenMsgSendType" BO_ 1352 "Cyclic";
BA_ "GenSigSendType" SG_ 1352 GE4_Shiftlock "Cyclic";
BA_ "GenSigSendType" SG_ 1352 GE4_AuslModus "Cyclic";
BA_ "GenSigSendType" SG_ 1352 GE4_Test "Cyclic";
BA_ "GenSigSendType" SG_ 1352 GE4_Tasterausleuchtung "Cyclic";
BA_ "GenSigSendType" SG_ 1352 GE4_Ausleuchtung "Cyclic";
BA_ "GenSigSendType" SG_ 1352 GE4_Testparam_1 "Cyclic";
BA_ "GenSigSendType" SG_ 1352 GE4_Testparam_2 "Cyclic";
BA_ "GenMsgCycleTime" BO_ 1346 10;
BA_ "GenMsgSendType" BO_ 1346 "Cyclic";
BA_ "GenSigSendType" SG_ 1346 GE5_Test "Cyclic";
BA_ "GenSigSendType" SG_ 1346 GE5_Abschalten "Cyclic";
BA_ "GenSigSendType" SG_ 1346 GE5_Sta_Fahrstufe "Cyclic";
BA_ "GenSigSendType" SG_ 1346 GE5_Ausl_Sport "Cyclic";
BA_ "GenSigSendType" SG_ 1346 GE5_Ausl_Winter "Cyclic";
BA_ "GenSigSendType" SG_ 1346 GE5_Ausleuchtung "Cyclic";
BA_ "GenSigSendType" SG_ 1346 GE5_keine_Ausleuchtung "Cyclic";
BA_ "GenSigSendType" SG_ 1346 GE5_Testparam_1 "Cyclic";
BA_ "GenSigSendType" SG_ 1346 GE5_Testparam_2 "Cyclic";
BA_ "GenMsgCycleTime" BO_ 1100 20;
BA_ "GenMsgSendType" BO_ 1100 "Cyclic";
BA_ "GenSigSendType" SG_ 1100 GE6_Checksum "Cyclic";
BA_ "GenSigSendType" SG_ 1100 GE6_TurbDZ "Cyclic";
BA_ "GenSigSendType" SG_ 1100 GE6_QmaxBeschl "Cyclic";
BA_ "GenSigSendType" SG_ 1100 GE6_QB_OelTemp "Cyclic";
BA_ "GenSigSendType" SG_ 1100 GE6_OelTemp "Cyclic";
BA_ "GenSigSendType" SG_ 1100 GE6_maxBeschl "Cyclic";
BA_ "GenSigSendType" SG_ 1100 GE6_Gangwechsel "Cyclic";
BA_ "GenSigSendType" SG_ 1100 GE6_Zielgang_err "Cyclic";
BA_ "GenSigSendType" SG_ 1100 GE_Betaetigung_Hold "Cyclic";
BA_ "GenSigSendType" SG_ 1100 GE_Heizwunsch "Cyclic";
BA_ "GenSigSendType" SG_ 1100 GE1_StSt_Info "Cyclic";
BA_ "GenSigSendType" SG_ 1100 GE6_Verlustmom "Cyclic";
BA_ "GenSigSendType" SG_ 1100 GE6_Zaehler "Cyclic";
BA_ "GenMsgCycleTime" BO_ 1348 100;
BA_ "GenMsgSendType" BO_ 1348 "Cyclic";
BA_ "GenSigSendType" SG_ 1348 GE7_Text_01 "Cyclic";
BA_ "GenSigSendType" SG_ 1348 GE7_Text_02 "Cyclic";
BA_ "GenSigSendType" SG_ 1348 GE7_Text_03 "Cyclic";
BA_ "GenSigSendType" SG_ 1348 GE7_Gong "Cyclic";
BA_ "GenSigSendType" SG_ 1348 GE7_Text_04 "Cyclic";
BA_ "GenSigSendType" SG_ 1348 GE7_Text_05 "Cyclic";
BA_ "GenSigSendType" SG_ 1348 GE7_Waehlh_ausgef "Cyclic";
BA_ "GenSigSendType" SG_ 1348 GE7_Text_07 "Cyclic";
BA_ "GenSigSendType" SG_ 1348 GE7_Feh_1Warn "Cyclic";
BA_ "GenSigSendType" SG_ 1348 GE7_Feh_2Warn "Cyclic";
BA_ "GenSigSendType" SG_ 1348 GE7_SyncWarn "Cyclic";
BA_ "GenSigSendType" SG_ 1348 GE_Segeln_Menueanf "Cyclic";
BA_ "GenSigSendType" SG_ 1348 GE_Segeln_Status "Cyclic";
BA_ "GenSigSendType" SG_ 1348 GE7_Akustik "Cyclic";
BA_ "GenSigSendType" SG_ 1348 GE7_Wegrollwarnung "Cyclic";
BA_ "GenSigSendType" SG_ 1348 GE7_Temp_Warnstufe_I "Cyclic";
BA_ "GenSigSendType" SG_ 1348 GE7_Text_08 "Cyclic";
BA_ "GenSigSendType" SG_ 1348 GE7_Text_09 "Cyclic";
BA_ "GenSigSendType" SG_ 1348 GE7_Text_10 "Cyclic";
BA_ "GenSigSendType" SG_ 1348 GE7_Text_11 "Cyclic";
BA_ "GenSigSendType" SG_ 1348 GE7_Text_12 "Cyclic";
BA_ "GenSigSendType" SG_ 1348 GE7_Feh_3Warn "Cyclic";
BA_ "GenSigSendType" SG_ 1348 GE7_Stop_Warn "Cyclic";
BA_ "GenSigSendType" SG_ 1348 GE7_Feh_4Warn "Cyclic";
BA_ "GenSigSendType" SG_ 1348 GE_Fahrprogramm "OnChange";
BA_ "GenSigSendType" SG_ 1348 GE_Anf_Zylinderabsch "OnChange";
BA_ "GenSigSendType" SG_ 1348 GE_Sumpftemperatur "Cyclic";
BA_ "GenMsgCycleTime" BO_ 1104 10;
BA_ "GenMsgSendType" BO_ 1104 "Cyclic";
BA_ "GenSigSendType" SG_ 1104 GE8_Checksumme "Cyclic";
BA_ "GenSigSendType" SG_ 1104 GE8_Zaehler "Cyclic";
BA_ "GenSigSendType" SG_ 1104 GE8_Hydr_Pumpe "Cyclic";
BA_ "GenSigSendType" SG_ 1104 GE8_Motor_aus "Cyclic";
BA_ "GenSigSendType" SG_ 1104 GE8_Anfahrfkt "Cyclic";
BA_ "GenSigSendType" SG_ 1104 GE8_SollDZ "Cyclic";
BA_ "GenSigSendType" SG_ 1104 GE8_VorsteuerMom "Cyclic";
BA_ "GenSigSendType" SG_ 1104 GE8_KuppMom "Cyclic";
BA_ "GenMsgCycleTime" BO_ 1108 20;
BA_ "GenMsgSendType" BO_ 1108 "Cyclic";
BA_ "GenSigSendType" SG_ 1108 Getriebe_9_Checksum "Cyclic";
BA_ "GenSigSendType" SG_ 1108 Getriebe_9_BZ "Cyclic";
BA_ "GenSigSendType" SG_ 1108 GE_Sollstellung_Parksperre "Cyclic";
BA_ "GenSigSendType" SG_ 1108 GE_PHM_Diag_Status "Cyclic";
BA_ "GenSigSendType" SG_ 1108 GE_Soll_Strom_KUV2 "Cyclic";
BA_ "GenSigSendType" SG_ 1108 GE_Soll_Hauptdruck_berechnet "Cyclic";
BA_ "GenSigSendType" SG_ 1108 GE_Sumpftemperatur_2 "Cyclic";
BA_ "GenSigSendType" SG_ 1108 GE_TVH_Wasserzusatzpumpe "Cyclic";
BA_ "GenSigSendType" SG_ 1108 GE_TVH_Oelpumpe "Cyclic";
BA_ "GenSigSendType" SG_ 1108 GE_Freigabe_Spuehlfkt "Cyclic";
BA_ "GenMsgCycleTime" BO_ 1106 20;
BA_ "GenMsgSendType" BO_ 1106 "Cyclic";
BA_ "GenSigSendType" SG_ 1106 GH1_Zaehler "Cyclic";
BA_ "GenSigSendType" SG_ 1106 GH1_FreigabeK0 "Cyclic";
BA_ "GenSigSendType" SG_ 1106 GH1_FreigabeVMStop "Cyclic";
BA_ "GenSigSendType" SG_ 1106 GH1_FehlerstatusGSG "Cyclic";
BA_ "GenSigSendType" SG_ 1106 GH1_nK0 "Cyclic";
BA_ "GenSigSendType" SG_ 1106 GH1_VZMomEingriff "Cyclic";
BA_ "GenSigSendType" SG_ 1106 GH1_MomEingriff_EM "Cyclic";
BA_ "GenSigSendType" SG_ 1106 GH1_Wiederstart "Cyclic";
BA_ "GenSigSendType" SG_ 1106 GH1_VM_akt_halten "Cyclic";
BA_ "GenSigSendType" SG_ 1106 GH1_Sportfaktor "Cyclic";
BA_ "GenSigSendType" SG_ 1106 GH1_Freig_LL_Reg "Cyclic";
BA_ "GenSigSendType" SG_ 1106 GH1_VKM_StAnf "Cyclic";
BA_ "GenSigSendType" SG_ 1106 GH1_VKM_StKontr "Cyclic";
BA_ "GenSigSendType" SG_ 1106 GH1_AnzeigeDZ "Cyclic";
BA_ "GenSigSendType" SG_ 1106 GH1_Filt_MomAufbau "Cyclic";
BA_ "GenSigSendType" SG_ 1106 GE_Freigabe_Verfallsinfo_WFS "Cyclic";
BA_ "GenMsgCycleTime" BO_ 1110 20;
BA_ "GenMsgSendType" BO_ 1110 "Cyclic";
BA_ "GenSigSendType" SG_ 1110 Getriebe_Zusatz_01_Checksum "Cyclic";
BA_ "GenSigSendType" SG_ 1110 Getriebe_Zusatz_01_BZ "Cyclic";
BA_ "GenSigSendType" SG_ 1110 GZ_OBD_Status "Cyclic";
BA_ "GenSigSendType" SG_ 1110 GZ_PHM_Diagnose "Cyclic";
BA_ "GenSigSendType" SG_ 1110 GZ_Position_Parksperre "Cyclic";
BA_ "GenSigSendType" SG_ 1110 GZ_Kuehloeltemperatur "Cyclic";
BA_ "GenSigSendType" SG_ 1110 GZ_IST_Strom_KUV2 "Cyclic";
BA_ "GenSigSendType" SG_ 1110 GZ_KuehlOel2_Status "Cyclic";
BA_ "GenSigSendType" SG_ 1110 GZ_PAV_Status "Cyclic";
BA_ "GenSigSendType" SG_ 1110 GZ_PEV_Status "Cyclic";
BA_ "GenSigSendType" SG_ 1110 GZ_PHM_Status "Cyclic";
BA_ "GenSigSendType" SG_ 1110 GZ_Schaltwippen_TipDown_02 "Cyclic";
BA_ "GenSigSendType" SG_ 1110 GZ_Schaltwippen_TipUp_02 "Cyclic";
BA_ "GenSigSendType" SG_ 1110 ZSG_Initialisierung "Cyclic";
BA_ "GenSigSendType" SG_ 1110 GZ_Warnung "Cyclic";
BA_ "GenSigSendType" SG_ 1110 GZ_Oelpumpe_Status "Cyclic";
BA_ "GenSigSendType" SG_ 1110 GZ_Schaltwippen_TipDown "OnChange";
BA_ "GenSigSendType" SG_ 1110 GZ_Schaltwippen_TipUp "OnChange";
BA_ "GenSigSendType" SG_ 1110 GZ_KD_Fehler "Cyclic";
BA_ "GenMsgCycleTime" BO_ 906 30;
BA_ "GenMsgSendType" BO_ 906 "Cyclic";
BA_ "GenSigSendType" SG_ 906 GRA_Checksum "Cyclic";
BA_ "GenSigSendType" SG_ 906 GRA_Hauptschalt "Cyclic";
BA_ "GenSigSendType" SG_ 906 GRA_Abbrechen "Cyclic";
BA_ "GenSigSendType" SG_ 906 GRA_Down_kurz "Cyclic";
BA_ "GenSigSendType" SG_ 906 GRA_Up_kurz "Cyclic";
BA_ "GenSigSendType" SG_ 906 GRA_Down_lang "Cyclic";
BA_ "GenSigSendType" SG_ 906 GRA_Up_lang "Cyclic";
BA_ "GenSigSendType" SG_ 906 GRA_Fehler_Bed "Cyclic";
BA_ "GenSigSendType" SG_ 906 GRA_Kodierinfo "Cyclic";
BA_ "GenSigSendType" SG_ 906 GRA_Neu_Setzen "Cyclic";
BA_ "GenSigSendType" SG_ 906 GRA_Recall "Cyclic";
BA_ "GenSigSendType" SG_ 906 GRA_Sender "Cyclic";
BA_ "GenSigSendType" SG_ 906 GRA_Neu_Zaehler "Cyclic";
BA_ "GenSigSendType" SG_ 906 GRA_Tip_Down "Cyclic";
BA_ "GenSigSendType" SG_ 906 GRA_Tip_Up "Cyclic";
BA_ "GenSigSendType" SG_ 906 GRA_Zeitluecke "Cyclic";
BA_ "GenSigSendType" SG_ 906 GRA_Limiter "Cyclic";
BA_ "GenSigSendType" SG_ 906 GRA_Typ_Hauptschalt "Cyclic";
BA_ "GenSigSendType" SG_ 906 GRA_LIM_Taste_verfuegbar "Cyclic";
BA_ "GenSigSendType" SG_ 906 GRA_Fehler_Tip "Cyclic";
BA_ "GenMsgCycleTime" BO_ 1529 1000;
BA_ "GenMsgSendType" BO_ 1529 "Cyclic";
BA_ "GenSigSendType" SG_ 1529 GM_KD_Fehler "Cyclic";
BA_ "GenMsgCycleTime" BO_ 1164 40;
BA_ "GenMsgSendType" BO_ 1164 "Cyclic";
BA_ "GenSigSendType" SG_ 1164 HS1_Checksumme "Cyclic";
BA_ "GenSigSendType" SG_ 1164 HS1_Zaehler "Cyclic";
BA_ "GenSigSendType" SG_ 1164 HS1_Drehz_Grenze "Cyclic";
BA_ "GenSigSendType" SG_ 1164 HS1_Gang "Cyclic";
BA_ "GenSigSendType" SG_ 1164 MO_NGS_Position "Cyclic";
BA_ "GenSigSendType" SG_ 1164 MO_NGS_Status "Cyclic";
BA_ "GenMsgCycleTime" BO_ 210 20;
BA_ "GenMsgSendType" BO_ 210 "Cyclic";
BA_ "GenSigSendType" SG_ 210 HC1_Checksumme "Cyclic";
BA_ "GenSigSendType" SG_ 210 HC1_Zaehler "Cyclic";
BA_ "GenSigSendType" SG_ 210 HC1_Sta_HCA "Cyclic";
BA_ "GenSigSendType" SG_ 210 HC1_LM_Offset "Cyclic";
BA_ "GenSigSendType" SG_ 210 HC1_LM_Offset_Sign "Cyclic";
BA_ "GenSigSendType" SG_ 210 HC1_Frequenz "Cyclic";
BA_ "GenSigSendType" SG_ 210 HC1_Amplitude "Cyclic";
BA_ "GenMsgCycleTime" BO_ 1512 500;
BA_ "GenMsgSendType" BO_ 1512 "Cyclic";
BA_ "GenSigSendType" SG_ 1512 KL_HV_ein "Cyclic";
BA_ "GenSigSendType" SG_ 1512 KL_Innengeblaese "Cyclic";
BA_ "GenSigSendType" SG_ 1512 KL_PTC_Pumpe_Soll "Cyclic";
BA_ "GenSigSendType" SG_ 1512 KL_Beschlagsgefahr "Cyclic";
BA_ "GenSigSendType" SG_ 1512 KL_Standklima_RemoteModus "OnChange";
BA_ "GenSigSendType" SG_ 1512 KL_Wake_Up_ACAN "OnChange";
BA_ "GenSigSendType" SG_ 1512 KL_HV_Anf "Cyclic";
BA_ "GenSigSendType" SG_ 1512 KL_Ventil_Batterie_Anf "Cyclic";
BA_ "GenSigSendType" SG_ 1512 KL_Ventil_vor_Motor_Anf "Cyclic";
BA_ "GenSigSendType" SG_ 1512 PTC_Strom "Cyclic";
BA_ "GenSigSendType" SG_ 1512 EKK_Strom "Cyclic";
BA_ "GenSigSendType" SG_ 1512 KL_Kompr_Drehzahl_Soll "Cyclic";
BA_ "GenSigSendType" SG_ 1512 EKK_Status "Cyclic";
BA_ "GenSigSendType" SG_ 1512 KL_Standklima_Status_02 "OnChange";
BA_ "GenSigSendType" SG_ 1512 PTC_Pumpe_Ist "Cyclic";
BA_ "GenSigSendType" SG_ 1512 PTC_Pumpe_Status "Cyclic";
BA_ "GenSigSendType" SG_ 1512 KL_Charisma_FahrPr "OnChange";
BA_ "GenSigSendType" SG_ 1512 KL_Charisma_Status "OnChange";
BA_ "GenSigSendType" SG_ 1512 EKK_Status_Vorstrg "OnChange";
BA_ "GenSigSendType" SG_ 1512 KL_Vorwarn_HVHeizer_Leistung "OnChange";
BA_ "GenMsgCycleTime" BO_ 1527 500;
BA_ "GenMsgSendType" BO_ 1527 "Cyclic";
BA_ "GenSigSendType" SG_ 1527 KE1_Comp_enable "Cyclic";
BA_ "GenSigSendType" SG_ 1527 KE1_Umluftstellung "Cyclic";
BA_ "GenSigSendType" SG_ 1527 KE1_Comp_rev_rq "Cyclic";
BA_ "GenMsgCycleTime" BO_ 800 25;
BA_ "GenMsgSendType" BO_ 800 "Cyclic";
BA_ "GenSigSendType" SG_ 800 KO1_SleepInd "Cyclic";
BA_ "GenSigSendType" SG_ 800 KO1_Sta_Tank "Cyclic";
BA_ "GenSigSendType" SG_ 800 KO1_Oeldruck "Cyclic";
BA_ "GenSigSendType" SG_ 800 KO1_Sta_Oeldr "Cyclic";
BA_ "GenSigSendType" SG_ 800 KO1_Kuehlmittel "Cyclic";
BA_ "GenSigSendType" SG_ 800 KO1_Wakeup_Komfort "Cyclic";
BA_ "GenSigSendType" SG_ 800 KO1_Warn_Tank "Cyclic";
BA_ "GenSigSendType" SG_ 800 KO1_Vorgluehen "Cyclic";
BA_ "GenSigSendType" SG_ 800 KO1_Bremsinfo "Cyclic";
BA_ "GenSigSendType" SG_ 800 KO1_Handbremse "Cyclic";
BA_ "GenSigSendType" SG_ 800 KO1_La_Ladekon "Cyclic";
BA_ "GenSigSendType" SG_ 800 KO1_Stellglieder "Cyclic";
BA_ "GenSigSendType" SG_ 800 KO1_Zeitluecke "Cyclic";
BA_ "GenSigSendType" SG_ 800 KO1_Tankstop "Cyclic";
BA_ "GenSigSendType" SG_ 800 KO1_Tankinhalt "Cyclic";
BA_ "GenSigSendType" SG_ 800 KO1_OBD_Tank "Cyclic";
BA_ "GenSigSendType" SG_ 800 KO1_Quelle_kmh "Cyclic";
BA_ "GenSigSendType" SG_ 800 KO1_kmh "Cyclic";
BA_ "GenSigSendType" SG_ 800 KO1_Zaehler "Cyclic";
BA_ "GenSigSendType" SG_ 800 KO1_ACC_Inkons "Cyclic";
BA_ "GenSigSendType" SG_ 800 KO1_ACC_AnzFhl "Cyclic";
BA_ "GenSigSendType" SG_ 800 KO1_angez_kmh "Cyclic";
BA_ "GenSigSendType" SG_ 800 KO1_kmh_mph "Cyclic";
BA_ "GenSigSendType" SG_ 800 KO1_ABS_Lampe "Cyclic";
BA_ "GenSigSendType" SG_ 800 KO1_ASRESP_Lampe "Cyclic";
BA_ "GenSigSendType" SG_ 800 KO1_Brems_Lampe "Cyclic";
BA_ "GenSigSendType" SG_ 800 KO1_Airbag_Lampe "Cyclic";
BA_ "GenSigSendType" SG_ 800 KO1_Lenkh_Lampe "Cyclic";
BA_ "GenSigSendType" SG_ 800 KO1_LDW_AnzFeh "Cyclic";
BA_ "GenSigSendType" SG_ 800 KO1_SILA_gueltig "Cyclic";
BA_ "GenMsgCycleTime" BO_ 1470 50;
BA_ "GenMsgSendType" BO_ 1470 "Cyclic";
BA_ "GenSigSendType" SG_ 1470 LDW_Lernmodus_seitenabhaengig "Cyclic";
BA_ "GenSigSendType" SG_ 1470 LDW_Lernmodus "Cyclic";
BA_ "GenSigSendType" SG_ 1470 LDW_Textbits "Cyclic";
BA_ "GenSigSendType" SG_ 1470 LDW_Gong "Cyclic";
BA_ "GenSigSendType" SG_ 1470 LDW_Kameratyp "Cyclic";
BA_ "GenSigSendType" SG_ 1470 LDW_Lampe_gelb "Cyclic";
BA_ "GenSigSendType" SG_ 1470 LDW_Lampe_gruen "Cyclic";
BA_ "GenSigSendType" SG_ 1470 LDW_SW_Warnung_links "Cyclic";
BA_ "GenSigSendType" SG_ 1470 LDW_SW_Warnung_rechts "Cyclic";
BA_ "GenSigSendType" SG_ 1470 LDW_KD_Fehler "Cyclic";
BA_ "GenSigSendType" SG_ 1470 LDW_DLC "Cyclic";
BA_ "GenSigSendType" SG_ 1470 LDW_TLC "Cyclic";
BA_ "GenSigSendType" SG_ 1470 LDW_Seite_DLCTLC "Cyclic";
BA_ "GenSigSendType" SG_ 1470 LDW_Frueh_Spaet "Cyclic";
BA_ "GenMsgCycleTime" BO_ 976 20;
BA_ "GenMsgSendType" BO_ 976 "Cyclic";
BA_ "GenSigSendType" SG_ 976 LH1_Lastinfo "Cyclic";
BA_ "GenSigSendType" SG_ 976 LH1_Fehler_LI "Cyclic";
BA_ "GenSigSendType" SG_ 976 LH1_Sicherheitslamp "Cyclic";
BA_ "GenSigSendType" SG_ 976 LH1_Fehlerlampe "Cyclic";
BA_ "GenSigSendType" SG_ 976 LH1_Textbits "Cyclic";
BA_ "GenSigSendType" SG_ 976 LH1_Akustiksign "Cyclic";
BA_ "GenSigSendType" SG_ 976 LH1_SleepInd "Cyclic";
BA_ "GenSigSendType" SG_ 976 LH1_Fehlereintr "Cyclic";
BA_ "GenSigSendType" SG_ 976 LH1_EPS_Diagmode "Cyclic";
BA_ "GenSigSendType" SG_ 976 LH1_gue_ECU_Temp "Cyclic";
BA_ "GenSigSendType" SG_ 976 LH1_Kuehlung "Cyclic";
BA_ "GenSigSendType" SG_ 976 LH1_Mode_Hybrid "Cyclic";
BA_ "GenSigSendType" SG_ 976 LH1_NL_Untersp "Cyclic";
BA_ "GenSigSendType" SG_ 976 LH1_NL_Uebersp "Cyclic";
BA_ "GenSigSendType" SG_ 976 LH1_NL_Uebertemp "Cyclic";
BA_ "GenSigSendType" SG_ 976 LH1_NL_Sensor "Cyclic";
BA_ "GenSigSendType" SG_ 976 LH1_NL_CAN_SS "Cyclic";
BA_ "GenSigSendType" SG_ 976 LH1_NL_ECU "Cyclic";
BA_ "GenSigSendType" SG_ 976 LH1_NL_Motor "Cyclic";
BA_ "GenSigSendType" SG_ 976 LH1_NL_LeistDichte "Cyclic";
BA_ "GenSigSendType" SG_ 976 LH1_ULeistung "Cyclic";
BA_ "GenSigSendType" SG_ 976 LH1_ECU_Temp "Cyclic";
BA_ "GenMsgCycleTime" BO_ 398 10;
BA_ "GenMsgSendType" BO_ 398 "Cyclic";
BA_ "GenSigSendType" SG_ 398 LPG_01_Reserve "Cyclic";
BA_ "GenMsgCycleTime" BO_ 654 50;
BA_ "GenMsgSendType" BO_ 654 "Cyclic";
BA_ "GenSigSendType" SG_ 654 LPG_02_Reserve "Cyclic";
BA_ "GenMsgCycleTime" BO_ 655 50;
BA_ "GenMsgSendType" BO_ 655 "Cyclic";
BA_ "GenSigSendType" SG_ 655 LPG_03_Reserve "Cyclic";
BA_ "GenMsgCycleTime" BO_ 658 50;
BA_ "GenMsgSendType" BO_ 658 "Cyclic";
BA_ "GenSigSendType" SG_ 658 LPG_04_Reserve "Cyclic";
BA_ "GenMsgCycleTime" BO_ 916 100;
BA_ "GenMsgSendType" BO_ 916 "Cyclic";
BA_ "GenSigSendType" SG_ 916 LRZ_Parameter "Cyclic";
BA_ "GenSigSendType" SG_ 916 LRZ_Grundeinst "Cyclic";
BA_ "GenSigSendType" SG_ 916 LRZ_Modus "Cyclic";
BA_ "GenSigSendType" SG_ 916 LRZ_Initlauf "Cyclic";
BA_ "GenSigSendType" SG_ 916 LRZ_Sichere_Pos "Cyclic";
BA_ "GenSigSendType" SG_ 916 LRZ_LampeAFS "Cyclic";
BA_ "GenSigSendType" SG_ 916 LRZ_Fehlerlampe "Cyclic";
BA_ "GenSigSendType" SG_ 916 LRZ_Fehler "Cyclic";
BA_ "GenSigSendType" SG_ 916 LRZ_Einfedg_vo "Cyclic";
BA_ "GenSigSendType" SG_ 916 LRZ_Einfedg_hi "Cyclic";
BA_ "GenSigSendType" SG_ 916 LRZ_Stellung "Cyclic";
BA_ "GenSigSendType" SG_ 916 LRZ_LeistDim "Cyclic";
BA_ "GenSigSendType" SG_ 916 LRZ_ELF_links "Cyclic";
BA_ "GenSigSendType" SG_ 916 LRZ_ELF_rechts "Cyclic";
BA_ "GenSigSendType" SG_ 916 LRZ_AFSLED_Blink "Cyclic";
BA_ "GenSigSendType" SG_ 916 LRZ_AFSFehlertext "Cyclic";
BA_ "GenSigSendType" SG_ 916 LRZ_Tourist_Fkt "Cyclic";
BA_ "GenSigSendType" SG_ 916 LRZ_Tourist_aktiv "Cyclic";
BA_ "GenSigSendType" SG_ 916 LRZ_AFS_Absch "Cyclic";
BA_ "GenSigSendType" SG_ 916 LRZ_AFS_deaktiv "Cyclic";
BA_ "GenSigSendType" SG_ 916 LRZ_Abbiegelicht_Dimm_Anf "Cyclic";
BA_ "GenSigSendType" SG_ 916 LRZ_Abbiegelicht_li_Anf "Cyclic";
BA_ "GenSigSendType" SG_ 916 LRZ_Abbiegelicht_re_Anf "Cyclic";
BA_ "GenSigSendType" SG_ 916 LRZ_Fernlicht_li_defekt "Cyclic";
BA_ "GenSigSendType" SG_ 916 LRZ_Fernlicht_re_defekt "Cyclic";
BA_ "GenSigSendType" SG_ 916 LRZ_Fernlicht_Status "OnChange";
BA_ "GenSigSendType" SG_ 916 LRZ_Verfuegbarkeit_GLW "Cyclic";
BA_ "GenSigSendType" SG_ 916 LRZ_Status_adaptive_LV "Cyclic";
BA_ "GenSigSendType" SG_ 916 GLW_Sensor_blockiert "Cyclic";
BA_ "GenSigSendType" SG_ 916 AFS_Abblendlicht_li_defekt "Cyclic";
BA_ "GenSigSendType" SG_ 916 AFS_Abblendlicht_re_defekt "Cyclic";
BA_ "GenSigSendType" SG_ 916 LRZ_Zaehler "Cyclic";
BA_ "GenMsgCycleTime" BO_ 1423 500;
BA_ "GenMsgSendType" BO_ 1423 "Cyclic";
BA_ "GenSigSendType" SG_ 1423 MO_ITM_Kuehlmittel_Temp "Cyclic";
BA_ "GenSigSendType" SG_ 1423 M12_E85_Sensor "Cyclic";
BA_ "GenSigSendType" SG_ 1423 M12_SCR_Anz_Motorstarts "Cyclic";
BA_ "GenSigSendType" SG_ 1423 M12_SCR_Reichweite "OnChange";
BA_ "GenSigSendType" SG_ 1423 SCR_Tankdeckel "Cyclic";
BA_ "GenSigSendType" SG_ 1423 M12_SCR_Warnstufe_1 "Cyclic";
BA_ "GenSigSendType" SG_ 1423 M12_SCR_Warnstufe_2 "Cyclic";
BA_ "GenSigSendType" SG_ 1423 M12_SCR_Text "Cyclic";
BA_ "GenSigSendType" SG_ 1423 M12_Akustik "Cyclic";
BA_ "GenSigSendType" SG_ 1423 M12_Luftfilter_Lampe "Cyclic";
BA_ "GenSigSendType" SG_ 1423 M12_Kraftstofffilter_Wasser "Cyclic";
BA_ "GenSigSendType" SG_ 1423 M12_SCR_Systemfehler "Cyclic";
BA_ "GenSigSendType" SG_ 1423 M12_SCR_Inducement "Cyclic";
BA_ "GenSigSendType" SG_ 1423 M12_CO2_Faktor "Cyclic";
BA_ "GenSigSendType" SG_ 1423 M12_MKB_MUX "Cyclic";
BA_ "GenSigSendType" SG_ 1423 MO_EDK_Luefter_defekt "Cyclic";
BA_ "GenSigSendType" SG_ 1423 M12_MKB_01 "NoSigSendType";
BA_ "GenSigSendType" SG_ 1423 M12_MKB_02 "NoSigSendType";
BA_ "GenSigSendType" SG_ 1423 M12_MKB_03 "NoSigSendType";
BA_ "GenSigSendType" SG_ 1423 M12_MKB_04 "NoSigSendType";
BA_ "GenMsgCycleTime" BO_ 1450 500;
BA_ "GenMsgSendType" BO_ 1450 "Cyclic";
BA_ "GenSigSendType" SG_ 1450 MO_NMAX_Schaltanzeige "OnChange";
BA_ "GenSigSendType" SG_ 1450 MO_Ethanol_BS_Texte "Cyclic";
BA_ "GenSigSendType" SG_ 1450 MO_Heizungspumpenansteuerung "Cyclic";
BA_ "GenSigSendType" SG_ 1450 MO_Nachlaufzeit_Heizungspumpe "Cyclic";
BA_ "GenSigSendType" SG_ 1450 MO_Absperrventil_oeffnen "Cyclic";
BA_ "GenSigSendType" SG_ 1450 MO_aktives_Getriebeheizen "Cyclic";
BA_ "GenSigSendType" SG_ 1450 MO_Getriebe_kuehlen "Cyclic";
BA_ "GenSigSendType" SG_ 1450 MO_Zustand_HWP "Cyclic";
BA_ "GenSigSendType" SG_ 1450 MO_BKV_Unterdruckwarnung "Cyclic";
BA_ "GenSigSendType" SG_ 1450 MO_Zylinderabschaltung "OnChange";
BA_ "GenSigSendType" SG_ 1450 MO_Heizstrom_SCR "Cyclic";
BA_ "GenSigSendType" SG_ 1450 MO_Heizstrom_EKAT "Cyclic";
BA_ "GenSigSendType" SG_ 1450 MO_Tankklappenstatus "Cyclic";
BA_ "GenSigSendType" SG_ 1450 MO_Tankklappensteuerung "Cyclic";
BA_ "GenSigSendType" SG_ 1450 MO_Zylabsch_Texte_02 "OnChange";
BA_ "GenSigSendType" SG_ 1450 MO_EFLEX_Lampe "Cyclic";
BA_ "GenSigSendType" SG_ 1450 MO_Testmode_AG "Cyclic";
BA_ "GenSigSendType" SG_ 1450 MO_Ext_E_Fahrt_aktiv "OnChange";
BA_ "GenSigSendType" SG_ 1450 MO_E85_WU_Lampe "OnChange";
BA_ "GenSigSendType" SG_ 1450 MO_E85_WU_Texte "Cyclic";
BA_ "GenSigSendType" SG_ 1450 MO_Zylabsch_Texte "Cyclic";
BA_ "GenSigSendType" SG_ 1450 MO_E85_BS_Texte "Cyclic";
BA_ "GenSigSendType" SG_ 1450 MO_StartStopp_Codiert "Cyclic";
BA_ "GenMsgCycleTime" BO_ 1407 50;
BA_ "GenMsgSendType" BO_ 1407 "Cyclic";
BA_ "GenSigSendType" SG_ 1407 MO_Charisma_FahrPr "Cyclic";
BA_ "GenSigSendType" SG_ 1407 MO_Charisma_Status "Cyclic";
BA_ "GenSigSendType" SG_ 1407 GE_Charisma_FahrPr "Cyclic";
BA_ "GenSigSendType" SG_ 1407 GE_Charisma_Status "Cyclic";
BA_ "GenSigSendType" SG_ 1407 EV_RekupStufe "Cyclic";
BA_ "GenSigSendType" SG_ 1407 MO_Bremslicht_Reku "Cyclic";
BA_ "GenSigSendType" SG_ 1407 MO_Verbrauch_EM "Cyclic";
BA_ "GenSigSendType" SG_ 1407 MO_UeberlVerb_EM "Cyclic";
BA_ "GenSigSendType" SG_ 1407 MO_Rekuperation_EM "Cyclic";
BA_ "GenSigSendType" SG_ 1407 MO_UeberlReku_EM "Cyclic";
BA_ "GenSigSendType" SG_ 1407 MO_Verbrauch_NA "Cyclic";
BA_ "GenSigSendType" SG_ 1407 MO_UeberlVerb_NA "Cyclic";
VAL_ 914 GK2_Sta_LSM 1 "veraltet" 0 "aktuell_empfangen" ;
VAL_ 914 GK2_Sta_Lichtsensor 1 "veraltet" 0 "aktuell_empfangen" ;
VAL_ 914 GK2_Sta_Licht1 1 "veraltet" 0 "aktuell_empfangen" ;
VAL_ 914 GK2_Sta_VSG 1 "veraltet" 0 "aktuell_empfangen" ;
VAL_ 914 GK2_Sta_Schluessel 1 "veraltet" 0 "aktuell_empfangen" ;
VAL_ 914 GK2_Sta_Profil 1 "veraltet" 0 "aktuell_empfangen" ;
VAL_ 914 GK2_Sta_Clima2 1 "veraltet" 0 "aktuell_empfangen" ;
VAL_ 914 GK2_Sta_BSG4 1 "veraltet" 0 "aktuell_empfangen" ;
VAL_ 914 GK2_Sta_Kessy_4 1 "veraltet" 0 "aktuell_empfangen" ;
VAL_ 914 BS4_Gleitende_Leuchtw_Anf 1 "Ein" 0 "Aus" ;
VAL_ 914 BS4_GLW_Fernlicht_Anf 1 "Ein" 0 "Aus" ;
VAL_ 914 GK2_Blk_L_Kontrolle 1 "Kontrolllampe_Blk_L_ein" ;
VAL_ 914 GK2_Blk_R_Kontrolle 1 "Kontrolllampe_Blk_R_ein" ;
VAL_ 914 GK2_LS_KomFehler 1 "Werte_veraltet" 0 "Werte_aktuell" ;
VAL_ 914 GK2_LS_def 1 "Lichtsensor_defekt" 0 "Lichtsensor_i_O" ;
VAL_ 914 GK2_VD_zu_ver 1 "Verdeck_geschl_verr" 0 "Verdeck_nicht_geschl_verr" ;
VAL_ 914 GK2_VD_entriegelt 1 "Verdeck_bzw_VDKD_auf" 0 "Verdeck_und_VDKD_zu" ;
VAL_ 914 GK2_VD_offen_ver 1 "Verdeck_offen_verr" 0 "Verdeck_nicht_offen_verr" ;
VAL_ 914 GK2_Verdeck_Anf 1 "Anforderung_Verdeckbetrieb" 0 "keine_Verdeckanforderung" ;
VAL_ 914 GK2_VDKD_auf 1 "VDKD_vollstaendig_auf" 0 "VDKD_nicht_vollst_auf" ;
VAL_ 914 GK2_Schluessel 0 "ungueltig" ;
VAL_ 914 GK2_Hardtop 1 "Hardtop_montiert" 0 "Hardtop_nicht_montiert" ;
VAL_ 914 GK2_AFL_Schalter 1 "AFL_Schalter_ein" 0 "aus" ;
VAL_ 914 GK2_Nebelschluss 1 "Kl83b_ein" 0 "aus" ;
VAL_ 914 GK2_EM_LIN_ungueltig 1 "Signale_ungueltig" 0 "Signale_gueltig" ;
VAL_ 914 GK2_Kl_StSt_Info 3 "Systemfehler" 2 "Motoranlauf_zwingend_notwendig_(Startanforderung)" 1 "Motoranlauf_nicht_zwingend_notwendig_(Stoppverbot,keine_Startanforderung)" 0 "Motorlauf_nicht_notwendig_(Stoppfreigabe)" ;
VAL_ 914 GK2_BSG_StSt_Info 3 "Systemfehler" 2 "Motoranlauf_zwingend_notwendig_(Startanforderung)" 1 "Motoranlauf_nicht_zwingend_notwendig_(Stoppverbot,keine_Startanforderung)" 0 "Motorlauf_nicht_notwendig_(Stoppfreigabe)" ;
VAL_ 914 GK2_BEM_P_Generator 255 "Fehler" ;
VAL_ 914 GK2_BEM_Abschaltstufen 3 "Stufe3" 2 "Stufe2" 1 "Stufe1" 0 "Stufe0" ;
VAL_ 914 GK2_Kessy_StSt_Info 3 "Systemfehler" 2 "Motoranlauf_zwingend_notwendig_(Startanforderung)" 1 "Motoranlauf_nicht_zwingend_notwendig_(Stoppverbot,keine_Startanforderung)" 0 "Motorlauf_nicht_notwendig_(Stoppfreigabe)" ;
VAL_ 914 GK2_BEM_StSt_Info 3 "Systemfehler" 2 "Motoranlauf_zwingend_notwendig_(Startanforderung)" 1 "Motoranlauf_nicht_zwingend_notwendig_(Stoppverbot,keine_Startanforderung)" 0 "Motorlauf_nicht_notwendig_(Stoppfreigabe)" ;
VAL_ 914 BEM_Segel_Info 3 "Segelveto" 2 "Mindestdrehzahl_2" 1 "Mindestdrehzahl_1" 0 "keine_Anforderung" ;
VAL_ 914 LS1_FAS_Taster 1 "Betaetigt" 0 "Unbetaetigt" ;
VAL_ 914 LS1_Fehler_FAS_Taster 1 "Fehler" 0 "kein_Fehler" ;
VAL_ 915 GK3_Sta_Kessy_4 1 "veraltet" 0 "aktuell_empfangen" ;
VAL_ 915 GK3_Sta_BCM_KY1 1 "veraltet" 0 "aktuell_empfangen" ;
VAL_ 915 GK3_Sta_Clima_3 1 "veraltet" 0 "aktuell_empfangen" ;
VAL_ 915 GK3_Sta_TSG_FT_3 1 "veraltet" 0 "aktuell_empfangen" ;
VAL_ 915 GK3_Sta_HD_1 1 "veraltet" 0 "aktuell_empfangen" ;
VAL_ 915 GK3_Sta_Memory_1 1 "veraltet" 0 "aktuell_empfangen" ;
VAL_ 915 GK3_Sta_BSG4 1 "veraltet" 0 "aktuell_empfangen" ;
VAL_ 915 GK3_Sta_MFG1 1 "veraltet" 0 "aktuell_empfangen" ;
VAL_ 915 GK3_KY4_Meldungen 4 "Kessy_defekt" 3 "Schluessel_im_Fahrzeug" 2 "Schluessel_im_Kofferraum" 1 "Schluessel_nicht_gefunden" 0 "keine_Meldung" ;
VAL_ 915 GK3_KY4_Gong_600 1 "aktiv" 0 "inaktiv" ;
VAL_ 915 MG1_ext_Last 1 "elektrische_Last_erkannt" 0 "keine_elektrische_Last_erkannt" ;
VAL_ 915 GK3_KY4_PassAL_Menue 1 "aktiv" 0 "inaktiv" ;
VAL_ 915 GK3_KY4_PassAL_akt 1 "aktiv" 0 "inaktiv" ;
VAL_ 915 GK3_BK1_IDGeb_1_Sta 2 "UHV_Antwort_n_auth" 1 "authentifiziert" 0 "keine_Antwort" ;
VAL_ 915 GK3_BK1_IDGeb_2_Sta 2 "UHV_Antwort_n_auth" 1 "authentifiziert" 0 "keine_Antwort" ;
VAL_ 915 ME1_EasyEntry_Menu 1 "verfuegbar" 0 "nicht_verfuegbar" ;
VAL_ 915 ME1_EasyEntry_aktiv 1 "aktiv" 0 "inaktiv" ;
VAL_ 915 GK3_BK1_IDGeb_3_Sta 2 "UHV_Antwort_n_auth" 1 "authentifiziert" 0 "keine_Antwort" ;
VAL_ 915 GK3_BK1_IDGeb_4_Sta 2 "UHV_Antwort_n_auth" 1 "authentifiziert" 0 "keine_Antwort" ;
VAL_ 915 GK3_BK1_Anlern_Info 1 "aktiv" 0 "inaktiv" ;
VAL_ 915 FT3_Auto_eKiSi_Menu 1 "aktiv" 0 "inaktiv" ;
VAL_ 915 FT3_Auto_eKiSi_Aktiv 1 "aktiv" 0 "inaktiv" ;
VAL_ 915 MKE_Texte 2 "Warnstufe_2" 1 "Warnstufe_1" 0 "keine_Anzeige" ;
VAL_ 915 HSA_unplausibel 1 "nicht_plausibel" 0 "plausibel" ;
VAL_ 915 FT_Kisi_Fehler 1 "Kindersicherung_nicht_mehr_gegeben" 0 "Kindersicherung_gegeben" ;
VAL_ 915 BCM_Tankwunsch 3 "reserviert" 2 "Betankung_erwuenscht" 1 "keine_Betankung_erwuenscht" 0 "Fehler_oder_keine_Drucktankfunktionalitaet" ;
VAL_ 915 BCM_Hybrid_StartStopp_Taste 1 "betaetigt" 0 "nicht_betaetigt" ;
VAL_ 915 KL_nachtr_Stopp_Anf 1 "angefordert" 0 "nicht_angefordert" ;
VAL_ 915 HD1_Endstellung_oben 1 "Endstellung" 0 "keine_Endstellung" ;
VAL_ 915 HD1_Endstellung_unten 1 "Endstellung" 0 "keine_Endstellung" ;
VAL_ 915 BCM_Bremslicht_defekt 1 "Bremslicht_defekt_erkannt" 0 "Bremslicht_i_O" ;
VAL_ 915 LIA_AFL_Schalter 1 "AFL_Schalter_ein" 0 "aus" ;
VAL_ 915 HD1_Position 200 "Endlage_oben_od_denormiert" 0 "Heckdeckel_geschlossen" ;
VAL_ 684 GS1_Fahrtrichtung 1 "Rueckwaerts" 0 "Vorwaerts" ;
VAL_ 684 GS1_QBit_Rad_kmh 1 "Ersatz_Init_oder_Fehlerwert" 0 "gueltiger_Wert" ;
VAL_ 684 GS1_Rad_kmh 65484 "Sensorfehler" 65450 "Unterspannung" 65433 "Ref_na" 65416 "Init" ;
VAL_ 1344 GE2_LFR_Adap 1 "fuer_Adaption_nicht_geeignet" 0 "fuer_Adaption_geeignet" ;
VAL_ 1344 GE2_Sta_SAS 1 "aktiv" 0 "inaktiv" ;
VAL_ 1344 GE2_LowSpeedMode_gueltig 1 "Drehzahlvorgabe_LSM_gueltig" 0 "Drehzahlvorgabe_LSM_ungueltig" ;
VAL_ 1344 GE2_Sta_ZwGas 1 "aktiv" 0 "inaktiv" ;
VAL_ 1344 GE2_LL_Solldz 255 "Fehler" ;
VAL_ 1344 GE2_Grad_begr 255 "keine_Begrenzung" ;
VAL_ 1344 GE2_Sync_Zeit 255 "Fehler" ;
VAL_ 1344 GE2_DZM_Daempf 1 "dynamisch" 0 "normal" ;
VAL_ 1344 GE2_Gong 1 "Ein" 0 "Aus" ;
VAL_ 1344 GE2_Segeln_aktiv 1 "Segeln" 0 "kein_Segeln" ;
VAL_ 1344 GE2_Shift_Lock 1 "Lampe_ein" 0 "Lampe_aus" ;
VAL_ 1344 GE2_Senderkennung 1 "MSG" 0 "GSG_oder_MSG_E_Fzg" ;
VAL_ 1344 GE2_WBA_Blinken 1 "Lampe_ein_Blinken" 0 "Lampe_aus_kein_Blinken" ;
VAL_ 1344 GE2_Variante 15 "aktuell_eingelegter_Gang" 14 "_8_Gang_Automat_Tiptronic" 13 "_7_Gang_Automat_Tiptronic" 12 "_6_Gang_Automat_Tiptronic" 11 "PRNDB_reserviert_fuer_EGolf" 10 "Sollgang_Tipschaltempf" 9 "_5_Gang_Automat_Tiptronic" 8 "_4_Gang_Automat_Tiptronic" 7 "Automat_PRNED" 6 "Automat_PRNDS" 5 "Vorhalt_fuer_9_Gang_Automat_Tiptronic" 4 "Selespeed" 3 "ASG_Getriebe" 2 "_4_Gang_Automat" 1 "Automat_PRNDL" 0 "_5_Gang_automat" ;
VAL_ 1344 GE2_5Gang 8 "_2" 7 "_3" 6 "_4" 5 "D" 4 "N" 3 "R" 2 "P" 1 "Inversdarstellung" 0 "Normaldarstellung" ;
VAL_ 1344 GE2_PRNDL 6 "L" 5 "D" 4 "N" 3 "R" 2 "P" 1 "Inversdarstellung" 0 "Normaldarstellung" ;
VAL_ 1344 GE2_4Gang 8 "_1" 7 "_2" 6 "_3" 5 "D" 4 "N" 3 "R" 2 "P" 1 "Inversdarstellung" 0 "Normaldarstellung" ;
VAL_ 1344 GE2_ASG 12 "E1" 11 "E2" 10 "E3" 9 "E4" 8 "E5" 7 "E6" 6 "E7" 5 "D_E" 4 "N" 3 "R" 2 "S" 1 "Inversdarstellung" 0 "Normaldarstellung" ;
VAL_ 1344 GE2_Selespeed 14 "MS_Minus" 13 "MS_Plus" 12 "M_Minus" 11 "M_Plus" 10 "Vorhalt_W" 9 "Vorhalt_S" 8 "keine_Anzeige" 7 "A_W" 6 "A_S" 5 "A" 4 "M_W" 3 "M_S" 2 "M" 1 "Inversdarstellung" 0 "Normaldarstellung" ;
VAL_ 1344 GE2_PRNDS 6 "S" 5 "D" 4 "N" 3 "R" 2 "P" 1 "Inversdarstellung" 0 "Normaldarstellung" ;
VAL_ 1344 GE2_PRNED 6 "D" 5 "E" 4 "N" 3 "R" 2 "P" 1 "Inversdarstellung" 0 "Normaldarstellung" ;
VAL_ 1344 GE2_Tip4Gang 5 "_4" 4 "_3" 3 "_2" 2 "_1" 1 "Inversdarstellung" 0 "Normaldarstellung" ;
VAL_ 1344 GE2_Tip5Gang 6 "_5" 5 "_4" 4 "_3" 3 "_2" 2 "_1" 1 "Inversdarstellung" 0 "Normaldarstellung" ;
VAL_ 1344 GE2_Sollgang 10 "Gang_9" 9 "Gang_8" 8 "Gang_7" 7 "Gang_6" 6 "Gang_5" 5 "Gang_4" 4 "Gang_3" 3 "Gang_2" 2 "Gang_1" 0 "keine_Empfehlung" ;
VAL_ 1344 GE2_PRNDB 6 "B" 5 "D" 4 "N" 3 "R" 2 "P" 1 "Inversdarstellung" 0 "Normaldarstellung" ;
VAL_ 1344 GE2_Tip6Gang 7 "_6" 6 "_5" 5 "_4" 4 "_3" 3 "_2" 2 "_1" 1 "Inversdarstellung" 0 "Normaldarstellung" ;
VAL_ 1344 GE2_Tip7Gang 8 "_7" 7 "_6" 6 "_5" 5 "_4" 4 "_3" 3 "_2" 2 "_1" 1 "Inversdarstellung" 0 "Normaldarstellung" ;
VAL_ 1344 GE2_Tip8Gang 9 "_8" 8 "_7" 7 "_6" 6 "_5" 5 "_4" 4 "_3" 3 "_2" 2 "_1" 1 "Inversdarstellung" 0 "Normaldarstellung" ;
VAL_ 1344 GE2_akt_Gang 14 "P_ist_eingelegt" 13 "N_ist_eingelegt" 12 "R_ist_eingelegt" 10 "_9_ist_eingelegt" 9 "_8_ist_eingelegt" 8 "_7_ist_eingelegt" 7 "_6_ist_eingelegt" 6 "_5_ist_eingelegt" 5 "_4_ist_eingelegt" 4 "_3_ist_eingelegt" 3 "_2_ist_eingelegt" 2 "_1_ist_eingelegt" 0 "kein_Gang_eingelegt" ;
VAL_ 1090 GM3_MomEingr 1 "MomEingAnf_moeglich" 0 "keine_Freigabe" ;
VAL_ 1090 GM3_MoSoMom 1023 "Fehler" 1022 "kein_Eingriff" ;
VAL_ 1090 GM3_StaSoMom 3 "Fehler" 2 "erh_Getriebeeingriff" 1 "reduz_Getriebeeingriff" 0 "keine_anforderung" ;
VAL_ 1090 GM3_MomID 15 "Fehler" 0 "reserviert" ;
VAL_ 1090 GM3_Moment 1023 "Neutralwert" ;
VAL_ 1090 GM3_QB_LangEingr 1 "Ersatz_Init_oder_Fehlerwert" 0 "gueltiger_Wert" ;
VAL_ 1090 GM3_LangEingr 1023 "Fehler" 1022 "kein_Eingriff" ;
VAL_ 1352 GE4_Shiftlock 1 "Waehlhebel_frei" 0 "Waehlhebel_verriegelt" ;
VAL_ 1352 GE4_AuslModus 1 "USA" 0 "RDW" ;
VAL_ 1352 GE4_Test 1 "Test_aktiv" 0 "kein_Test" ;
VAL_ 1352 GE4_Tasterausleuchtung 1 "Lampe_ein" 0 "Lampe_aus" ;
VAL_ 1352 GE4_Ausleuchtung 15 "Fehler" 14 "Tipp_Gasse" 13 "Position_L" 12 "Position_S_Sport" 11 "Position_Tipp_minus" 10 "Position_Tipp_plus" 8 "Position_P_Stop" 7 "Position_R" 6 "Position_N" 5 "Position_D" 4 "Position_4" 3 "Position_3" 2 "Position_2" 1 "Position_1" 0 "Keine_Lampe_angesteuert" ;
VAL_ 1346 GE5_Test 1 "Test_freigegeben" 0 "kein_Test" ;
VAL_ 1346 GE5_Abschalten 1 "Aus" 0 "Ein" ;
VAL_ 1346 GE5_Sta_Fahrstufe 1 "Fahrstufe_ungueltig" 0 "Fahrstufe_gueltig" ;
VAL_ 1346 GE5_Ausl_Sport 1 "aktiv" 0 "inaktiv" ;
VAL_ 1346 GE5_Ausl_Winter 1 "aktiv" 0 "inaktiv" ;
VAL_ 1346 GE5_Ausleuchtung 3 "Automatik" 2 "Manuell" 1 "N" 0 "R" ;
VAL_ 1346 GE5_keine_Ausleuchtung 1 "nur_Grundausleuchtung" 0 "Ausleuchtung_wie_GE5_Ausleuchtung" ;
VAL_ 1100 GE6_TurbDZ 16383 "Fehler" 16382 "Init" ;
VAL_ 1100 GE6_QmaxBeschl 1 "Ersatz_Init_oder_Fehlerwert" 0 "gueltiger_Wert" ;
VAL_ 1100 GE6_QB_OelTemp 1 "Ersatz_Init_oder_Fehlerwert" 0 "gueltiger_Wert" ;
VAL_ 1100 GE6_OelTemp 255 "Fehler" ;
VAL_ 1100 GE6_maxBeschl 255 "Fehler" ;
VAL_ 1100 GE6_Gangwechsel 1 "Gangwechsel" 0 "kein_Gangwechsel" ;
VAL_ 1100 GE6_Zielgang_err 1 "Zielgang_erreicht" 0 "Zielgang_nicht_erreicht" ;
VAL_ 1100 GE_Betaetigung_Hold 1 "Hold_aktivieren" 0 "kein_Hold" ;
VAL_ 1100 GE_Heizwunsch 3 "Notfall_(maximaler_Kuehlbedarf)" 2 "Kuehlbedarf" 1 "kein_Waermebedarf" 0 "maximaler_Waermebedarf" ;
VAL_ 1100 GE1_StSt_Info 3 "Systemfehler" 2 "Motoranlauf_zwingend_notwendig_(Startanforderung)" 1 "Motoranlauf_nicht_zwingend_notwendig_(Stoppverbot,keine_Startanforderung)" 0 "Motorlauf_nicht_notwendig_(Stoppfreigabe)" ;
VAL_ 1100 GE6_Verlustmom 255 "Fehler" ;
VAL_ 1348 GE7_Text_01 1 "Text_ein" 0 "Text_aus" ;
VAL_ 1348 GE7_Text_02 1 "Text_ein" 0 "Text_aus" ;
VAL_ 1348 GE7_Text_03 1 "Text_ein" 0 "Text_aus" ;
VAL_ 1348 GE7_Gong 1 "Gong_aktiv" 0 "kein_Gong" ;
VAL_ 1348 GE7_Text_04 1 "Text_ein" 0 "Text_aus" ;
VAL_ 1348 GE7_Text_05 1 "Text_ein" 0 "Text_aus" ;
VAL_ 1348 GE7_Waehlh_ausgef 1 "Waehlhebel_ausgef" 0 "Waehlhebel_OK" ;
VAL_ 1348 GE7_Text_07 1 "Text_ein" 0 "Text_aus" ;
VAL_ 1348 GE_Segeln_Menueanf 1 "Segeln_vorhanden" 0 "Segeln_nicht_vorhanden" ;
VAL_ 1348 GE_Segeln_Status 1 "Personalisierung_Segeln_ein" 0 "Personalisierung_Segeln_aus" ;
VAL_ 1348 GE7_Akustik 1 "Akustik_aktiv" 0 "kein_Akustik" ;
VAL_ 1348 GE7_Wegrollwarnung 1 "Text_ein" 0 "Text_aus" ;
VAL_ 1348 GE7_Temp_Warnstufe_I 1 "Text_ein" 0 "Text_aus" ;
VAL_ 1348 GE7_Text_08 1 "Text_ein" 0 "Text_aus" ;
VAL_ 1348 GE7_Text_09 1 "Text_ein" 0 "Text_aus" ;
VAL_ 1348 GE7_Text_10 1 "Text_ein" 0 "Text_aus" ;
VAL_ 1348 GE7_Text_11 1 "Text_ein" 0 "Text_aus" ;
VAL_ 1348 GE7_Text_12 1 "Text_ein" 0 "Text_aus" ;
VAL_ 1348 GE7_Feh_3Warn 1 "Text_ein" 0 "Text_aus" ;
VAL_ 1348 GE7_Stop_Warn 1 "Text_ein" 0 "Text_aus" ;
VAL_ 1348 GE7_Feh_4Warn 1 "Text_ein" 0 "Text_aus" ;
VAL_ 1348 GE_Fahrprogramm 6 "Sport_Plus" 5 "Efficiency" 4 "Offroad" 3 "Sport" 2 "Normal" 1 "nicht_belegt" 0 "Init" ;
VAL_ 1348 GE_Anf_Zylinderabsch 3 "VMB_Empfehlung" 1 "Umschaltung_verboten" 0 "Umschaltung_erlaubt" ;
VAL_ 1348 GE_Sumpftemperatur 255 "Fehler" ;
VAL_ 1104 GE8_Hydr_Pumpe 1 "Hydraulikpumpe_angest" 0 "Hydraulikpumpe_aus" ;
VAL_ 1104 GE8_Motor_aus 1 "Motor_aus" 0 "Motor_startbereit" ;
VAL_ 1104 GE8_Anfahrfkt 1 "Anfahrfunktion_aktiv" 0 "Anfahrfunktion_nicht_aktiv" ;
VAL_ 1108 GE_Sollstellung_Parksperre 2 "Parksperre_auslegen" 1 "Parksperre_einlegen" 0 "Init" ;
VAL_ 1108 GE_PHM_Diag_Status 1 "PHM_Diag_nicht_freigegeben" 0 "PHM_Diag_freigegeben" ;
VAL_ 1108 GE_Soll_Strom_KUV2 255 "Fehler" 0 "Init" ;
VAL_ 1108 GE_Soll_Hauptdruck_berechnet 255 "Fehler" 0 "Init" ;
VAL_ 1108 GE_Sumpftemperatur_2 255 "Fehler" 0 "Init" ;
VAL_ 1108 GE_TVH_Wasserzusatzpumpe 31 "Fehler" 0 "Init" ;
VAL_ 1108 GE_TVH_Oelpumpe 31 "Fehler" 0 "Init" ;
VAL_ 1108 GE_Freigabe_Spuehlfkt 1 "Freigabe" 0 "keine_Freigabe" ;
VAL_ 1106 GH1_FreigabeK0 1 "K0_schliessen" 0 "K0_oeffnen" ;
VAL_ 1106 GH1_FreigabeVMStop 1 "VM_Stopp_erlaubt" 0 "VM_Stopp_nicht_erlaubt" ;
VAL_ 1106 GH1_FehlerstatusGSG 3 "beide_Fehler" 2 "Anforderung_n_gleich_0" 1 "kein_Hydraulikdruck" 0 "kein_Fehler" ;
VAL_ 1106 GH1_nK0 255 "Fehler" ;
VAL_ 1106 GH1_VZMomEingriff 1 "negatives_Vorzeichen" 0 "positives_Vorzeichen" ;
VAL_ 1106 GH1_Wiederstart 1 "Wiederstart_aktiv" 0 "kein_Wiederstart_aktiv" ;
VAL_ 1106 GH1_VM_akt_halten 1 "VM_aktiv_halten_starten" 0 "keine_Empfehlung" ;
VAL_ 1106 GH1_Sportfaktor 0 "nicht_sportlich" ;
VAL_ 1106 GH1_Freig_LL_Reg 1 "LL_Reg_freigegeben" 0 "keine_DZ_Reg_erlaubt" ;
VAL_ 1106 GH1_VKM_StAnf 1 "Startanf" 0 "keine_Startanf" ;
VAL_ 1106 GH1_VKM_StKontr 1 "aktiv" 0 "nicht_aktiv" ;
VAL_ 1106 GH1_AnzeigeDZ 4095 "Fehler" ;
VAL_ 1106 GH1_Filt_MomAufbau 7 "multiplikative_Konstante_fuer_MSG" 6 "multiplikative_Konstante_fuer_MSG" 5 "multiplikative_Konstante_fuer_MSG" 4 "multiplikative_Konstante_fuer_MSG" 3 "multiplikative_Konstante_fuer_MSG" 2 "multiplikative_Konstante_fuer_MSG" 1 "multiplikative_Konstante_fuer_MSG" 0 "keine_Beeinflussung_der_Filterung_durch_Getriebe" ;
VAL_ 1106 GE_Freigabe_Verfallsinfo_WFS 1 "Ein" 0 "Aus" ;
VAL_ 1110 GZ_OBD_Status 1 "MIL_ein" 0 "MIL_aus" ;
VAL_ 1110 GZ_PHM_Diagnose 1 "aktiv" 0 "inaktiv" ;
VAL_ 1110 GZ_Position_Parksperre 3 "Fehler" 2 "Parksperre_ausgelegt" 1 "Parksperre_eingelegt" 0 "Zwischenposition" ;
VAL_ 1110 GZ_Kuehloeltemperatur 255 "Fehler" 0 "Init" ;
VAL_ 1110 GZ_IST_Strom_KUV2 255 "Fehler" 0 "Init" ;
VAL_ 1110 GZ_KuehlOel2_Status 2 "Unterbrechung" 1 "Kurzschluss" 0 "kein_Fehler" ;
VAL_ 1110 GZ_PAV_Status 2 "Unterbrechung" 1 "Kurzschluss" 0 "kein_Fehler" ;
VAL_ 1110 GZ_PEV_Status 2 "Unterbrechung" 1 "Kurzschluss" 0 "kein_Fehler" ;
VAL_ 1110 GZ_PHM_Status 3 "PHM_bestromt_u_Fehler" 2 "PHM_unbestromt_u_Fehler" 1 "PHM_bestromt" 0 "PHM_unbestromt" ;
VAL_ 1110 GZ_Schaltwippen_TipDown_02 3 "Fehler" 2 "betaetigt" 1 "nicht betaetigt" 0 "Init" ;
VAL_ 1110 GZ_Schaltwippen_TipUp_02 3 "Fehler" 2 "betaetigt" 1 "nicht betaetigt" 0 "Init" ;
VAL_ 1110 ZSG_Initialisierung 1 "Initphase" 0 "keine Initphase" ;
VAL_ 1110 GZ_Warnung 5 "Wegrollgefahr_P_nicht_moeglich__Bitte_Parkbremse_betaetigen" 4 "Getriebefehler_Weiterfahren_in_D_moeglich__P_bei_Motor_aus" 3 "Weiterfahrt_eingeschraenkt_moeglich_kein_R_Gang" 2 "Weiterfahrt_eingeschraenkt_moeglich" 1 "Weiterfahrt_moeglich" 0 "keine_Anzeige" ;
VAL_ 1110 GZ_Oelpumpe_Status 2 "Trockenlauf" 1 "Pumpe_steht" 0 "kein_Fehler" ;
VAL_ 1110 GZ_Schaltwippen_TipDown 1 "betaetigt" 0 "unbetaetigt" ;
VAL_ 1110 GZ_Schaltwippen_TipUp 1 "betaetigt" 0 "unbetaetigt" ;
VAL_ 1110 GZ_KD_Fehler 1 "Fehlerspeichereintrag" 0 "kein_Fehlerspeichereintrag" ;
VAL_ 906 GRA_Hauptschalt 1 "EIN_Nicht_Gerastet_AUS" 0 "Gerastet_AUS" ;
VAL_ 906 GRA_Abbrechen 1 "Tipschalter_betaetigt" 0 "Tipschalter_nicht_betaetigt" ;
VAL_ 906 GRA_Down_kurz 1 "Tipschalter_betaetigt" 0 "Tipschalter_nicht_betaetigt" ;
VAL_ 906 GRA_Up_kurz 1 "Tipschalter_betaetigt" 0 "Tipschalter_nicht_betaetigt" ;
VAL_ 906 GRA_Down_lang 1 "Tipschalter_lang_betaetigt" 0 "Tipschalter_nicht_betaetigt" ;
VAL_ 906 GRA_Up_lang 1 "Tipschalter_lang_betaetigt" 0 "Tipschalter_nicht_betaetigt" ;
VAL_ 906 GRA_Fehler_Bed 1 "Fehler_Bedienhebel" 0 "iO" ;
VAL_ 906 GRA_Kodierinfo 1 "ACC" 0 "GRA" ;
VAL_ 906 GRA_Neu_Setzen 1 "Tipschalter_betaetigt" 0 "Tipschalter_nicht_betaetigt" ;
VAL_ 906 GRA_Recall 1 "Tipschalter_betaetigt" 0 "Tipschalter_nicht_betaetigt" ;
VAL_ 906 GRA_Sender 3 "Lenksaeulenmodul_4_Pos" 2 "MFL_Gen_2" 1 "Lenksaeulenmodul_6_Pos" 0 "BSG_oder_BCM" ;
VAL_ 906 GRA_Tip_Down 1 "Tip_Down" 0 "Tipschalter_nicht_betaetigt" ;
VAL_ 906 GRA_Tip_Up 1 "Tip_Up" 0 "Tipschalter_nicht_betaetigt" ;
VAL_ 906 GRA_Zeitluecke 3 "DIST_Toggle" 2 "DIST_plus_1" 1 "DIST_minus_1" 0 "Taste_nicht_betaetigt" ;
VAL_ 906 GRA_Limiter 1 "betaetigt" 0 "nicht_betaetigt" ;
VAL_ 906 GRA_Typ_Hauptschalt 1 "getastet" 0 "gerastet" ;
VAL_ 906 GRA_LIM_Taste_verfuegbar 1 "Limiter_Taste_vorhanden" 0 "Limiter_Taste_nicht_vorhanden" ;
VAL_ 906 GRA_Fehler_Tip 1 "Fehler_erkannt" 0 "iO" ;
VAL_ 1529 GM_KD_Fehler 1 "Fehlerspeichereintrag" 0 "kein_Fehlerspeichereintrag" ;
VAL_ 1164 HS1_Drehz_Grenze 4 "Obere_Komfortgrenze" 3 "Obere_Abschaltgrenze" 2 "untere_Komfortgrenze" 1 "untere_Abschaltgrenze" 0 "kein_Grenzwert" ;
VAL_ 1164 HS1_Gang 7 "nicht_bekannt" 3 "Rueckwaertsgang" 2 "Hoechster_Gang" 1 "Gang_1" 0 "Triebstrang_offen" ;
VAL_ 1164 MO_NGS_Position 1 "Neutralposition_erkannt" 0 "Neutralposition_nicht_erkannt" ;
VAL_ 1164 MO_NGS_Status 3 "Fehler" 2 "plausibilisiert" 1 "nicht_plausibilisiert" 0 "nicht_verbaut" ;
VAL_ 210 HC1_Sta_HCA 5 "ext_MomEingr_angef" 3 "bereit" 2 "Kom_gestoert" 1 "Anf_nicht_ausf" 0 "deaktiv" ;
VAL_ 210 HC1_LM_Offset_Sign 1 "negatives_Vorzeichen" 0 "positives_Vorzeichen" ;
VAL_ 1512 KL_HV_ein 1 "Ein" 0 "Aus" ;
VAL_ 1512 KL_Innengeblaese 1 "Ein" 0 "Aus" ;
VAL_ 1512 KL_PTC_Pumpe_Soll 15 "nicht_definiert" 14 "nicht_definiert" 13 "nicht_definiert" 12 "nicht_definiert" 11 "nicht_definiert" ;
VAL_ 1512 KL_Beschlagsgefahr 1 "Beschlagsgefahr" 0 "kein_Beschlagsgefahr" ;
VAL_ 1512 KL_Standklima_RemoteModus 7 "reserviert" 6 "reserviert" 5 "reserviert" 4 "reserviert" 3 "Heizen" 2 "Kuehlen" 1 "Lueften" 0 "Init__nicht_aktiv" ;
VAL_ 1512 KL_Wake_Up_ACAN 1 "Wecken_ACAN" 0 "kein_Wecken_ACAN" ;
VAL_ 1512 KL_HV_Anf 1 "HV_Bordnetz_benoetigt" 0 "kein_HV_Bordnetz_benoetigt" ;
VAL_ 1512 KL_Ventil_Batterie_Anf 1 "Ventil_schliessen" 0 "Ventil_oeffnen" ;
VAL_ 1512 KL_Ventil_vor_Motor_Anf 1 "Ventil_schliessen" 0 "Ventil_oeffnen" ;
VAL_ 1512 EKK_Status 1 "aktiv" 0 "inaktiv" ;
VAL_ 1512 KL_Standklima_Status_02 7 "Fehler" 6 "Init" 5 "Aussenhuelle_offen" 4 "reserviert" 3 "reserviert" 2 "eingeschraenkt_aktiv" 1 "aktiv" 0 "nicht_aktiv" ;
VAL_ 1512 PTC_Pumpe_Ist 15 "nicht_verbaut" 14 "nicht_definiert" 13 "nicht_definiert" 12 "nicht_definiert" 11 "nicht_definiert" ;
VAL_ 1512 PTC_Pumpe_Status 3 "reserviert" 2 "foerdert" 1 "foerdert_nicht" 0 "nicht_schaltbar" ;
VAL_ 1512 KL_Charisma_FahrPr 7 "Programm_7" 6 "Programm_6" 5 "Programm_5" 4 "Programm_4" 3 "Programm_3" 2 "Programm_2" 1 "Programm_1" 0 "nicht_belegt" ;
VAL_ 1512 KL_Charisma_Status 3 "asynchron_durch_Fahrerwunsch" 2 "nicht_verfuegbar" 1 "verfuegbar" 0 "Init" ;
VAL_ 1512 EKK_Status_Vorstrg 1 "Ein" 0 "Aus" ;
VAL_ 1512 KL_Vorwarn_HVHeizer_Leistung 15 "Fehler" 15 "Fehler" 14 "7000W" 13 "6500W" 12 "6000W" 11 "5500W" 10 "5000W" 9 "4500W" 8 "4000W" 7 "3500W" 6 "3000W" 5 "2500W" 4 "2000W" 3 "1500W" 2 "1000W" 1 "500W" 0 "Init_Aus" ;
VAL_ 1527 KE1_Comp_enable 1 "Enable" 0 "Disable" ;
VAL_ 800 KO1_SleepInd 1 "Sleep_bereit" 0 "CAN_wird_benoetigt" ;
VAL_ 800 KO1_Sta_Tank 1 "Tankfuellst_n_iO" 0 "Tankfuellst_iO" ;
VAL_ 800 KO1_Oeldruck 1 "groesser_Schwellwert" 0 "kleiner_Schwellwert" ;
VAL_ 800 KO1_Sta_Oeldr 1 "Warnung" 0 "iO" ;
VAL_ 800 KO1_Kuehlmittel 1 "Mangel" 0 "iO" ;
VAL_ 800 KO1_Wakeup_Komfort 1 "Wake_Up_Komfort" 0 "keine_Anforderung" ;
VAL_ 800 KO1_Warn_Tank 1 "Lampe_ein" 0 "Lampe_aus" ;
VAL_ 800 KO1_Vorgluehen 1 "Lampe_ein" 0 "Lampe_aus" ;
VAL_ 800 KO1_Bremsinfo 1 "Bremsfluessigkeitswarnung" 0 "iO" ;
VAL_ 800 KO1_Handbremse 1 "angezogen" 0 "nicht_angezogen" ;
VAL_ 800 KO1_La_Ladekon 1 "Lampe_ein" 0 "Lampe_aus" ;
VAL_ 800 KO1_Stellglieder 1 "ja" 0 "nein" ;
VAL_ 800 KO1_Zeitluecke 7 "Zeitluecke_7" 6 "Zeitluecke_6" 5 "Zeitluecke_5" 4 "Zeitluecke_4" 3 "Zeitluecke_3" 2 "Zeitluecke_2" 1 "Zeitluecke_1" 0 "keine_Anzeige" ;
VAL_ 800 KO1_Tankstop 1 "Tankstop_erkannt" ;
VAL_ 800 KO1_Tankinhalt 127 "Fehler" ;
VAL_ 800 KO1_OBD_Tank 1 "Tankwarnung" 0 "iO" ;
VAL_ 800 KO1_Quelle_kmh 1 "ABS_Signale" 0 "Tachogeber" ;
VAL_ 800 KO1_ACC_Inkons 1 "Fehler" 0 "iO" ;
VAL_ 800 KO1_ACC_AnzFhl 1 "ACC_Anzeige_defekt" 0 "kein_Fehler" ;
VAL_ 800 KO1_angez_kmh 1023 "Fehler" 1022 "Fehler" 1021 "Fehler" 1020 "Fehler" ;
VAL_ 800 KO1_kmh_mph 1 "miles_hour" 0 "km_h" ;
VAL_ 800 KO1_ABS_Lampe 1 "Lampe_ein" 0 "Lampe_aus" ;
VAL_ 800 KO1_ASRESP_Lampe 1 "Lampe_ein" 0 "Lampe_aus" ;
VAL_ 800 KO1_Brems_Lampe 1 "Lampe_ein" 0 "Lampe_aus" ;
VAL_ 800 KO1_Airbag_Lampe 1 "Lampe_ein" 0 "Lampe_aus" ;
VAL_ 800 KO1_Lenkh_Lampe 1 "Lampe_ein" 0 "Lampe_aus" ;
VAL_ 800 KO1_LDW_AnzFeh 1 "Fehler" 0 "i_O" ;
VAL_ 800 KO1_SILA_gueltig 1 "gueltig" 0 "ungueltig" ;
VAL_ 1470 LDW_Lernmodus_seitenabhaengig 15 "links_Warnung__rechts_Warnung" 14 "links_Warnung__rechts_an" 13 "links_Warnung__rechts_outlined" 12 "nicht_definiert" 11 "links_an__rechts_Warnung" 10 "links_an__rechts_an" 9 "links_an__rechts_outlined" 8 "nicht_definiert" 7 "links_outlined__rechts_Warnung" 6 "links_outlined__rechts_an" 5 "links_outlined__rechts_outlined" 4 "nicht_definiert" 3 "nicht_definiert" 2 "nicht_definiert" 1 "nicht_definiert" 0 "links_aus__rechts_aus" ;
VAL_ 1470 LDW_Lernmodus 4 "LDW_Warn_li" 3 "LDW_warn_re" 2 "LDW_an_aktiv" 1 "LDW_an_inakt" 0 "LDW_aus" ;
VAL_ 1470 LDW_Textbits 5 "Lane assist keine Funktion bei Anhaengerbetrieb (Vorhalt)" 4 "Lane assist Fahreruebernahme" 3 "Lane assist zur Zeit keine Sensorsicht" 2 "Lane assist Systemfehler" 1 "Lane assist zur Zeit nicht verfuegbar" 0 "kein_Text" ;
VAL_ 1470 LDW_Gong 2 "Gong2" 1 "Gong1" 0 "kein_akust_Signal" ;
VAL_ 1470 LDW_Kameratyp 1 "Hella_MFK" 0 "Conti_HCA" ;
VAL_ 1470 LDW_Lampe_gelb 1 "Lampe_ein" 0 "Lampe_aus" ;
VAL_ 1470 LDW_Lampe_gruen 1 "Lampe_ein" 0 "Lampe_aus" ;
VAL_ 1470 LDW_SW_Warnung_links 1 "Spurwechsel_Warnung_links_aktiv" 0 "Spurwechsel_Warnung_links_nicht_aktiv" ;
VAL_ 1470 LDW_SW_Warnung_rechts 1 "Spurwechsel_Warnung_rechts_aktiv" 0 "Spurwechsel_Warnung_rechts_nicht_aktiv" ;
VAL_ 1470 LDW_KD_Fehler 1 "Fehlerspeichereintrag" 0 "kein_Fehlerspeichereintrag" ;
VAL_ 1470 LDW_Seite_DLCTLC 1 "rechts" 0 "links" ;
VAL_ 1470 LDW_Frueh_Spaet 3 "Fehler" 2 "spaet_spaet_aktiv" 1 "frueh_spaet_aktiv" 0 "frueh_frueh_aktiv" ;
VAL_ 976 LH1_Fehler_LI 1 "n_iO" 0 "iO" ;
VAL_ 976 LH1_Sicherheitslamp 1 "Lampe_ein" 0 "Lampe_aus" ;
VAL_ 976 LH1_Fehlerlampe 1 "Lampe_ein" 0 "Lampe_aus" ;
VAL_ 976 LH1_Textbits 4 "Text_3" 2 "Text_2" 1 "Text_1" 0 "kein_Text" ;
VAL_ 976 LH1_Akustiksign 1 "Akustiksignal_aktiv" 0 "Akustiksignal_nicht_aktiv" ;
VAL_ 976 LH1_SleepInd 1 "Sleep_bereit" 0 "CAN_wird_benoetigt" ;
VAL_ 976 LH1_Fehlereintr 1 "Fehlerspeichereintrag" 0 "kein_Fehlerspeichereintrag" ;
VAL_ 976 LH1_EPS_Diagmode 1 "aktiv" 0 "nicht_aktiv" ;
VAL_ 976 LH1_gue_ECU_Temp 1 "gueltig" 0 "ungueltig" ;
VAL_ 976 LH1_Kuehlung 1 "Anf_Kuehlung" 0 "keine_Anforderung" ;
VAL_ 976 LH1_Mode_Hybrid 1 "Mode_Hybrid_aktiv" 0 "Mode_Hybrid_nicht_aktiv" ;
VAL_ 976 LH1_NL_Untersp 1 "Unterspannung" ;
VAL_ 976 LH1_NL_Uebersp 1 "Ueberspannung" ;
VAL_ 976 LH1_NL_Uebertemp 1 "Uebertemperatur" ;
VAL_ 976 LH1_NL_Sensor 1 "Sensorik_Fehler" ;
VAL_ 976 LH1_NL_CAN_SS 1 "CAN_Schnittstelle_Fehler" ;
VAL_ 976 LH1_NL_ECU 1 "ECU_intern_defekt" ;
VAL_ 976 LH1_NL_Motor 1 "Servomotordefekt" ;
VAL_ 976 LH1_NL_LeistDichte 1 "Leistungsdichtebegrenzung" ;
VAL_ 916 LRZ_Parameter 1 "Parametrisierung_erfolgt" 0 "Parametrisierung_nicht_erfolgt" ;
VAL_ 916 LRZ_Grundeinst 1 "Grundeinstellung_erfolgt" 0 "Grundeinstellung_nicht_erfolgt" ;
VAL_ 916 LRZ_Modus 1 "LWR_dynamisch" 0 "LWR_statisch" ;
VAL_ 916 LRZ_Initlauf 1 "Initialisierungslauf_erfolgt" 0 "Initlauf_nicht_erfolgt" ;
VAL_ 916 LRZ_Sichere_Pos 1 "Sicherheitsposition_ein" 0 "Sicherheitsposition_aus" ;
VAL_ 916 LRZ_LampeAFS 1 "Lampe_ein" 0 "Lampe_aus" ;
VAL_ 916 LRZ_Fehlerlampe 1 "Lampe_ein" 0 "Lampe_aus" ;
VAL_ 916 LRZ_Fehler 1 "Fehlerspeichereintrag" 0 "kein_Fehlerspeichereintrag" ;
VAL_ 916 LRZ_Einfedg_vo 255 "Fehler" 254 "nicht_initialisiert" 127 "entspr_NN" ;
VAL_ 916 LRZ_Einfedg_hi 255 "Fehler" 254 "nicht_initialisiert" 127 "entspr_NN" ;
VAL_ 916 LRZ_Stellung 255 "Fehler" 254 "Init" ;
VAL_ 916 LRZ_LeistDim 255 "Fehler" 254 "Wert_unbekannt" ;
VAL_ 916 LRZ_ELF_links 1 "Ersatzlichtfunktion" 0 "keine_Ersatzlichtfunktion" ;
VAL_ 916 LRZ_ELF_rechts 1 "Ersatzlichtfunktion" 0 "keine_Ersatzlichtfunktion" ;
VAL_ 916 LRZ_AFSLED_Blink 1 "ja" 0 "nein" ;
VAL_ 916 LRZ_AFSFehlertext 1 "Text_AFS_ohne_Funktion" 0 "kein_Text" ;
VAL_ 916 LRZ_Tourist_Fkt 1 "Tourist_Fkt_unterstuetzt" 0 "Tourist_Fkt_n_unterstuetzt" ;
VAL_ 916 LRZ_Tourist_aktiv 1 "Tourist_Fkt_aktiv" 0 "Tourist_Fkt_deaktiv" ;
VAL_ 916 LRZ_AFS_Absch 1 "AFS_Deaktiv_unterstuetzt" 0 "keine_AFS_Deaktiv_n_unterst" ;
VAL_ 916 LRZ_AFS_deaktiv 1 "AFS_deaktiv" 0 "AFS_aktiv" ;
VAL_ 916 LRZ_Abbiegelicht_Dimm_Anf 1 "Dimmung_angefordert" 0 "keine_Dimmung" ;
VAL_ 916 LRZ_Abbiegelicht_li_Anf 1 "Abbiegelicht_ein" 0 "Abbiegelicht_aus" ;
VAL_ 916 LRZ_Abbiegelicht_re_Anf 1 "Abbiegelicht_ein" 0 "Abbiegelicht_aus" ;
VAL_ 916 LRZ_Fernlicht_li_defekt 1 "Fernlicht_defekt" 0 "Fernlicht_in_Ordnung" ;
VAL_ 916 LRZ_Fernlicht_re_defekt 1 "Fernlicht_defekt" 0 "Fernlicht_in_Ordnung" ;
VAL_ 916 LRZ_Fernlicht_Status 1 "Fernlicht_ein" 0 "Fernlicht_aus" ;
VAL_ 916 LRZ_Verfuegbarkeit_GLW 1 "GLW_verfuegbar" 0 "GLW_nicht_verfuegbar" ;
VAL_ 916 LRZ_Status_adaptive_LV 1 "adaptive_Lichtverteilung_an" 0 "adaptive_Lichtverteilung_aus" ;
VAL_ 916 GLW_Sensor_blockiert 1 "Kamera_Sensor_blockiert" 0 "Kamera_Sensor_nicht_blockiert" ;
VAL_ 916 AFS_Abblendlicht_li_defekt 1 "Abblendlicht_defekt" 0 "Abblendlicht_in_Ordnung" ;
VAL_ 916 AFS_Abblendlicht_re_defekt 1 "Abblendlicht_defekt" 0 "Abblendlicht_in_Ordnung" ;
VAL_ 1423 MO_ITM_Kuehlmittel_Temp 2 "Fehler" 1 "Init" 0 "nicht_verbaut" ;
VAL_ 1423 M12_E85_Sensor 15 "Fehler" 13 "nicht_verbaut" ;
VAL_ 1423 M12_SCR_Anz_Motorstarts 15 "keine_Einschraenkung" 14 "Fahrbarkeitseinschraenkung" ;
VAL_ 1423 M12_SCR_Reichweite 32767 "keine_Anzeige" ;
VAL_ 1423 SCR_Tankdeckel 1 "offen" 0 "geschlossen" ;
VAL_ 1423 M12_SCR_Warnstufe_1 1 "Warnstufe_1" ;
VAL_ 1423 M12_SCR_Warnstufe_2 1 "Warnstufe_2" ;
VAL_ 1423 M12_SCR_Text 7 "Hinweis_SysFehler" 6 "Sysfehler_2" 5 "SysFehler_1" 3 "Hinweis_Fuellstand" 2 "Warntext_2" 1 "Warntext_1" 0 "kein_Text" ;
VAL_ 1423 M12_Akustik 3 "Akustik_bei_Hinweis" 2 "Akustik_2" 1 "Akustik_1" 0 "keine_Akustik" ;
VAL_ 1423 M12_Luftfilter_Lampe 1 "Lampe_ein" 0 "Lampe_aus" ;
VAL_ 1423 M12_Kraftstofffilter_Wasser 1 "Abscheidevolumen_erschoepft" 0 "keine_Anzeige" ;
VAL_ 1423 M12_SCR_Systemfehler 1 "SCR_Systemfehler_aktiv" ;
VAL_ 1423 M12_SCR_Inducement 1 "Reduced_Drivability_Strategie" 0 "Restart_Strategie" ;
VAL_ 1423 M12_CO2_Faktor 4095 "Fehler" 0 "nicht_verbaut" ;
VAL_ 1423 M12_MKB_MUX 3 "MKB_04" 2 "MKB_03" 1 "MKB_02" 0 "MKB_01" ;
VAL_ 1423 MO_EDK_Luefter_defekt 1 "EDK_Luefter_defekt" 0 "keine_Warnung" ;
VAL_ 1423 M12_MKB_01 31 "Unterstrich" 30 "Leerzeichen" 29 "Leerzeichen" 28 "Leerzeichen" 27 "Leerzeichen" 26 "Z" 25 "Y" 24 "X" 23 "W" 22 "V" 21 "U" 20 "T" 19 "S" 18 "R" 17 "Q" 16 "P" 15 "O" 14 "N" 13 "M" 12 "L" 11 "K" 10 "J" 9 "I" 8 "H" 7 "G" 6 "F" 5 "E" 4 "D" 3 "C" 2 "B" 1 "A" 0 "Minus" ;
VAL_ 1423 M12_MKB_02 31 "Unterstrich" 30 "Leerzeichen" 29 "Leerzeichen" 28 "Leerzeichen" 27 "Leerzeichen" 26 "Z" 25 "Y" 24 "X" 23 "W" 22 "V" 21 "U" 20 "T" 19 "S" 18 "R" 17 "Q" 16 "P" 15 "O" 14 "N" 13 "M" 12 "L" 11 "K" 10 "J" 9 "I" 8 "H" 7 "G" 6 "F" 5 "E" 4 "D" 3 "C" 2 "B" 1 "A" 0 "Minus" ;
VAL_ 1423 M12_MKB_03 31 "Unterstrich" 30 "Leerzeichen" 29 "Leerzeichen" 28 "Leerzeichen" 27 "Leerzeichen" 26 "Z" 25 "Y" 24 "X" 23 "W" 22 "V" 21 "U" 20 "T" 19 "S" 18 "R" 17 "Q" 16 "P" 15 "O" 14 "N" 13 "M" 12 "L" 11 "K" 10 "J" 9 "I" 8 "H" 7 "G" 6 "F" 5 "E" 4 "D" 3 "C" 2 "B" 1 "A" 0 "Minus" ;
VAL_ 1423 M12_MKB_04 31 "Unterstrich" 30 "Leerzeichen" 29 "Leerzeichen" 28 "Leerzeichen" 27 "Leerzeichen" 26 "Z" 25 "Y" 24 "X" 23 "W" 22 "V" 21 "U" 20 "T" 19 "S" 18 "R" 17 "Q" 16 "P" 15 "O" 14 "N" 13 "M" 12 "L" 11 "K" 10 "J" 9 "I" 8 "H" 7 "G" 6 "F" 5 "E" 4 "D" 3 "C" 2 "B" 1 "A" 0 "Minus" ;
VAL_ 1450 MO_Ethanol_BS_Texte 6 "E25_Warm_Up" 5 "FlexFuel_Warnung_Stufe_4" 4 "FlexFuel_Warnung_Stufe_2" 3 "Warmfahrempfehlung_MQB__FlexFuel_Warnung_Stufe_1" 2 "FlexFuel_Warnung_Stufe_3" 1 "E85_Warm_Up" 0 "kein_Text" ;
VAL_ 1450 MO_Heizungspumpenansteuerung 15 "nicht_verbaut" 14 "Init" ;
VAL_ 1450 MO_Absperrventil_oeffnen 3 "Ventil_schliessen" 2 "Ventil_oeffnen" 1 "Ansteuerung_Ventil_zulaessig" 0 "nicht_verfuegbar" ;
VAL_ 1450 MO_aktives_Getriebeheizen 1 "Ventil_muss_angesteuert_werden" 0 "kein_Ventil_ansteuern" ;
VAL_ 1450 MO_Getriebe_kuehlen 1 "Ventil_oeffnen" 0 "Ventil_schliessen" ;
VAL_ 1450 MO_Zustand_HWP 3 "reserviert" 2 "HWP_foerdert" 1 "HWP_foerdert_nicht" 0 "HWP_nicht_schaltbar" ;
VAL_ 1450 MO_BKV_Unterdruckwarnung 1 "Unterdruckhaushalt_niO" 0 "Unterdruckhaushalt_iO" ;
VAL_ 1450 MO_Zylinderabschaltung 3 "Halbmotorbetrieb_HMB" 2 "Uebergang_VMB_in_HMB" 1 "Uebergang_HMB_in_VMB" 0 "Vollmotorbetrieb_VMB" ;
VAL_ 1450 MO_Heizstrom_SCR 63 "Fehler" ;
VAL_ 1450 MO_Heizstrom_EKAT 127 "Fehler" ;
VAL_ 1450 MO_Tankklappenstatus 7 "tbd" 6 "Tankvorgang_abgebrochen" 5 "Tankklappe_pruefen_schliessen" 4 "Tanksystem_Systemfehler" 3 "Tankbereitschaft_kann_nicht_hergestellt_werden" 2 "Tankbereitschaft_ist_hergestellt" 1 "Tankbereitschaft_wird_hergestellt" 0 "keine_Aktion_Init" ;
VAL_ 1450 MO_Tankklappensteuerung 3 "keine_Aktion" 2 "Tankklappe_soll_verriegeln" 1 "Tankklappe_soll_entriegeln" 0 "Init_oder_nicht_verbaut" ;
VAL_ 1450 MO_Zylabsch_Texte_02 15 "ZAS_Stoerungs_Anzeige" 14 "keine_ZAS_Anzeige_ggf_Stopp_Schub_Betrieb" 13 "Uebergangsbetrieb" 9 "ZAS_im_ASB_12_Zyl_aktiv" 8 "ZAS_im_ASB_8_Zyl_aktiv" 7 "ZAS_im_ASB_6_Zyl_aktiv" 6 "ZAS_im_ASB_5_Zyl_aktiv" 5 "ZAS_im_ASB_4_Zyl_aktiv" 4 "ZAS_im_ASB_3_Zyl_aktiv" 3 "ZAS_im_ASB_2_Zyl_aktiv" 2 "ZAS_im_ASB_1_Zyl_aktiv" 1 "ZAS_im_VMB" 0 "kein_ZAS_generell_keine_ZAS_Anzeigen" ;
VAL_ 1450 MO_EFLEX_Lampe 3 "Lampe_blinkend_mit_Akustik" 2 "Lampe_blinkend" 1 "Lampe_ein" 0 "Lampe_aus" ;
VAL_ 1450 MO_Testmode_AG 1 "Pruefstandsbetrieb" 0 "kein_Pruefstandsbetrieb" ;
VAL_ 1450 MO_Ext_E_Fahrt_aktiv 1 "Rueckmeldung_E_Taster_ein" 0 "Rueckmeldung_E_Taster_aus" ;
VAL_ 1450 MO_E85_WU_Lampe 1 "Ein" 0 "Aus" ;
VAL_ 1450 MO_E85_WU_Texte 1 "Anzeige_WU_Text" 0 "kein_Text" ;
VAL_ 1450 MO_Zylabsch_Texte 3 "Zylinderabsch_unruhig" 2 "Zylinderabsch_aktiv" 1 "Zylinderabsch_deakt" 0 "kein_Text" ;
VAL_ 1450 MO_E85_BS_Texte 3 "Flexfuel_Warnung_4" 2 "Flexfuel_Warnung_2" 1 "Flexfuel_Warnung_1" 0 "kein_Text" ;
VAL_ 1450 MO_StartStopp_Codiert 1 "Start_Stopp_verbaut" 0 "Start_Stopp_nicht_verbaut" ;
VAL_ 1407 MO_Charisma_FahrPr 7 "Programm_7" 6 "Programm_6" 5 "Programm_5" 4 "Programm_4" 3 "Programm_3" 2 "Programm_2" 1 "Programm_1" 0 "nicht_belegt" ;
VAL_ 1407 MO_Charisma_Status 3 "asynchron_durch_Fahrerwunsch" 2 "nicht_verfuegbar" 1 "verfuegbar" 0 "Init" ;
VAL_ 1407 GE_Charisma_FahrPr 7 "Programm_7" 6 "Programm_6" 5 "Programm_5" 4 "Programm_4" 3 "Programm_3" 2 "Programm_2" 1 "Programm_1" 0 "nicht_belegt" ;
VAL_ 1407 GE_Charisma_Status 3 "asynchron_durch_Fahrerwunsch" 2 "nicht_verfuegbar" 1 "verfuegbar" 0 "Init" ;
VAL_ 1407 EV_RekupStufe 5 "5" 4 "4" 3 "3" 2 "2" 1 "1" 0 "keine_Anzeige" ;
VAL_ 1407 MO_Bremslicht_Reku 1 "Ein" 0 "Aus" ;
VAL_ 1407 MO_UeberlVerb_EM 1 "mindestens_einmal_uebergelaufen" 0 "kein_Ueberlauf" ;
VAL_ 1407 MO_UeberlReku_EM 1 "mindestens_einmal_uebergelaufen" 0 "kein_Ueberlauf" ;
VAL_ 1407 MO_UeberlVerb_NA 1 "mindestens_einmal_uebergelaufen" 0 "kein_Ueberlauf" ;
